VERSION "2021.24.4"

NS_ :

BS_:

BU_: VEH CH Receiver X

BO_ 861 IBST_alertMatrix: 8 CH
 SG_ IBST_matrixIndex M: 0|4@1+ (1,0) [0|0] "" X
 SG_ IBST_a001_microSupplyError m0: 4|1@1+ (1,0) [0|0] "" X
 SG_ IBST_a002_HWBISTError m0: 5|1@1+ (1,0) [0|0] "" X
 SG_ IBST_a003_RAMFault m0: 6|1@1+ (1,0) [0|0] "" X
 SG_ IBST_a004_flashFault m0: 7|1@1+ (1,0) [0|0] "" X
 SG_ IBST_a005_microSafetyFault m0: 8|1@1+ (1,0) [0|0] "" X
 SG_ IBST_a006_microSafetyLogicFault m0: 9|1@1+ (1,0) [0|0] "" X
 SG_ IBST_a007_RBCPUException m0: 10|1@1+ (1,0) [0|0] "" X
 SG_ IBST_a008_stackOverUnderFlow m0: 11|1@1+ (1,0) [0|0] "" X
 SG_ IBST_a009_systemErrorHook m0: 12|1@1+ (1,0) [0|0] "" X
 SG_ IBST_a010_OSErrorHook m0: 13|1@1+ (1,0) [0|0] "" X
 SG_ IBST_a011_systemTaskOverRun m0: 14|1@1+ (1,0) [0|0] "" X
 SG_ IBST_a012_OSTaskSchemeError m0: 15|1@1+ (1,0) [0|0] "" X
 SG_ IBST_a013_systemTaskJitter m0: 16|1@1+ (1,0) [0|0] "" X
 SG_ IBST_a014_DMATransferError m0: 17|1@1+ (1,0) [0|0] "" X
 SG_ IBST_a015_asicOscillatorError m0: 18|1@1+ (1,0) [0|0] "" X
 SG_ IBST_a016_RBBLMShaftShiftError m0: 19|1@1+ (1,0) [0|0] "" X
 SG_ IBST_a017_assertionFault m0: 20|1@1+ (1,0) [0|0] "" X
 SG_ IBST_a018_unsupportedHW m0: 21|1@1+ (1,0) [0|0] "" X
 SG_ IBST_a019_supplyASICInitFault m0: 22|1@1+ (1,0) [0|0] "" X
 SG_ IBST_a020_VPREU5VOutOfRange m0: 23|1@1+ (1,0) [0|0] "" X
 SG_ IBST_a021_IREFOutOfRange m0: 24|1@1+ (1,0) [0|0] "" X
 SG_ IBST_a022_U5VTestFault m0: 25|1@1+ (1,0) [0|0] "" X
 SG_ IBST_a023_U5VOutOfRange m0: 26|1@1+ (1,0) [0|0] "" X
 SG_ IBST_a024_chargePumpFault m0: 27|1@1+ (1,0) [0|0] "" X
 SG_ IBST_a025_ecuClockTestFault m0: 28|1@1+ (1,0) [0|0] "" X
 SG_ IBST_a026_ecuBistCmdTestFault m0: 29|1@1+ (1,0) [0|0] "" X
 SG_ IBST_a027_ecuFastWdTestFault m0: 30|1@1+ (1,0) [0|0] "" X
 SG_ IBST_a028_ecuBistFaultCtrFault m0: 31|1@1+ (1,0) [0|0] "" X
 SG_ IBST_a029_ecuErrpinCounterFault m0: 32|1@1+ (1,0) [0|0] "" X
 SG_ IBST_a030_ecuEnableElLowFault m0: 33|1@1+ (1,0) [0|0] "" X
 SG_ IBST_a031_decoupleBitTestFault m0: 34|1@1+ (1,0) [0|0] "" X
 SG_ IBST_a032_ecuEnableElHighFault m0: 35|1@1+ (1,0) [0|0] "" X
 SG_ IBST_a033_ecuWdStartuptestFault m0: 36|1@1+ (1,0) [0|0] "" X
 SG_ IBST_a034_ecuEnableHyHighFault m0: 37|1@1+ (1,0) [0|0] "" X
 SG_ IBST_a035_ecuEnableHyLowFault m0: 38|1@1+ (1,0) [0|0] "" X
 SG_ IBST_a036_MRGPathTestFault m0: 39|1@1+ (1,0) [0|0] "" X
 SG_ IBST_a037_ecuWdSContinuousError m0: 40|1@1+ (1,0) [0|0] "" X
 SG_ IBST_a038_ecuEnContinuousError m0: 41|1@1+ (1,0) [0|0] "" X
 SG_ IBST_a039_GTMRefFrequencyError m0: 42|1@1+ (1,0) [0|0] "" X
 SG_ IBST_a040_GTMTbuMonError m0: 43|1@1+ (1,0) [0|0] "" X
 SG_ IBST_a041_micAsicClkInError m0: 44|1@1+ (1,0) [0|0] "" X
 SG_ IBST_a042_micAsicInitTestError m0: 45|1@1+ (1,0) [0|0] "" X
 SG_ IBST_a043_micSpiTransferError m0: 46|1@1+ (1,0) [0|0] "" X
 SG_ IBST_a044_NvMEepromWIP m0: 47|1@1+ (1,0) [0|0] "" X
 SG_ IBST_a045_WdhAsicWdErrorCntStuck m0: 48|1@1+ (1,0) [0|0] "" X
 SG_ IBST_a046_WdhAsicWdErrorCntLimit m0: 49|1@1+ (1,0) [0|0] "" X
 SG_ IBST_a047_WdhAsicWdCmdMissing m0: 50|1@1+ (1,0) [0|0] "" X
 SG_ IBST_a048_WdhSwBistConCnt m0: 51|1@1+ (1,0) [0|0] "" X
 SG_ IBST_a049_WdhTaskMonConCnt m0: 52|1@1+ (1,0) [0|0] "" X
 SG_ IBST_a050_VPreExternalFeeding m0: 53|1@1+ (1,0) [0|0] "" X
 SG_ IBST_a051_ecuBandgap m0: 54|1@1+ (1,0) [0|0] "" X
 SG_ IBST_a052_AdcPinTest m0: 55|1@1+ (1,0) [0|0] "" X
 SG_ IBST_a053_AdcSelftestC5P m0: 56|1@1+ (1,0) [0|0] "" X
 SG_ IBST_a054_AdcPeripheralFault m0: 57|1@1+ (1,0) [0|0] "" X
 SG_ IBST_a055_UB6SupplyPathFault m0: 58|1@1+ (1,0) [0|0] "" X
 SG_ IBST_a056_UB6PlausiMonFault m0: 59|1@1+ (1,0) [0|0] "" X
 SG_ IBST_a057_microRegisterFault m0: 60|1@1+ (1,0) [0|0] "" X
 SG_ IBST_a058_NvMWriteCycleExceed m0: 61|1@1+ (1,0) [0|0] "" X
 SG_ IBST_a059_NvMEepromSize m0: 62|1@1+ (1,0) [0|0] "" X
 SG_ IBST_a060_NvMMigrationFault m0: 63|1@1+ (1,0) [0|0] "" X
 SG_ IBST_a061_AswSystemTimeOut m1: 4|1@1+ (1,0) [0|0] "" X
 SG_ IBST_a062_MICB6TransferError m1: 5|1@1+ (1,0) [0|0] "" X
 SG_ IBST_a063_tempSens2ShortToSupply m1: 6|1@1+ (1,0) [0|0] "" X
 SG_ IBST_a064_tempSens1ShortToGround m1: 7|1@1+ (1,0) [0|0] "" X
 SG_ IBST_a065_tempSens2ShortToGround m1: 8|1@1+ (1,0) [0|0] "" X
 SG_ IBST_a066_tempSens1ShortToSupply m1: 9|1@1+ (1,0) [0|0] "" X
 SG_ IBST_a067_tempSensImplausVoltage m1: 10|1@1+ (1,0) [0|0] "" X
 SG_ IBST_a068_chargePumpUndervoltage m1: 11|1@1+ (1,0) [0|0] "" X
 SG_ IBST_a069_greasingRoutineFault m1: 12|1@1+ (1,0) [0|0] "" X
 SG_ IBST_a070_notShutDownNvMWrite m1: 13|1@1+ (1,0) [0|0] "" X
 SG_ IBST_a071_notShutDownNvMRead m1: 14|1@1+ (1,0) [0|0] "" X
 SG_ IBST_a072_notShutDownRight m1: 15|1@1+ (1,0) [0|0] "" X
 SG_ IBST_a073_jumpInAdjustNvMRead m1: 16|1@1+ (1,0) [0|0] "" X
 SG_ IBST_a074_FindIdleDataNvMWrite m1: 17|1@1+ (1,0) [0|0] "" X
 SG_ IBST_a075_FindIdleRoutineFault m1: 18|1@1+ (1,0) [0|0] "" X
 SG_ IBST_a076_masterCylLengthRead m1: 19|1@1+ (1,0) [0|0] "" X
 SG_ IBST_a077_runOutMotorSaturated m1: 20|1@1+ (1,0) [0|0] "" X
 SG_ IBST_a078_wearOffsetCompNVMRead m1: 21|1@1+ (1,0) [0|0] "" X
 SG_ IBST_a079_motorTempHighLevel1 m1: 22|1@1+ (1,0) [0|0] "" X
 SG_ IBST_a080_motorTempHighLevel2 m1: 23|1@1+ (1,0) [0|0] "" X
 SG_ IBST_a081_travelDeviation m1: 24|1@1+ (1,0) [0|0] "" X
 SG_ IBST_a082_motorSpeedDeviation m1: 25|1@1+ (1,0) [0|0] "" X
 SG_ IBST_a083_spindlePositionTooHigh m1: 26|1@1+ (1,0) [0|0] "" X
 SG_ IBST_a084_CANTransceiverHWFault m1: 27|1@1+ (1,0) [0|0] "" X
 SG_ IBST_a085_supplyUndervoltageLvl3 m1: 28|1@1+ (1,0) [0|0] "" X
 SG_ IBST_a086_supplyOvervoltageLvl3 m1: 29|1@1+ (1,0) [0|0] "" X
 SG_ IBST_a087_rotorSinOutOfRangeLow m1: 30|1@1+ (1,0) [0|0] "" X
 SG_ IBST_a088_rotorCosOutOfRangeLow m1: 31|1@1+ (1,0) [0|0] "" X
 SG_ IBST_a089_rotorSinOutOfRangeHigh m1: 32|1@1+ (1,0) [0|0] "" X
 SG_ IBST_a090_rotorCosOutOfRangeHigh m1: 33|1@1+ (1,0) [0|0] "" X
 SG_ IBST_a091_SMMOneRequestsInit m1: 34|1@1+ (1,0) [0|0] "" X
 SG_ IBST_a092_systemStartTimeOut m1: 35|1@1+ (1,0) [0|0] "" X
 SG_ IBST_a093_UEXSOvertemperature m1: 36|1@1+ (1,0) [0|0] "" X
 SG_ IBST_a094_XPASSEchoTimeDeviation m1: 37|1@1+ (1,0) [0|0] "" X
 SG_ IBST_a095_XPASSTimeOut m1: 38|1@1+ (1,0) [0|0] "" X
 SG_ IBST_a096_bridgeDriverMonError m1: 39|1@1+ (1,0) [0|0] "" X
 SG_ IBST_a097_bridgeDriverError m1: 40|1@1+ (1,0) [0|0] "" X
 SG_ IBST_a098_bridgeShortedPhase m1: 41|1@1+ (1,0) [0|0] "" X
 SG_ IBST_a099_bridgeSwitchInitError m1: 42|1@1+ (1,0) [0|0] "" X
 SG_ IBST_a100_current2OffsVEHigh m1: 43|1@1+ (1,0) [0|0] "" X
 SG_ IBST_a101_current2OffsetLow m1: 44|1@1+ (1,0) [0|0] "" X
 SG_ IBST_a102_current1OffsVEHigh m1: 45|1@1+ (1,0) [0|0] "" X
 SG_ IBST_a103_current1OffsetLow m1: 46|1@1+ (1,0) [0|0] "" X
 SG_ IBST_a104_bridgeDriverShort m1: 47|1@1+ (1,0) [0|0] "" X
 SG_ IBST_a105_LiPSUndervoltage m1: 48|1@1+ (1,0) [0|0] "" X
 SG_ IBST_a106_LiPS5VSupply m1: 49|1@1+ (1,0) [0|0] "" X
 SG_ IBST_a107_LiPS2PwmLineHigh m1: 50|1@1+ (1,0) [0|0] "" X
 SG_ IBST_a108_LiPS2PwmLineLow m1: 51|1@1+ (1,0) [0|0] "" X
 SG_ IBST_a109_LiPS2PwmTransmission m1: 52|1@1+ (1,0) [0|0] "" X
 SG_ IBST_a110_LiPS1SentLineHigh m1: 53|1@1+ (1,0) [0|0] "" X
 SG_ IBST_a111_LiPS1SentLineLow m1: 54|1@1+ (1,0) [0|0] "" X
 SG_ IBST_a112_LiPS1SentTransmission m1: 55|1@1+ (1,0) [0|0] "" X
 SG_ IBST_a113_LiPS1SentSensor m1: 56|1@1+ (1,0) [0|0] "" X
 SG_ IBST_a114_partyBusOff m1: 57|1@1+ (1,0) [0|0] "" X
 SG_ IBST_a115_CHOff m1: 58|1@1+ (1,0) [0|0] "" X
 SG_ IBST_a116_supplyUndervoltageLvl2 m1: 59|1@1+ (1,0) [0|0] "" X
 SG_ IBST_a117_supplyOvervoltageLvl2 m1: 60|1@1+ (1,0) [0|0] "" X
 SG_ IBST_a118_RPSNvMReadFault m1: 61|1@1+ (1,0) [0|0] "" X
 SG_ IBST_a119_RPSWrongCalibData m1: 62|1@1+ (1,0) [0|0] "" X
 SG_ IBST_a120_RPSVectorRangeHigh m1: 63|1@1+ (1,0) [0|0] "" X
 SG_ IBST_a121_RPSVectorRangeLow m2: 4|1@1+ (1,0) [0|0] "" X
 SG_ IBST_a122_RPSVectorOscillating m2: 5|1@1+ (1,0) [0|0] "" X
 SG_ IBST_a123_bridgeDriverUnavail m2: 6|1@1+ (1,0) [0|0] "" X
 SG_ IBST_a124_OBDCurrent1OORHigh m2: 7|1@1+ (1,0) [0|0] "" X
 SG_ IBST_a125_OBDCurrent2OORHigh m2: 8|1@1+ (1,0) [0|0] "" X
 SG_ IBST_a126_OBDCurrent1OORLow m2: 9|1@1+ (1,0) [0|0] "" X
 SG_ IBST_a127_OBDCurrent2OORLow m2: 10|1@1+ (1,0) [0|0] "" X
 SG_ IBST_a128_BLMMuxerTimeoutError m2: 11|1@1+ (1,0) [0|0] "" X
 SG_ IBST_a129_loadDumpOnFSLTest m2: 12|1@1+ (1,0) [0|0] "" X
 SG_ IBST_a130_DTSFunctionalRangeLow m2: 13|1@1+ (1,0) [0|0] "" X
 SG_ IBST_a131_DTSFunctionalRangeHigh m2: 14|1@1+ (1,0) [0|0] "" X
 SG_ IBST_a132_DTSPlausiCheck1vs2 m2: 15|1@1+ (1,0) [0|0] "" X
 SG_ IBST_a133_DTSOffsetTooLow m2: 16|1@1+ (1,0) [0|0] "" X
 SG_ IBST_a134_DTSOffsetTooHigh m2: 17|1@1+ (1,0) [0|0] "" X
 SG_ IBST_a135_ESPparty1DLC m2: 18|1@1+ (1,0) [0|0] "" X
 SG_ IBST_a136_ESPparty1Timeout m2: 19|1@1+ (1,0) [0|0] "" X
 SG_ IBST_a137_ESPparty1Checksum m2: 20|1@1+ (1,0) [0|0] "" X
 SG_ IBST_a138_ESPparty1Counter m2: 21|1@1+ (1,0) [0|0] "" X
 SG_ IBST_a139_ESPparty2DLC m2: 22|1@1+ (1,0) [0|0] "" X
 SG_ IBST_a140_ESPparty2Timeout m2: 23|1@1+ (1,0) [0|0] "" X
 SG_ IBST_a141_ESPparty2Checksum m2: 24|1@1+ (1,0) [0|0] "" X
 SG_ IBST_a142_ESPparty2Counter m2: 25|1@1+ (1,0) [0|0] "" X
 SG_ IBST_a143_ESPparty3DLC m2: 26|1@1+ (1,0) [0|0] "" X
 SG_ IBST_a144_ESPparty3Timeout m2: 27|1@1+ (1,0) [0|0] "" X
 SG_ IBST_a145_ESPparty3Checksum m2: 28|1@1+ (1,0) [0|0] "" X
 SG_ IBST_a146_ESPparty3Counter m2: 29|1@1+ (1,0) [0|0] "" X
 SG_ IBST_a147_PSCMotorSizeReadFault m2: 30|1@1+ (1,0) [0|0] "" X
 SG_ IBST_a148_MLIGainMechReadFault m2: 31|1@1+ (1,0) [0|0] "" X
 SG_ IBST_a149_MLITMCAreaReadFault m2: 32|1@1+ (1,0) [0|0] "" X
 SG_ IBST_a150_motorTestFault m2: 33|1@1+ (1,0) [0|0] "" X
 SG_ IBST_a151_PSCGearRatioReadFault m2: 34|1@1+ (1,0) [0|0] "" X
 SG_ IBST_a152_PSCVoltageImplausible m2: 35|1@1+ (1,0) [0|0] "" X
 SG_ IBST_a153_PSCImpedanceTooHigh m2: 36|1@1+ (1,0) [0|0] "" X
 SG_ IBST_a154_PSCImpedanceTooLow m2: 37|1@1+ (1,0) [0|0] "" X
 SG_ IBST_a155_supplyUndervoltageLvl1 m2: 38|1@1+ (1,0) [0|0] "" X
 SG_ IBST_a156_supplyOvervoltageLvl1 m2: 39|1@1+ (1,0) [0|0] "" X
 SG_ IBST_a157_masterCylPressInvalid m2: 40|1@1+ (1,0) [0|0] "" X
 SG_ IBST_a158_DTSOffsHighSuspicious m2: 41|1@1+ (1,0) [0|0] "" X
 SG_ IBST_a159_FindIdleNvMReadError m2: 42|1@1+ (1,0) [0|0] "" X
 SG_ IBST_a160_DTSIDTimeOut m2: 43|1@1+ (1,0) [0|0] "" X
 SG_ IBST_a161_powerPackMismatch m2: 44|1@1+ (1,0) [0|0] "" X
 SG_ IBST_a162_idlePosNotDetected m2: 45|1@1+ (1,0) [0|0] "" X
 SG_ IBST_a163_ESPpEstMaxInvalid m2: 46|1@1+ (1,0) [0|0] "" X
 SG_ IBST_a164_ESPVehicleSpeedInvalid m2: 47|1@1+ (1,0) [0|0] "" X
 SG_ IBST_a165_ESPpForceBlendInvalid m2: 48|1@1+ (1,0) [0|0] "" X
 SG_ IBST_a166_ESPpMcVirtualInvalid m2: 49|1@1+ (1,0) [0|0] "" X
 SG_ IBST_a167_ESPqTargetExterInvalid m2: 50|1@1+ (1,0) [0|0] "" X
 SG_ IBST_a168_CANOvervoltage m2: 51|1@1+ (1,0) [0|0] "" X
 SG_ IBST_a169_CANUndervoltage m2: 52|1@1+ (1,0) [0|0] "" X
 SG_ IBST_a170_LVPowerStateTimeout m2: 53|1@1+ (1,0) [0|0] "" X
 SG_ IBST_a171_LVPowerStateChecksum m2: 54|1@1+ (1,0) [0|0] "" X
 SG_ IBST_a172_LVPowerStateDLC m2: 55|1@1+ (1,0) [0|0] "" X
 SG_ IBST_a173_LVPowerStateCounter m2: 56|1@1+ (1,0) [0|0] "" X
 SG_ IBST_a174_LVOffStateInvalid m2: 57|1@1+ (1,0) [0|0] "" X
 SG_ IBST_a175_LVGoingDownInvalid m2: 58|1@1+ (1,0) [0|0] "" X

BO_ 813 IBST_info: 8 CH
 SG_ IBST_infoIndex M: 0|8@1+ (1,0) [0|0] "" X
 SG_ IBST_infoBuildType m10: 8|8@1+ (1,0) [0|0] "" X
 SG_ IBST_infoComponentID m10: 48|16@1+ (1,0) [0|0] "" X
 SG_ IBST_infoPcbaID m11: 16|8@1+ (1,0) [0|0] "" X
 SG_ IBST_infoAssemblyID m11: 24|8@1+ (1,0) [0|0] "" X
 SG_ IBST_infoUsageID m11: 32|16@1+ (1,0) [0|0] "" X
 SG_ IBST_infoBootUdsProtoVersion m20: 8|8@1+ (1,0) [0|0] "" X
 SG_ IBST_infoBootloaderCRC m20: 32|32@1+ (1,0) [0|0] "" X
 SG_ IBST_infoApplicationCRC m13: 32|32@1+ (1,0) [0|0] "" X
 SG_ IBST_infoVariantCRC m22: 32|32@1+ (1,0) [0|0] "" X

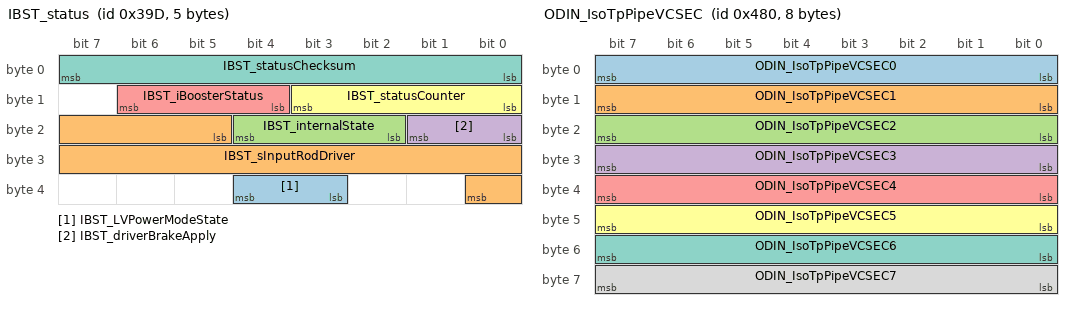
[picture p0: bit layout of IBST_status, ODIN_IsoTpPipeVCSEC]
BO_ 925 IBST_status: 5 Vector__XXX
 SG_ IBST_LVPowerModeState : 35|2@1+ (1,0) [0|0] "" Vector__XXX
 SG_ IBST_sInputRodDriver : 21|12@1+ (0.015625,-5) [0|0] "" Vector__XXX
 SG_ IBST_internalState : 18|3@1+ (1,0) [0|0] "" Vector__XXX
 SG_ IBST_driverBrakeApply : 16|2@1+ (1,0) [0|0] "" Vector__XXX
 SG_ IBST_iBoosterStatus : 12|3@1+ (1,0) [0|0] "" Vector__XXX
 SG_ IBST_statusCounter : 8|4@1+ (1,0) [0|0] "" Vector__XXX
 SG_ IBST_statusChecksum : 0|8@1+ (1,0) [0|0] "" Vector__XXX

BO_ 771 VCRIGHT_info: 8 Vector__XXX
 SG_ VCRIGHT_infoComponentId m10 : 48|16@1+ (1,0) [0|0] "" Vector__XXX
 SG_ VCRIGHT_infoSubUsageId m11 : 40|16@1+ (1,0) [0|0] "" Vector__XXX
 SG_ VCRIGHT_infoHardwareId m10 : 32|16@1+ (1,0) [0|0] "" Vector__XXX
 SG_ VCRIGHT_infoLUMBARRAppCRC m16 : 32|32@1+ (1,0) [0|0] "" Vector__XXX
 SG_ VCRIGHT_infoSubcomponent3 m24 : 32|32@1+ (1,0) [0|0] "" Vector__XXX
 SG_ VCRIGHT_infoSubcomponent4 m31 : 32|32@1+ (1,0) [0|0] "" Vector__XXX
 SG_ VCRIGHT_infoSubcomponent5 m32 : 32|32@1+ (1,0) [0|0] "" Vector__XXX
 SG_ VCRIGHT_infoSubcomponent6 m33 : 32|32@1+ (1,0) [0|0] "" Vector__XXX
 SG_ VCRIGHT_thsAppCRC m23 : 32|32@1+ (1,0) [0|0] "" Vector__XXX
 SG_ VCRIGHT_infoBootCrc m20 : 24|32@1+ (1,0) [0|0] "" Vector__XXX
 SG_ VCRIGHT_infoUsageId m11 : 24|16@1+ (1,0) [0|0] "" Vector__XXX
 SG_ VCRIGHT_infoAssemblyId m11 : 16|8@1+ (1,0) [0|0] "" Vector__XXX
 SG_ VCRIGHT_infoBuildConfigId m10 : 16|16@1+ (1,0) [0|0] "" Vector__XXX
 SG_ VCRIGHT_infoAppCrc m13 : 8|32@1+ (1,0) [0|0] "" Vector__XXX
 SG_ VCRIGHT_infoAppGitHash m17 : 8|56@1+ (1,0) [0|0] "" Vector__XXX
 SG_ VCRIGHT_infoBootGitHash m18 : 8|56@1+ (1,0) [0|0] "" Vector__XXX
 SG_ VCRIGHT_infoBootUdsProtoVersion m20 : 8|16@1+ (1,0) [0|0] "" Vector__XXX
 SG_ VCRIGHT_infoBuildType m10 : 8|3@1+ (1,0) [0|0] "" Vector__XXX
 SG_ VCRIGHT_infoPcbaId m11 : 8|8@1+ (1,0) [0|0] "" Vector__XXX
 SG_ VCRIGHT_infoPlatformType m19 : 8|8@1+ (1,0) [0|0] "" Vector__XXX
 SG_ VCRIGHT_infoIndex M : 0|8@1+ (1,0) [0|0] "" Vector__XXX

BO_ 1152 ODIN_IsoTpPipeVCSEC: 8 VEH
 SG_ ODIN_IsoTpPipeVCSEC0: 0|8@1+ (1,0) [0|0] "" X
 SG_ ODIN_IsoTpPipeVCSEC1: 8|8@1+ (1,0) [0|0] "" X
 SG_ ODIN_IsoTpPipeVCSEC2: 16|8@1+ (1,0) [0|0] "" X
 SG_ ODIN_IsoTpPipeVCSEC3: 24|8@1+ (1,0) [0|0] "" X
 SG_ ODIN_IsoTpPipeVCSEC4: 32|8@1+ (1,0) [0|0] "" X
 SG_ ODIN_IsoTpPipeVCSEC5: 40|8@1+ (1,0) [0|0] "" X
 SG_ ODIN_IsoTpPipeVCSEC6: 48|8@1+ (1,0) [0|0] "" X
 SG_ ODIN_IsoTpPipeVCSEC7: 56|8@1+ (1,0) [0|0] "" X

BO_ 806 PARK_info: 8 CH
 SG_ PARK_infoIndex M: 0|8@1+ (1,0) [0|0] "" X
 SG_ PARK_infoBuildType m10: 8|8@1+ (1,0) [0|0] "" X
 SG_ PARK_infoComponentID m10: 48|16@1+ (1,0) [0|0] "" X
 SG_ PARK_infoPcbaID m11: 16|8@1+ (1,0) [0|0] "" X
 SG_ PARK_infoAssemblyID m11: 24|8@1+ (1,0) [0|0] "" X
 SG_ PARK_infoUsageID m11: 32|16@1+ (1,0) [0|0] "" X
 SG_ PARK_infoBootUdsProtoVersion m20: 8|8@1+ (1,0) [0|0] "" X
 SG_ PARK_infoBootloaderCRC m20: 32|32@1+ (1,0) [0|0] "" X
 SG_ PARK_infoApplicationCRC m13: 32|32@1+ (1,0) [0|0] "" X

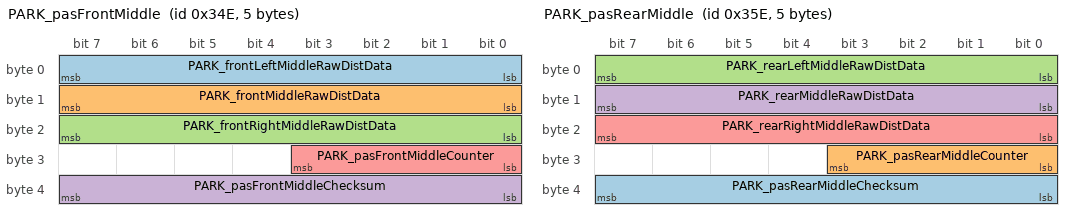
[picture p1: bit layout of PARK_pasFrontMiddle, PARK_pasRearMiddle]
BO_ 846 PARK_pasFrontMiddle: 5 CH
 SG_ PARK_frontLeftMiddleRawDistData: 0|8@1+ (1,0) [0|0] "cm" X
 SG_ PARK_frontMiddleRawDistData: 8|8@1+ (1,0) [0|0] "cm" X
 SG_ PARK_frontRightMiddleRawDistData: 16|8@1+ (1,0) [0|0] "cm" X
 SG_ PARK_pasFrontMiddleChecksum: 32|8@1+ (1,0) [0|0] "" X
 SG_ PARK_pasFrontMiddleCounter: 24|4@1+ (1,0) [0|0] "" X

BO_ 862 PARK_pasRearMiddle: 5 CH
 SG_ PARK_pasRearMiddleChecksum: 32|8@1+ (1,0) [0|0] "" X
 SG_ PARK_pasRearMiddleCounter: 24|4@1+ (1,0) [0|0] "" X
 SG_ PARK_rearLeftMiddleRawDistData: 0|8@1+ (1,0) [0|0] "cm" X
 SG_ PARK_rearMiddleRawDistData: 8|8@1+ (1,0) [0|0] "cm" X
 SG_ PARK_rearRightMiddleRawDistData: 16|8@1+ (1,0) [0|0] "cm" X

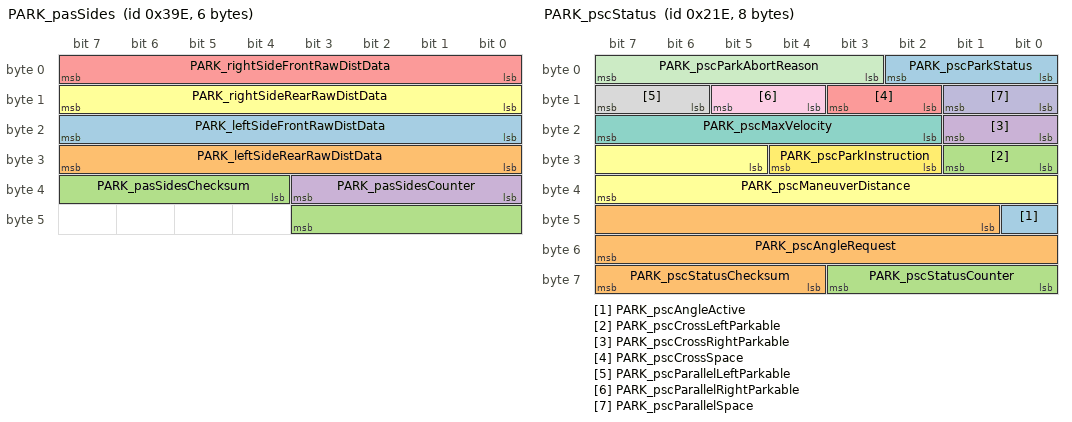
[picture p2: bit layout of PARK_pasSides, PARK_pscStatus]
BO_ 926 PARK_pasSides: 6 CH
 SG_ PARK_leftSideFrontRawDistData: 16|8@1+ (1,0) [0|0] "cm" X
 SG_ PARK_leftSideRearRawDistData: 24|8@1+ (1,0) [0|0] "cm" X
 SG_ PARK_pasSidesChecksum: 36|8@1+ (1,0) [0|0] "" X
 SG_ PARK_pasSidesCounter: 32|4@1+ (1,0) [0|0] "" X
 SG_ PARK_rightSideFrontRawDistData: 0|8@1+ (1,0) [0|0] "cm" X
 SG_ PARK_rightSideRearRawDistData: 8|8@1+ (1,0) [0|0] "cm" X

BO_ 606 PARK_pscEnvSlot: 8 CH
 SG_ PARK_pscEnvSlotType M: 0|2@1+ (1,0) [0|0] "" X
 SG_ PARK_pscLeftParallelObj1X m0: 3|11@1+ (2,-2048) [0|0] "cm" X
 SG_ PARK_pscLeftParallelObj1Y m0: 14|11@1+ (2,-2048) [0|0] "cm" X
 SG_ PARK_pscLeftParallelObj1Alpha m0: 25|7@1+ (2,-128) [0|0] "deg" X
 SG_ PARK_pscLeftParallelObj2Y m0: 35|11@1+ (2,-2048) [0|0] "cm" X
 SG_ PARK_pscLeftParallelObj2X m0: 46|11@1+ (2,-2048) [0|0] "cm" X
 SG_ PARK_pscLeftParallelObj2Alpha m0: 57|7@1+ (2,-128) [0|0] "deg" X
 SG_ PARK_pscLeftCrossObj1X m1: 3|11@1+ (2,-2048) [0|0] "cm" X
 SG_ PARK_pscLeftCrossObj1Y m1: 14|11@1+ (2,-2048) [0|0] "cm" X
 SG_ PARK_pscLeftCrossObj1Alpha m1: 25|7@1+ (2,-128) [0|0] "deg" X
 SG_ PARK_pscLeftCrossObj2Y m1: 35|11@1+ (2,-2048) [0|0] "cm" X
 SG_ PARK_pscLeftCrossObj2X m1: 46|11@1+ (2,-2048) [0|0] "cm" X
 SG_ PARK_pscLeftCrossObj2Alpha m1: 57|7@1+ (2,-128) [0|0] "deg" X
 SG_ PARK_pscRightParallelObj1X m2: 3|11@1+ (2,-2048) [0|0] "cm" X
 SG_ PARK_pscRightParallelObj1Y m2: 14|11@1+ (2,-2048) [0|0] "cm" X
 SG_ PARK_pscRightParallelObj1Alpha m2: 25|7@1+ (2,-128) [0|0] "deg" X
 SG_ PARK_pscRightParallelObj2Y m2: 35|11@1+ (2,-2048) [0|0] "cm" X
 SG_ PARK_pscRightParallelObj2X m2: 46|11@1+ (2,-2048) [0|0] "cm" X
 SG_ PARK_pscRightParallelObj2Alpha m2: 57|7@1+ (2,-128) [0|0] "deg" X
 SG_ PARK_pscRightCrossObj1X m3: 3|11@1+ (2,-2048) [0|0] "cm" X
 SG_ PARK_pscRightCrossObj1Y m3: 14|11@1+ (2,-2048) [0|0] "cm" X
 SG_ PARK_pscRightCrossObj1Alpha m3: 25|7@1+ (2,-128) [0|0] "deg" X
 SG_ PARK_pscRightCrossObj2Y m3: 35|11@1+ (2,-2048) [0|0] "cm" X
 SG_ PARK_pscRightCrossObj2X m3: 46|11@1+ (2,-2048) [0|0] "cm" X
 SG_ PARK_pscRightCrossObj2Alpha m3: 57|7@1+ (2,-128) [0|0] "deg" X

BO_ 542 PARK_pscStatus: 8 VEH
 SG_ PARK_pscAngleActive: 40|1@1+ (1,0) [0|0] "" X
 SG_ PARK_pscAngleRequest: 41|15@1+ (0.1,-1638.4) [0|0] "deg" X
 SG_ PARK_pscCrossLeftParkable: 24|2@1+ (1,0) [0|0] "" X
 SG_ PARK_pscCrossRightParkable: 16|2@1+ (1,0) [0|0] "" X
 SG_ PARK_pscCrossSpace: 10|2@1+ (1,0) [0|0] "" X
 SG_ PARK_pscManeuverDistance: 29|11@1+ (1,0) [0|0] "cm" X
 SG_ PARK_pscMaxVelocity: 18|6@1+ (0.1,0) [0|0] "kph" X
 SG_ PARK_pscParallelLeftParkable: 14|2@1+ (1,0) [0|0] "" X
 SG_ PARK_pscParallelRightParkable: 12|2@1+ (1,0) [0|0] "" X
 SG_ PARK_pscParallelSpace: 8|2@1+ (1,0) [0|0] "" X
 SG_ PARK_pscParkAbortReason: 3|5@1+ (1,0) [0|0] "" X
 SG_ PARK_pscParkInstruction: 26|3@1+ (1,0) [0|0] "" X
 SG_ PARK_pscParkStatus: 0|3@1+ (1,0) [0|0] "" X
 SG_ PARK_pscStatusChecksum: 60|4@1+ (1,0) [0|0] "" X
 SG_ PARK_pscStatusCounter: 56|4@1+ (1,0) [0|0] "" X

BO_ 590 PARK_pscVehSlot: 8 CH
 SG_ PARK_pscVehSlotType M: 0|2@1+ (1,0) [0|0] "" X
 SG_ PARK_pscLeftParallelVehX m0: 5|11@1+ (2,-2048) [0|0] "cm" X
 SG_ PARK_pscLeftParallelVehY m0: 16|11@1+ (2,-2048) [0|0] "cm" X
 SG_ PARK_pscLeftParallelPsi m0: 32|13@1+ (0.000976563,0) [0|0] "radians" X
 SG_ PARK_pscLeftParallelSizeX m0: 48|8@1+ (4,0) [0|0] "cm" X
 SG_ PARK_pscLeftParallelSizeY m0: 56|8@1+ (4,0) [0|0] "cm" X
 SG_ PARK_pscLeftCrossVehX m1: 5|11@1+ (2,-2048) [0|0] "cm" X
 SG_ PARK_pscLeftCrossVehY m1: 16|11@1+ (2,-2048) [0|0] "cm" X
 SG_ PARK_pscLeftCrossPsi m1: 32|13@1+ (0.000976563,0) [0|0] "radians" X
 SG_ PARK_pscLeftCrossSizeX m1: 48|8@1+ (4,0) [0|0] "cm" X
 SG_ PARK_pscLeftCrossSizeY m1: 56|8@1+ (4,0) [0|0] "cm" X
 SG_ PARK_pscRightParallelVehX m2: 5|11@1+ (2,-2048) [0|0] "cm" X
 SG_ PARK_pscRightParallelVehY m2: 16|11@1+ (2,-2048) [0|0] "cm" X
 SG_ PARK_pscRightParallelPsi m2: 32|13@1+ (0.000976563,0) [0|0] "radians" X
 SG_ PARK_pscRightParallelSizeX m2: 48|8@1+ (4,0) [0|0] "cm" X
 SG_ PARK_pscRightParallelSizeY m2: 56|8@1+ (4,0) [0|0] "cm" X
 SG_ PARK_pscRightCrossVehX m3: 5|11@1+ (2,-2048) [0|0] "cm" X
 SG_ PARK_pscRightCrossVehY m3: 16|11@1+ (2,-2048) [0|0] "cm" X
 SG_ PARK_pscRightCrossPsi m3: 32|13@1+ (0.000976563,0) [0|0] "radians" X
 SG_ PARK_pscRightCrossSizeX m3: 48|8@1+ (4,0) [0|0] "cm" X
 SG_ PARK_pscRightCrossSizeY m3: 56|8@1+ (4,0) [0|0] "cm" X

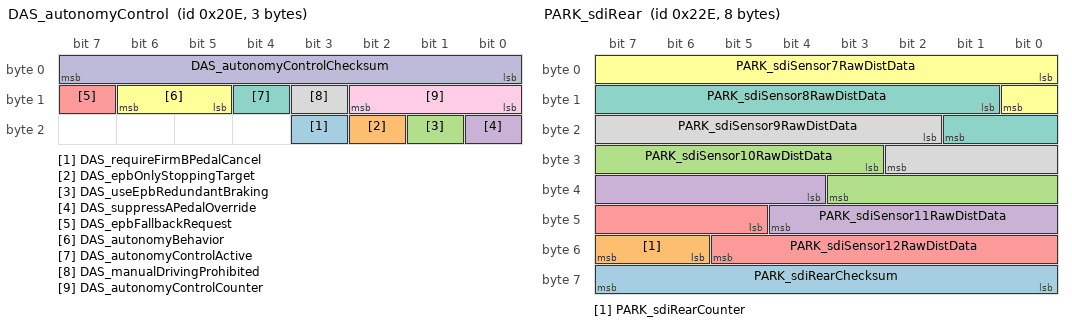
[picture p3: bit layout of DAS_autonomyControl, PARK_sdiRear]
BO_ 526 DAS_autonomyControl: 3 Vector__XXX
 SG_ DAS_requireFirmBPedalCancel : 19|1@1+ (1,0) [0|0] "" Vector__XXX
 SG_ DAS_epbOnlyStoppingTarget : 18|1@1+ (1,0) [0|0] "" Vector__XXX
 SG_ DAS_useEpbRedundantBraking : 17|1@1+ (1,0) [0|0] "" Vector__XXX
 SG_ DAS_suppressAPedalOverride : 16|1@1+ (1,0) [0|0] "" Vector__XXX
 SG_ DAS_epbFallbackRequest : 15|1@1+ (1,0) [0|0] "" Vector__XXX
 SG_ DAS_autonomyBehavior : 13|2@1+ (1,0) [0|0] "" Vector__XXX
 SG_ DAS_autonomyControlActive : 12|1@1+ (1,0) [0|0] "" Vector__XXX
 SG_ DAS_manualDrivingProhibited : 11|1@1+ (1,0) [0|0] "" Vector__XXX
 SG_ DAS_autonomyControlCounter : 8|3@1+ (1,0) [0|0] "" Vector__XXX
 SG_ DAS_autonomyControlChecksum : 0|8@1+ (1,0) [0|0] "" Vector__XXX

BO_ 558 PARK_sdiRear: 8 CH
 SG_ PARK_sdiRearChecksum: 56|8@1+ (1,0) [0|0] "" X
 SG_ PARK_sdiRearCounter: 54|2@1+ (1,0) [0|0] "" X
 SG_ PARK_sdiSensor10RawDistData: 27|9@1+ (1,0) [0|0] "cm" X
 SG_ PARK_sdiSensor11RawDistData: 36|9@1+ (1,0) [0|0] "cm" X
 SG_ PARK_sdiSensor12RawDistData: 45|9@1+ (1,0) [0|0] "cm" X
 SG_ PARK_sdiSensor7RawDistData: 0|9@1+ (1,0) [0|0] "cm" X
 SG_ PARK_sdiSensor8RawDistData: 9|9@1+ (1,0) [0|0] "cm" X
 SG_ PARK_sdiSensor9RawDistData: 18|9@1+ (1,0) [0|0] "cm" X

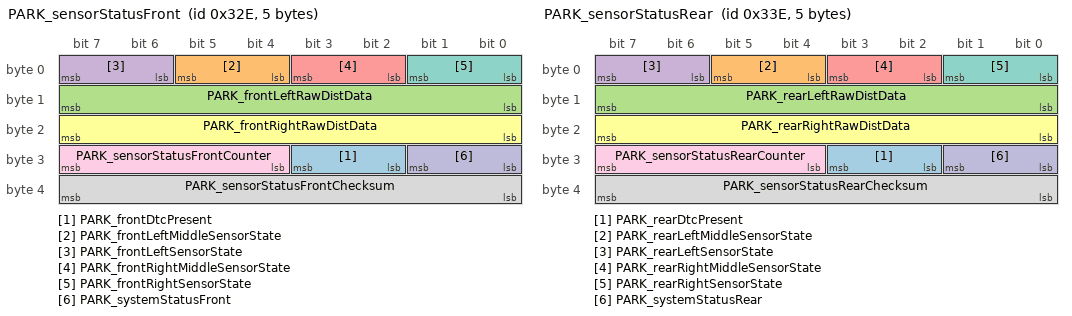
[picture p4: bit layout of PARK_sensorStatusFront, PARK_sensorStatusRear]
BO_ 814 PARK_sensorStatusFront: 5 CH
 SG_ PARK_frontDtcPresent: 26|2@1+ (1,0) [0|0] "" X
 SG_ PARK_frontLeftMiddleSensorState: 4|2@1+ (1,0) [0|0] "" X
 SG_ PARK_frontLeftRawDistData: 8|8@1+ (1,0) [0|0] "cm" X
 SG_ PARK_frontLeftSensorState: 6|2@1+ (1,0) [0|0] "" X
 SG_ PARK_frontRightMiddleSensorState: 2|2@1+ (1,0) [0|0] "" X
 SG_ PARK_frontRightRawDistData: 16|8@1+ (1,0) [0|0] "cm" X
 SG_ PARK_frontRightSensorState: 0|2@1+ (1,0) [0|0] "" X
 SG_ PARK_sensorStatusFrontChecksum: 32|8@1+ (1,0) [0|0] "" X
 SG_ PARK_sensorStatusFrontCounter: 28|4@1+ (1,0) [0|0] "" X
 SG_ PARK_systemStatusFront: 24|2@1+ (1,0) [0|0] "" X

BO_ 830 PARK_sensorStatusRear: 5 CH
 SG_ PARK_rearDtcPresent: 26|2@1+ (1,0) [0|0] "" X
 SG_ PARK_rearLeftMiddleSensorState: 4|2@1+ (1,0) [0|0] "" X
 SG_ PARK_rearLeftRawDistData: 8|8@1+ (1,0) [0|0] "cm" X
 SG_ PARK_rearLeftSensorState: 6|2@1+ (1,0) [0|0] "" X
 SG_ PARK_rearRightMiddleSensorState: 2|2@1+ (1,0) [0|0] "cm" X
 SG_ PARK_rearRightRawDistData: 16|8@1+ (1,0) [0|0] "cm" X
 SG_ PARK_rearRightSensorState: 0|2@1+ (1,0) [0|0] "" X
 SG_ PARK_sensorStatusRearChecksum: 32|8@1+ (1,0) [0|0] "" X
 SG_ PARK_sensorStatusRearCounter: 28|4@1+ (1,0) [0|0] "" X
 SG_ PARK_systemStatusRear: 24|2@1+ (1,0) [0|0] "" X

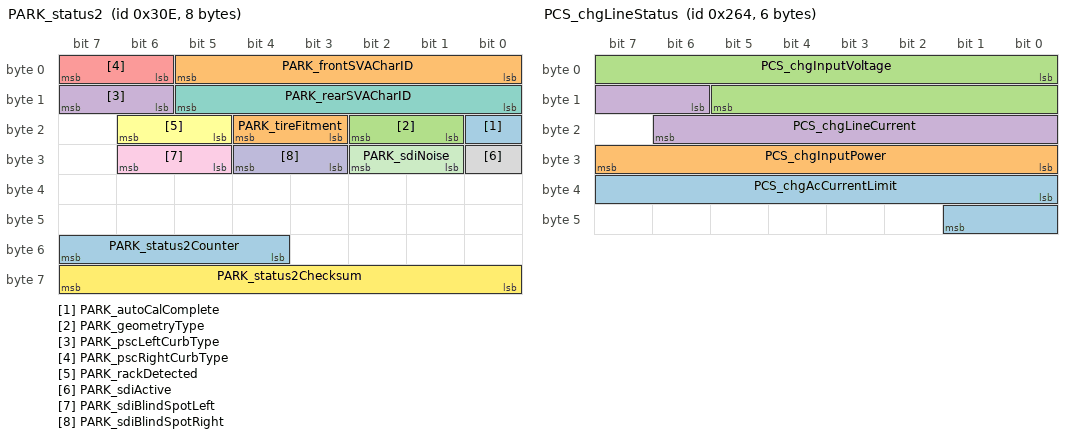
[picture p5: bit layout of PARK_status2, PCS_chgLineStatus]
BO_ 782 PARK_status2: 8 CH
 SG_ PARK_autoCalComplete: 16|1@1+ (1,0) [0|0] "" X
 SG_ PARK_frontSVACharID: 0|6@1+ (1,0) [0|0] "" X
 SG_ PARK_geometryType: 17|2@1+ (1,0) [0|0] "" X
 SG_ PARK_pscLeftCurbType: 14|2@1+ (1,0) [0|0] "" X
 SG_ PARK_pscRightCurbType: 6|2@1+ (1,0) [0|0] "" X
 SG_ PARK_rackDetected: 21|2@1+ (1,0) [0|0] "" X
 SG_ PARK_rearSVACharID: 8|6@1+ (1,0) [0|0] "" X
 SG_ PARK_sdiActive: 24|1@1+ (1,0) [0|0] "" X
 SG_ PARK_sdiBlindSpotLeft: 29|2@1+ (1,0) [0|0] "" X
 SG_ PARK_sdiBlindSpotRight: 27|2@1+ (1,0) [0|0] "" X
 SG_ PARK_sdiNoise: 25|2@1+ (1,0) [0|0] "" X
 SG_ PARK_status2Checksum: 56|8@1+ (1,0) [0|0] "" X
 SG_ PARK_status2Counter: 52|4@1+ (1,0) [0|0] "" X
 SG_ PARK_tireFitment: 19|2@1+ (1,0) [0|0] "" X

BO_ 894 PARK_warningMatrix: 8 CH
 SG_ PARK_matrixIndex M: 0|4@1+ (1,0) [0|0] "" X
 SG_ PARK_a001_s1_overTemp m0: 4|1@1+ (1,0) [0|0] "" X
 SG_ PARK_a002_s1_internalFail m0: 5|1@1+ (1,0) [0|0] "" X
 SG_ PARK_a003_s1_linCommError m0: 6|1@1+ (1,0) [0|0] "" X
 SG_ PARK_a004_s1_blocked m0: 7|1@1+ (1,0) [0|0] "" X
 SG_ PARK_a005_s1_crossTalk m0: 8|1@1+ (1,0) [0|0] "" X
 SG_ PARK_a006_s2_overTemp m0: 9|1@1+ (1,0) [0|0] "" X
 SG_ PARK_a007_s2_internalFail m0: 10|1@1+ (1,0) [0|0] "" X
 SG_ PARK_a008_s2_linCommError m0: 11|1@1+ (1,0) [0|0] "" X
 SG_ PARK_a009_s2_blocked m0: 12|1@1+ (1,0) [0|0] "" X
 SG_ PARK_a010_s2_crossTalk m0: 13|1@1+ (1,0) [0|0] "" X
 SG_ PARK_a011_s3_overTemp m0: 14|1@1+ (1,0) [0|0] "" X
 SG_ PARK_a012_s3_internalFail m0: 15|1@1+ (1,0) [0|0] "" X
 SG_ PARK_a013_s3_linCommError m0: 16|1@1+ (1,0) [0|0] "" X
 SG_ PARK_a014_s3_blocked m0: 17|1@1+ (1,0) [0|0] "" X
 SG_ PARK_a015_s3_crossTalk m0: 18|1@1+ (1,0) [0|0] "" X
 SG_ PARK_a016_s4_overTemp m0: 19|1@1+ (1,0) [0|0] "" X
 SG_ PARK_a017_s4_internalFail m0: 20|1@1+ (1,0) [0|0] "" X
 SG_ PARK_a018_s4_linCommError m0: 21|1@1+ (1,0) [0|0] "" X
 SG_ PARK_a019_s4_blocked m0: 22|1@1+ (1,0) [0|0] "" X
 SG_ PARK_a020_s4_crossTalk m0: 23|1@1+ (1,0) [0|0] "" X
 SG_ PARK_a021_s5_overTemp m0: 24|1@1+ (1,0) [0|0] "" X
 SG_ PARK_a022_s5_internalFail m0: 25|1@1+ (1,0) [0|0] "" X
 SG_ PARK_a023_s5_linCommError m0: 26|1@1+ (1,0) [0|0] "" X
 SG_ PARK_a024_s5_blocked m0: 27|1@1+ (1,0) [0|0] "" X
 SG_ PARK_a025_s5_crossTalk m0: 28|1@1+ (1,0) [0|0] "" X
 SG_ PARK_a026_s6_overTemp m0: 29|1@1+ (1,0) [0|0] "" X
 SG_ PARK_a027_s6_internalFail m0: 30|1@1+ (1,0) [0|0] "" X
 SG_ PARK_a028_s6_linCommError m0: 31|1@1+ (1,0) [0|0] "" X
 SG_ PARK_a029_s6_blocked m0: 32|1@1+ (1,0) [0|0] "" X
 SG_ PARK_a030_s6_crossTalk m0: 33|1@1+ (1,0) [0|0] "" X
 SG_ PARK_a031_s7_overTemp m0: 34|1@1+ (1,0) [0|0] "" X
 SG_ PARK_a032_s7_internalFail m0: 35|1@1+ (1,0) [0|0] "" X
 SG_ PARK_a033_s7_linCommError m0: 36|1@1+ (1,0) [0|0] "" X
 SG_ PARK_a034_s7_blocked m0: 37|1@1+ (1,0) [0|0] "" X
 SG_ PARK_a035_s7_crossTalk m0: 38|1@1+ (1,0) [0|0] "" X
 SG_ PARK_a036_s8_overTemp m0: 39|1@1+ (1,0) [0|0] "" X
 SG_ PARK_a037_s8_internalFail m0: 40|1@1+ (1,0) [0|0] "" X
 SG_ PARK_a038_s8_linCommError m0: 41|1@1+ (1,0) [0|0] "" X
 SG_ PARK_a039_s8_blocked m0: 42|1@1+ (1,0) [0|0] "" X
 SG_ PARK_a040_s8_crossTalk m0: 43|1@1+ (1,0) [0|0] "" X
 SG_ PARK_a041_s9_overTemp m0: 44|1@1+ (1,0) [0|0] "" X
 SG_ PARK_a042_s9_internalFail m0: 45|1@1+ (1,0) [0|0] "" X
 SG_ PARK_a043_s9_linCommError m0: 46|1@1+ (1,0) [0|0] "" X
 SG_ PARK_a044_s9_blocked m0: 47|1@1+ (1,0) [0|0] "" X
 SG_ PARK_a045_s9_crossTalk m0: 48|1@1+ (1,0) [0|0] "" X
 SG_ PARK_a046_s10_overTemp m0: 49|1@1+ (1,0) [0|0] "" X
 SG_ PARK_a047_s10_internalFail m0: 50|1@1+ (1,0) [0|0] "" X
 SG_ PARK_a048_s10_linCommError m0: 51|1@1+ (1,0) [0|0] "" X
 SG_ PARK_a049_s10_blocked m0: 52|1@1+ (1,0) [0|0] "" X
 SG_ PARK_a050_s10_crossTalk m0: 53|1@1+ (1,0) [0|0] "" X
 SG_ PARK_a051_s11_overTemp m0: 54|1@1+ (1,0) [0|0] "" X
 SG_ PARK_a052_s11_internalFail m0: 55|1@1+ (1,0) [0|0] "" X
 SG_ PARK_a053_s11_linCommError m0: 56|1@1+ (1,0) [0|0] "" X
 SG_ PARK_a054_s11_blocked m0: 57|1@1+ (1,0) [0|0] "" X
 SG_ PARK_a055_s11_crossTalk m0: 58|1@1+ (1,0) [0|0] "" X
 SG_ PARK_a056_s12_overTemp m0: 59|1@1+ (1,0) [0|0] "" X
 SG_ PARK_a057_s12_internalFail m0: 60|1@1+ (1,0) [0|0] "" X
 SG_ PARK_a058_s12_linCommError m0: 61|1@1+ (1,0) [0|0] "" X
 SG_ PARK_a059_s12_blocked m0: 62|1@1+ (1,0) [0|0] "" X
 SG_ PARK_a060_s12_crossTalk m0: 63|1@1+ (1,0) [0|0] "" X
 SG_ PARK_a061_ecuUnderVoltage m1: 4|1@1+ (1,0) [0|0] "" X
 SG_ PARK_a062_ecuOverVoltage m1: 5|1@1+ (1,0) [0|0] "" X
 SG_ PARK_a063_sensorVoltage m1: 6|1@1+ (1,0) [0|0] "" X
 SG_ PARK_a064_ecuFault m1: 7|1@1+ (1,0) [0|0] "" X
 SG_ PARK_a065_crcFault m1: 8|1@1+ (1,0) [0|0] "" X
 SG_ PARK_a066_calibrationMissing m1: 9|1@1+ (1,0) [0|0] "" X
 SG_ PARK_a067_privateCANBusOff m1: 10|1@1+ (1,0) [0|0] "" X
 SG_ PARK_a068_hardwareWatchDog m1: 11|1@1+ (1,0) [0|0] "" X
 SG_ PARK_a069_dasMia m1: 12|1@1+ (1,0) [0|0] "" X
 SG_ PARK_a070_sccmMia m1: 13|1@1+ (1,0) [0|0] "" X
 SG_ PARK_a071_diMia m1: 14|1@1+ (1,0) [0|0] "" X
 SG_ PARK_a072_epasMia m1: 15|1@1+ (1,0) [0|0] "" X
 SG_ PARK_a073_epbMia m1: 16|1@1+ (1,0) [0|0] "" X
 SG_ PARK_a074_espMia m1: 17|1@1+ (1,0) [0|0] "" X
 SG_ PARK_a075_rcmMia m1: 18|1@1+ (1,0) [0|0] "" X
 SG_ PARK_a076_vcFrontMia m1: 19|1@1+ (1,0) [0|0] "" X
 SG_ PARK_a077_dasError m1: 20|1@1+ (1,0) [0|0] "" X
 SG_ PARK_a078_diError m1: 21|1@1+ (1,0) [0|0] "" X
 SG_ PARK_a079_epasError m1: 22|1@1+ (1,0) [0|0] "" X
 SG_ PARK_a080_epbError m1: 23|1@1+ (1,0) [0|0] "" X
 SG_ PARK_a081_espError m1: 24|1@1+ (1,0) [0|0] "" X
 SG_ PARK_a082_rcmError m1: 25|1@1+ (1,0) [0|0] "" X
 SG_ PARK_a083_vcFrontError m1: 26|1@1+ (1,0) [0|0] "" X
 SG_ PARK_a084_sccmError m1: 27|1@1+ (1,0) [0|0] "" X
 SG_ PARK_a085_watchdogReset m1: 28|1@1+ (1,0) [0|0] "" X
 SG_ PARK_a086_nvmFault m1: 29|1@1+ (1,0) [0|0] "" X

BO_ 932 PCS_alertMatrix: 8 VEH
 SG_ PCS_matrixIndex M: 0|4@1+ (1,0) [0|0] "" X
 SG_ PCS_a001_chgHwInputOc m0: 4|1@1+ (1,0) [0|0] "" X
 SG_ PCS_a002_chgHwOutputOc m0: 5|1@1+ (1,0) [0|0] "" X
 SG_ PCS_a003_chgHwInputOv m0: 6|1@1+ (1,0) [0|0] "" X
 SG_ PCS_a004_chgHwIntBusOv m0: 7|1@1+ (1,0) [0|0] "" X
 SG_ PCS_a005_chgOutputOv m0: 8|1@1+ (1,0) [0|0] "" X
 SG_ PCS_a006_chgPrechargeFailedScr m0: 9|1@1+ (1,0) [0|0] "" X
 SG_ PCS_a007_chgPhaseTempHot m0: 10|1@1+ (1,0) [0|0] "" X
 SG_ PCS_a008_chgPhaseOverTemp m0: 11|1@1+ (1,0) [0|0] "" X
 SG_ PCS_a009_chgPfcCurrentRegulation m0: 12|1@1+ (1,0) [0|0] "" X
 SG_ PCS_a010_chgIntBusVRegulation m0: 13|1@1+ (1,0) [0|0] "" X
 SG_ PCS_a011_chgLlcCurrentRegulation m0: 14|1@1+ (1,0) [0|0] "" X
 SG_ PCS_a012_chgPfcIBandTracerFault m0: 15|1@1+ (1,0) [0|0] "" X
 SG_ PCS_a013_chgPrechargeFailedBoost m0: 16|1@1+ (1,0) [0|0] "" X
 SG_ PCS_a014_chgTempRationality m0: 17|1@1+ (1,0) [0|0] "" X
 SG_ PCS_a015_chg12vUv m0: 18|1@1+ (1,0) [0|0] "" X
 SG_ PCS_a016_chgAllPhasesFaulted m0: 19|1@1+ (1,0) [0|0] "" X
 SG_ PCS_a017_chgWallPowerRemoval m0: 20|1@1+ (1,0) [0|0] "" X
 SG_ PCS_a018_chgUnknownGridConfig m0: 21|1@1+ (1,0) [0|0] "" X
 SG_ PCS_a019_acChargePowerLimited m0: 22|1@1+ (1,0) [0|0] "" X
 SG_ PCS_a020_chgEnableLineMismatch m0: 23|1@1+ (1,0) [0|0] "" X
 SG_ PCS_a021_hvpMia m0: 24|1@1+ (1,0) [0|0] "" X
 SG_ PCS_a022_bmsMia m0: 25|1@1+ (1,0) [0|0] "" X
 SG_ PCS_a023_cpMia m0: 26|1@1+ (1,0) [0|0] "" X
 SG_ PCS_a024_vcfrontMia m0: 27|1@1+ (1,0) [0|0] "" X
 SG_ PCS_a025_cpu2Malfunction m0: 28|1@1+ (1,0) [0|0] "" X
 SG_ PCS_a026_watchdogAlarmed m0: 29|1@1+ (1,0) [0|0] "" X
 SG_ PCS_a027_chgInsufficientCooling m0: 30|1@1+ (1,0) [0|0] "" X
 SG_ PCS_a028_chgOutputUv m0: 31|1@1+ (1,0) [0|0] "" X
 SG_ PCS_a029_chgPowerRationality m0: 32|1@1+ (1,0) [0|0] "" X
 SG_ PCS_a030_canRationality m0: 33|1@1+ (1,0) [0|0] "" X
 SG_ PCS_a031_uiMia m0: 34|1@1+ (1,0) [0|0] "" X
 SG_ PCS_a032_gtwMia m0: 35|1@1+ (1,0) [0|0] "" X
 SG_ PCS_a033_hvBusUv m0: 36|1@1+ (1,0) [0|0] "" X
 SG_ PCS_a034_hvBusOv m0: 37|1@1+ (1,0) [0|0] "" X
 SG_ PCS_a035_lvBusUv m0: 38|1@1+ (1,0) [0|0] "" X
 SG_ PCS_a036_lvBusOv m0: 39|1@1+ (1,0) [0|0] "" X
 SG_ PCS_a037_resonantTankOc m0: 40|1@1+ (1,0) [0|0] "" X
 SG_ PCS_a038_claFaulted m0: 41|1@1+ (1,0) [0|0] "" X
 SG_ PCS_a039_sdModuleClkFault m0: 42|1@1+ (1,0) [0|0] "" X
 SG_ PCS_a040_dcdcMaxPowerReached m0: 43|1@1+ (1,0) [0|0] "" X
 SG_ PCS_a041_dcdcOverTemp m0: 44|1@1+ (1,0) [0|0] "" X
 SG_ PCS_a042_dcdcEnableLineMismatch m0: 45|1@1+ (1,0) [0|0] "" X
 SG_ PCS_a043_hvBusPrechargeFailure m0: 46|1@1+ (1,0) [0|0] "" X
 SG_ PCS_a044_12vSupportRegulation m0: 47|1@1+ (1,0) [0|0] "" X
 SG_ PCS_a045_hvBusLowImpedance m0: 48|1@1+ (1,0) [0|0] "" X
 SG_ PCS_a046_hvBusHighImpedence m0: 49|1@1+ (1,0) [0|0] "" X
 SG_ PCS_a047_lvBusLowImpedance m0: 50|1@1+ (1,0) [0|0] "" X
 SG_ PCS_a048_lvBusHighImpedance m0: 51|1@1+ (1,0) [0|0] "" X
 SG_ PCS_a049_dcdcTempRationality m0: 52|1@1+ (1,0) [0|0] "" X
 SG_ PCS_a050_dcdc12VsupportFaulted m0: 53|1@1+ (1,0) [0|0] "" X
 SG_ PCS_a051_chgIntBusUv m0: 54|1@1+ (1,0) [0|0] "" X
 SG_ PCS_a052_acVoltageNotPresent m0: 55|1@1+ (1,0) [0|0] "" X
 SG_ PCS_a053_chgInputVDropHigh m0: 56|1@1+ (1,0) [0|0] "" X
 SG_ PCS_a054_chgInputVDropTooHigh m0: 57|1@1+ (1,0) [0|0] "" X
 SG_ PCS_a055_chgLineImedanceHigh m0: 58|1@1+ (1,0) [0|0] "" X
 SG_ PCS_a056_chgLineImedanceTooHigh m0: 59|1@1+ (1,0) [0|0] "" X
 SG_ PCS_a057_chgInputOverFreq m0: 60|1@1+ (1,0) [0|0] "" X
 SG_ PCS_a058_chgInputUnderFreq m0: 61|1@1+ (1,0) [0|0] "" X
 SG_ PCS_a059_chgInputOvRms m0: 62|1@1+ (1,0) [0|0] "" X
 SG_ PCS_a060_chgInputOvPeak m0: 63|1@1+ (1,0) [0|0] "" X
 SG_ PCS_a061_chgVLineRationality m1: 4|1@1+ (1,0) [0|0] "" X
 SG_ PCS_a062_chgILineRationality m1: 5|1@1+ (1,0) [0|0] "" X
 SG_ PCS_a063_chgVOutRationality m1: 6|1@1+ (1,0) [0|0] "" X
 SG_ PCS_a064_chgIOutRationality m1: 7|1@1+ (1,0) [0|0] "" X
 SG_ PCS_a065_chgPllNotLocked m1: 8|1@1+ (1,0) [0|0] "" X
 SG_ PCS_a066_dcdcHvRationality m1: 9|1@1+ (1,0) [0|0] "" X
 SG_ PCS_a067_dcdcLvRationality m1: 10|1@1+ (1,0) [0|0] "" X
 SG_ PCS_a068_dcdcTankvRationality m1: 11|1@1+ (1,0) [0|0] "" X
 SG_ PCS_a069_chgPfcLineDidt m1: 12|1@1+ (1,0) [0|0] "" X
 SG_ PCS_a070_chgPfcLineDvdt m1: 13|1@1+ (1,0) [0|0] "" X
 SG_ PCS_a071_chgPfcILoopRationality m1: 14|1@1+ (1,0) [0|0] "" X
 SG_ PCS_a072_cpu2ClaStopped m1: 15|1@1+ (1,0) [0|0] "" X
 SG_ PCS_a073_unexpectedAcInputVoltage m1: 16|1@1+ (1,0) [0|0] "" X
 SG_ PCS_a074_hvBusDischargeFailure m1: 17|1@1+ (1,0) [0|0] "" X
 SG_ PCS_a075_hvBusDischargeTimeout m1: 18|1@1+ (1,0) [0|0] "" X
 SG_ PCS_a076_dcdcEnDeassertedErr m1: 19|1@1+ (1,0) [0|0] "" X
 SG_ PCS_a077_microGridEnergyLow m1: 20|1@1+ (1,0) [0|0] "" X
 SG_ PCS_a078_chgStopDcdcTooHot m1: 21|1@1+ (1,0) [0|0] "" X
 SG_ PCS_a079_eepromOperationError m1: 22|1@1+ (1,0) [0|0] "" X
 SG_ PCS_a080_damagedPhaseDetected m1: 23|1@1+ (1,0) [0|0] "" X
 SG_ PCS_a081_dcdcPchgTimeout m1: 24|1@1+ (1,0) [0|0] "" X
 SG_ PCS_a082_dcdcPchgUnsafeDiVoltage m1: 25|1@1+ (1,0) [0|0] "" X
 SG_ PCS_a083_triggerOdin m1: 26|1@1+ (1,0) [0|0] "" X
 SG_ PCS_a084_dcdcPchgStartVoltages m1: 27|1@1+ (1,0) [0|0] "" X
 SG_ PCS_a085_dcdcFetsNotSwitching m1: 28|1@1+ (1,0) [0|0] "" X
 SG_ PCS_a086_dcdcInsufficientCooling m1: 29|1@1+ (1,0) [0|0] "" X
 SG_ PCS_a087_nvramRecordStatusError m1: 30|1@1+ (1,0) [0|0] "" X
 SG_ PCS_a088_pchgParameters m1: 31|1@1+ (1,0) [0|0] "" X
 SG_ PCS_a089_hvBusDischargeIrrational m1: 32|1@1+ (1,0) [0|0] "" X

BO_ 612 PCS_chgLineStatus: 6 VEH
 SG_ PCS_chgAcCurrentLimit: 32|10@1+ (0.1,0) [0|0] "A" X
 SG_ PCS_chgInputPower: 24|8@1+ (0.1,0) [0|0] "kW" X
 SG_ PCS_chgInputVoltage: 0|14@1+ (0.033,0) [0|0] "V" X
 SG_ PCS_chgLineCurrent: 14|9@1+ (0.1,0) [0|0] "A" X

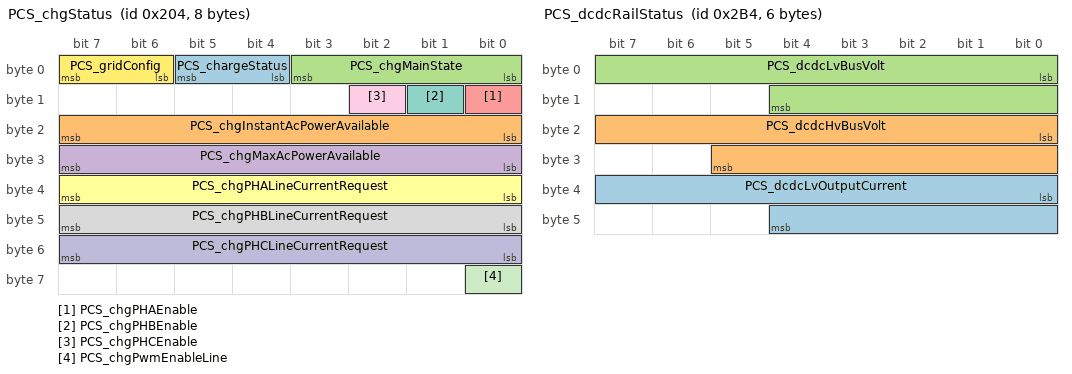
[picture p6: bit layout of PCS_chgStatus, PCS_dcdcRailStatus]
BO_ 516 PCS_chgStatus: 8 VEH
 SG_ PCS_chargeStatus: 4|2@1+ (1,0) [0|0] "" X
 SG_ PCS_chgInstantAcPowerAvailable: 16|8@1+ (0.1,0) [0|0] "kW" X
 SG_ PCS_chgMainState: 0|4@1+ (1,0) [0|0] "" X
 SG_ PCS_chgMaxAcPowerAvailable: 24|8@1+ (0.1,0) [0|0] "kW" X
 SG_ PCS_chgPHAEnable: 8|1@1+ (1,0) [0|0] "" X
 SG_ PCS_chgPHALineCurrentRequest: 32|8@1+ (0.1,0) [0|0] "A" X
 SG_ PCS_chgPHBEnable: 9|1@1+ (1,0) [0|0] "" X
 SG_ PCS_chgPHBLineCurrentRequest: 40|8@1+ (0.1,0) [0|0] "A" X
 SG_ PCS_chgPHCEnable: 10|1@1+ (1,0) [0|0] "" X
 SG_ PCS_chgPHCLineCurrentRequest: 48|8@1+ (0.1,0) [0|0] "A" X
 SG_ PCS_chgPwmEnableLine: 56|1@1+ (1,0) [0|0] "" X
 SG_ PCS_gridConfig: 6|2@1+ (1,0) [0|0] "" X

BO_ 692 PCS_dcdcRailStatus: 6 Vector__XXX
 SG_ PCS_dcdcLvOutputCurrent : 32|13@1- (0.1,0) [0|0] "" Vector__XXX
 SG_ PCS_dcdcHvBusVolt : 16|14@1+ (0.1,0) [0|0] "" Vector__XXX
 SG_ PCS_dcdcLvBusVolt : 0|13@1+ (0.01,0) [0|0] "" Vector__XXX

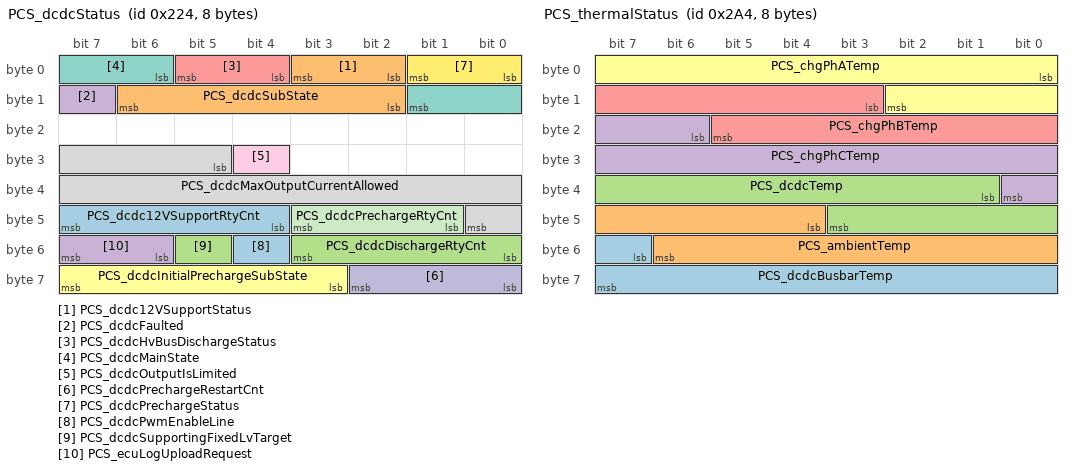
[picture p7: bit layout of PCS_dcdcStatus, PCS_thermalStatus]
BO_ 548 PCS_dcdcStatus: 8 VEH
 SG_ PCS_dcdc12VSupportRtyCnt: 44|4@1+ (1,0) [0|0] "" X
 SG_ PCS_dcdc12VSupportStatus: 2|2@1+ (1,0) [0|0] "" X
 SG_ PCS_dcdcDischargeRtyCnt: 48|4@1+ (1,0) [0|0] "" X
 SG_ PCS_dcdcFaulted: 15|1@1+ (1,0) [0|0] "" X
 SG_ PCS_dcdcHvBusDischargeStatus: 4|2@1+ (1,0) [0|0] "" X
 SG_ PCS_dcdcInitialPrechargeSubState: 59|5@1+ (1,0) [0|0] "" X
 SG_ PCS_dcdcMainState: 6|4@1+ (1,0) [0|0] "" X
 SG_ PCS_dcdcMaxOutputCurrentAllowed: 29|12@1+ (0.1,0) [0|0] "A" X
 SG_ PCS_dcdcOutputIsLimited: 28|1@1+ (1,0) [0|0] "" X
 SG_ PCS_dcdcPrechargeRestartCnt: 56|3@1+ (1,0) [0|0] "" X
 SG_ PCS_dcdcPrechargeRtyCnt: 41|3@1+ (1,0) [0|0] "" X
 SG_ PCS_dcdcPrechargeStatus: 0|2@1+ (1,0) [0|0] "" X
 SG_ PCS_dcdcPwmEnableLine: 52|1@1+ (1,0) [0|0] "" X
 SG_ PCS_dcdcSubState: 10|5@1+ (1,0) [0|0] "" X
 SG_ PCS_dcdcSupportingFixedLvTarget: 53|1@1+ (1,0) [0|0] "" X
 SG_ PCS_ecuLogUploadRequest: 54|2@1+ (1,0) [0|0] "" X

BO_ 964 PCS_info: 8 VEH
 SG_ PCS_infoIndex M: 0|8@1+ (1,0) [0|0] "" X
 SG_ PCS_buildType m10: 8|8@1+ (1,0) [0|0] "" X
 SG_ PCS_buildConfigId m10: 16|16@1+ (1,0) [0|0] "" X
 SG_ PCS_hardwareId m10: 32|16@1+ (1,0) [0|0] "" X
 SG_ PCS_componentId m10: 48|16@1+ (1,0) [0|0] "" X
 SG_ PCS_pcbaId m11: 16|8@1+ (1,0) [0|0] "" X
 SG_ PCS_assemblyId m11: 24|8@1+ (1,0) [0|0] "" X
 SG_ PCS_usageId m11: 32|16@1+ (1,0) [0|0] "" X
 SG_ PCS_subUsageId m11: 48|16@1+ (1,0) [0|0] "" X
 SG_ PCS_platformType m13: 8|8@1+ (1,0) [0|0] "" X
 SG_ PCS_appCrc m13: 32|32@1+ (1,0) [0|0] "" X
 SG_ PCS_cpu2AppCrc m16: 32|32@1+ (1,0) [0|0] "" X
 SG_ PCS_appGitHash m17: 10|54@1+ (4,0) [0|0] "" X
 SG_ PCS_bootGitHash m18: 10|54@1+ (4,0) [0|0] "" X
 SG_ PCS_bootUdsProtoVersion m20: 8|8@1+ (1,0) [0|0] "" X
 SG_ PCS_bootCrc m20: 32|32@1+ (1,0) [0|0] "" X
 SG_ PCS_partNumChar01 m25: 8|8@1+ (1,0) [0|0] "" X
 SG_ PCS_partNumChar02 m25: 16|8@1+ (1,0) [0|0] "" X
 SG_ PCS_partNumChar03 m25: 24|8@1+ (1,0) [0|0] "" X
 SG_ PCS_partNumChar04 m25: 32|8@1+ (1,0) [0|0] "" X
 SG_ PCS_partNumChar05 m25: 40|8@1+ (1,0) [0|0] "" X
 SG_ PCS_partNumChar06 m25: 48|8@1+ (1,0) [0|0] "" X
 SG_ PCS_partNumChar07 m25: 56|8@1+ (1,0) [0|0] "" X
 SG_ PCS_partNumChar08 m26: 8|8@1+ (1,0) [0|0] "" X
 SG_ PCS_partNumChar09 m26: 16|8@1+ (1,0) [0|0] "" X
 SG_ PCS_partNumChar10 m26: 24|8@1+ (1,0) [0|0] "" X
 SG_ PCS_partNumChar11 m26: 32|8@1+ (1,0) [0|0] "" X
 SG_ PCS_partNumChar12 m26: 40|8@1+ (1,0) [0|0] "" X
 SG_ PCS_partNumChar13 m26: 48|8@1+ (1,0) [0|0] "" X
 SG_ PCS_partNumChar14 m26: 56|8@1+ (1,0) [0|0] "" X
 SG_ PCS_partNumChar15 m27: 8|8@1+ (1,0) [0|0] "" X
 SG_ PCS_partNumChar16 m27: 16|8@1+ (1,0) [0|0] "" X
 SG_ PCS_partNumChar17 m27: 24|8@1+ (1,0) [0|0] "" X
 SG_ PCS_partNumChar18 m27: 32|8@1+ (1,0) [0|0] "" X
 SG_ PCS_partNumChar19 m27: 40|8@1+ (1,0) [0|0] "" X
 SG_ PCS_partNumChar20 m27: 48|8@1+ (1,0) [0|0] "" X
 SG_ PCS_serialNumChar01 m29: 8|8@1+ (1,0) [0|0] "" X
 SG_ PCS_serialNumChar02 m29: 16|8@1+ (1,0) [0|0] "" X
 SG_ PCS_serialNumChar03 m29: 24|8@1+ (1,0) [0|0] "" X
 SG_ PCS_serialNumChar04 m29: 32|8@1+ (1,0) [0|0] "" X
 SG_ PCS_serialNumChar05 m29: 40|8@1+ (1,0) [0|0] "" X
 SG_ PCS_serialNumChar06 m29: 48|8@1+ (1,0) [0|0] "" X
 SG_ PCS_serialNumChar07 m29: 56|8@1+ (1,0) [0|0] "" X
 SG_ PCS_serialNumChar08 m30: 8|8@1+ (1,0) [0|0] "" X
 SG_ PCS_serialNumChar09 m30: 16|8@1+ (1,0) [0|0] "" X
 SG_ PCS_serialNumChar10 m30: 24|8@1+ (1,0) [0|0] "" X
 SG_ PCS_serialNumChar11 m30: 32|8@1+ (1,0) [0|0] "" X
 SG_ PCS_serialNumChar12 m30: 40|8@1+ (1,0) [0|0] "" X
 SG_ PCS_serialNumChar13 m30: 48|8@1+ (1,0) [0|0] "" X
 SG_ PCS_serialNumChar14 m30: 56|8@1+ (1,0) [0|0] "" X

BO_ 708 PCS_logging: 8 VEH
 SG_ PCS_logMessageSelect M: 0|5@1+ (1,0) [0|0] "" X
 SG_ PCS_chgPhAInputIrms m0: 5|9@1+ (0.1,0) [0|0] "A" X
 SG_ PCS_chgPhAIntBusV m0: 14|9@1+ (1,0) [0|0] "V" X
 SG_ PCS_chgPhAIntBusVTarget m0: 23|9@1+ (1,0) [0|0] "V" X
 SG_ PCS_chgPhAOutputI m0: 32|8@1+ (0.1,0) [0|0] "A" X
 SG_ PCS_chgPhBInputIrms m1: 5|9@1+ (0.1,0) [0|0] "A" X
 SG_ PCS_chgPhBIntBusV m1: 14|9@1+ (1,0) [0|0] "V" X
 SG_ PCS_chgPhBIntBusVTarget m1: 23|9@1+ (1,0) [0|0] "V" X
 SG_ PCS_chgPhBOutputI m1: 32|8@1+ (0.1,0) [0|0] "A" X
 SG_ PCS_chgPhCInputIrms m2: 5|9@1+ (0.1,0) [0|0] "A" X
 SG_ PCS_chgPhCIntBusV m2: 14|9@1+ (1,0) [0|0] "V" X
 SG_ PCS_chgPhCIntBusVTarget m2: 23|9@1+ (1,0) [0|0] "V" X
 SG_ PCS_chgPhCOutputI m2: 32|8@1+ (0.1,0) [0|0] "A" X
 SG_ PCS_chgInputL1NVrms m3: 5|12@1+ (0.2,0) [0|0] "V" X
 SG_ PCS_chgInputL2NVrms m3: 17|12@1+ (0.2,0) [0|0] "V" X
 SG_ PCS_chgInputL3NVrms m3: 29|12@1+ (0.2,0) [0|0] "V" X
 SG_ PCS_chgInputL1L2Vrms m3: 41|12@1+ (0.2,0) [0|0] "V" X
 SG_ PCS_chgInputNGVrms m3: 53|9@1+ (1,0) [0|0] "V" X
 SG_ PCS_chgInputFrequencyL1N m4: 8|12@1+ (0.01,40) [0|0] "Hz" X
 SG_ PCS_chgInputFrequencyL2N m4: 20|12@1+ (0.01,40) [0|0] "Hz" X
 SG_ PCS_chgInputFrequencyL3N m4: 32|12@1+ (0.01,40) [0|0] "Hz" X
 SG_ PCS_chgInternalPhaseConfig m4: 44|3@1+ (1,0) [0|0] "" X
 SG_ PCS_chgOutputV m4: 48|12@1+ (0.146484,0) [0|0] "V" X
 SG_ PCS_chgPhAState m5: 5|4@1+ (1,0) [0|0] "" X
 SG_ PCS_chgPhBState m5: 9|4@1+ (1,0) [0|0] "" X
 SG_ PCS_chgPhCState m5: 13|4@1+ (1,0) [0|0] "" X
 SG_ PCS_chgPhALastShutdownReason m5: 17|5@1+ (1,0) [0|0] "" X
 SG_ PCS_chgPhBLastShutdownReason m5: 22|5@1+ (1,0) [0|0] "" X
 SG_ PCS_chgPhCLastShutdownReason m5: 27|5@1+ (1,0) [0|0] "" X
 SG_ PCS_chgPhARetryCount m5: 32|3@1+ (1,0) [0|0] "" X
 SG_ PCS_chgPhBRetryCount m5: 35|3@1+ (1,0) [0|0] "" X
 SG_ PCS_chgPhCRetryCount m5: 38|3@1+ (1,0) [0|0] "" X
 SG_ PCS_chgRetryCount m5: 41|3@1+ (1,0) [0|0] "" X
 SG_ PCS_chgPhManCurrentToDist m5: 44|10@1+ (0.1,0) [0|0] "A" X
 SG_ PCS_chgL1NPllLocked m5: 54|1@1+ (1,0) [0|0] "" X
 SG_ PCS_chgL2NPllLocked m5: 55|1@1+ (1,0) [0|0] "" X
 SG_ PCS_chgL3NPllLocked m5: 56|1@1+ (1,0) [0|0] "" X
 SG_ PCS_chgL1L2PllLocked m5: 57|1@1+ (1,0) [0|0] "" X
 SG_ PCS_chgNgPllLocked m5: 58|1@1+ (1,0) [0|0] "" X
 SG_ PCS_chgPhManOptimalPhsToUse m5: 59|2@1+ (1,0) [0|0] "" X
 SG_ PCS_chg5VL1Enable m5: 61|1@1+ (1,0) [0|0] "" X
 SG_ PCS_dcdcMaxLvOutputCurrent m6: 28|12@1+ (0.1,0) [0|0] "A" X
 SG_ PCS_dcdcCurrentLimit m6: 40|12@1+ (0.1,0) [0|0] "A" X
 SG_ PCS_dcdcLvOutputCurrentTempLimit m6: 52|12@1+ (0.1,0) [0|0] "A" X
 SG_ PCS_dcdcUnifiedCommand m7: 5|10@1+ (0.001,0) [0|0] "1" X
 SG_ PCS_dcdcCLAControllerOutput m7: 16|10@1+ (0.001,0) [0|0] "1" X
 SG_ PCS_dcdcTankVoltage m7: 26|11@1- (1,0) [0|0] "V" X
 SG_ PCS_dcdcTankVoltageTarget m7: 37|10@1+ (1,0) [0|0] "V" X
 SG_ PCS_dcdcClaCurrentFreq m7: 48|12@1+ (0.0976563,0) [0|0] "kHz" X
 SG_ PCS_dcdcTCommMeasured m8: 8|16@1- (0.00195313,0) [0|0] "us" X
 SG_ PCS_dcdcShortTimeUs m8: 24|16@1+ (0.000488281,0) [0|0] "us" X
 SG_ PCS_dcdcHalfPeriodUs m8: 40|16@1+ (0.000488281,0) [0|0] "us" X
 SG_ PCS_cpu2BootState m9: 5|2@1+ (1,0) [0|0] "" X
 SG_ PCS_acChargeSelfTestState m9: 7|1@1+ (1,0) [0|0] "" X
 SG_ PCS_1V5Min10s m9: 8|11@1+ (0.001,0) [0|0] "V" X
 SG_ PCS_1V5Max10s m9: 19|11@1+ (0.001,0) [0|0] "V" X
 SG_ PCS_1V2Min10s m9: 32|11@1+ (0.001,0) [0|0] "V" X
 SG_ PCS_1V2Max10s m9: 43|11@1+ (0.001,0) [0|0] "V" X
 SG_ PCS_numAlertsSet m9: 56|7@1+ (1,0) [0|0] "" X
 SG_ PCS_chgPhAIntBusVMin10s m10: 5|9@1+ (1,0) [0|0] "V" X
 SG_ PCS_chgPhAIntBusVMax10s m10: 14|9@1+ (1,0) [0|0] "V" X
 SG_ PCS_chgPhAPchgVoltDeltaMax10s m10: 23|8@1+ (0.5,0) [0|0] "V" X
 SG_ PCS_chgPhALifetimekWh m10: 31|24@1+ (0.01,0) [0|0] "kWh" X
 SG_ PCS_chgPhATransientRetryCount m10: 55|9@1+ (0.1,0) [0|0] "-" X
 SG_ PCS_chgPhBIntBusVMin10s m11: 5|9@1+ (1,0) [0|0] "V" X
 SG_ PCS_chgPhBIntBusVMax10s m11: 14|9@1+ (1,0) [0|0] "V" X
 SG_ PCS_chgPhBPchgVoltDeltaMax10s m11: 23|8@1+ (0.5,0) [0|0] "V" X
 SG_ PCS_chgPhBLifetimekWh m11: 31|24@1+ (0.01,0) [0|0] "kWh" X
 SG_ PCS_chgPhBTransientRetryCount m11: 55|9@1+ (0.1,0) [0|0] "-" X
 SG_ PCS_chgPhCIntBusVMin10s m12: 5|9@1+ (1,0) [0|0] "V" X
 SG_ PCS_chgPhCIntBusVMax10s m12: 14|9@1+ (1,0) [0|0] "V" X
 SG_ PCS_chgPhCPchgVoltDeltaMax10s m12: 23|8@1+ (0.5,0) [0|0] "V" X
 SG_ PCS_chgPhCLifetimekWh m12: 31|24@1+ (0.01,0) [0|0] "kWh" X
 SG_ PCS_chgPhCTransientRetryCount m12: 55|9@1+ (0.1,0) [0|0] "-" X
 SG_ PCS_chgInputL1NVPeak10s m13: 5|9@1+ (1,0) [0|0] "V" X
 SG_ PCS_chgInputL2NVPeak10s m13: 14|9@1+ (1,0) [0|0] "V" X
 SG_ PCS_chgInputL3NVPeak10s m13: 23|9@1+ (1,0) [0|0] "V" X
 SG_ PCS_chgInputFreqWobblePHAPeak m13: 32|8@1+ (0.01,0) [0|0] "Hz" X
 SG_ PCS_chgInputFreqWobblePHBPeak m13: 40|8@1+ (0.01,0) [0|0] "Hz" X
 SG_ PCS_chgInputFreqWobblePHCPeak m13: 48|8@1+ (0.01,0) [0|0] "Hz" X
 SG_ PCS_dLogPhAChannel1Content m14: 5|2@1+ (1,0) [0|0] "" X
 SG_ PCS_dLogPhBChannel1Content m14: 8|2@1+ (1,0) [0|0] "" X
 SG_ PCS_dLogPhCChannel1Content m14: 10|2@1+ (1,0) [0|0] "" X
 SG_ PCS_dLogPhAChannel1Data m14: 16|16@1- (0.02,0) [0|0] "-" X
 SG_ PCS_dLogPhBChannel1Data m14: 32|16@1- (0.02,0) [0|0] "-" X
 SG_ PCS_dLogPhCChannel1Data m14: 48|16@1- (0.02,0) [0|0] "-" X
 SG_ PCS_dLogPhAChannel2Content m15: 5|2@1+ (1,0) [0|0] "" X
 SG_ PCS_dLogPhBChannel2Content m15: 8|2@1+ (1,0) [0|0] "" X
 SG_ PCS_dLogPhCChannel2Content m15: 10|2@1+ (1,0) [0|0] "" X
 SG_ PCS_dLogPhAChannel2Data m15: 16|16@1- (0.02,0) [0|0] "-" X
 SG_ PCS_dLogPhBChannel2Data m15: 32|16@1- (0.02,0) [0|0] "-" X
 SG_ PCS_dLogPhCChannel2Data m15: 48|16@1- (0.02,0) [0|0] "-" X
 SG_ PCS_dLogPhAChannel3Content m16: 5|2@1+ (1,0) [0|0] "" X
 SG_ PCS_dLogPhBChannel3Content m16: 8|2@1+ (1,0) [0|0] "" X
 SG_ PCS_dLogPhCChannel3Content m16: 10|2@1+ (1,0) [0|0] "" X
 SG_ PCS_dLogPhAChannel3Data m16: 16|16@1- (0.02,0) [0|0] "-" X
 SG_ PCS_dLogPhBChannel3Data m16: 32|16@1- (0.02,0) [0|0] "-" X
 SG_ PCS_dLogPhCChannel3Data m16: 48|16@1- (0.02,0) [0|0] "-" X
 SG_ PCS_dLogPhAChannel4Content m17: 5|2@1+ (1,0) [0|0] "" X
 SG_ PCS_dLogPhBChannel4Content m17: 8|2@1+ (1,0) [0|0] "" X
 SG_ PCS_dLogPhCChannel4Content m17: 10|2@1+ (1,0) [0|0] "" X
 SG_ PCS_dLogPhAChannel4Data m17: 16|16@1- (0.02,0) [0|0] "-" X
 SG_ PCS_dLogPhBChannel4Data m17: 32|16@1- (0.02,0) [0|0] "-" X
 SG_ PCS_dLogPhCChannel4Data m17: 48|16@1- (0.02,0) [0|0] "-" X
 SG_ PCS_dcdcIntervalMaxFrequency m18: 8|12@1+ (1,0) [0|0] "kHz" X
 SG_ PCS_dcdcIntervalMaxHvBusVolt m18: 24|13@1+ (0.1,0) [0|0] "V" X
 SG_ PCS_dcdcIntervalMaxLvBusVolt m18: 37|9@1+ (0.1,0) [0|0] "V" X
 SG_ PCS_dcdcIntervalMaxLvOutputCurr m18: 48|12@1+ (1,0) [0|0] "A" X
 SG_ PCS_dcdcIntervalMinFrequency m19: 8|12@1+ (1,0) [0|0] "kHz" X
 SG_ PCS_dcdcIntervalMinHvBusVolt m19: 24|13@1+ (0.1,0) [0|0] "V" X
 SG_ PCS_dcdcIntervalMinLvBusVolt m19: 37|9@1+ (0.1,0) [0|0] "V" X
 SG_ PCS_dcdcIntervalMinLvOutputCurr m19: 48|12@1+ (1,0) [0|0] "A" X
 SG_ PCS_chgPhANoFlowBucket m20: 5|9@1+ (0.01,0) [0|0] "-" X
 SG_ PCS_chgPhBNoFlowBucket m20: 14|9@1+ (0.01,0) [0|0] "-" X
 SG_ PCS_chgPhCNoFlowBucket m20: 23|9@1+ (0.01,0) [0|0] "-" X
 SG_ PCS_chgInputL1NVdc m21: 5|10@1- (1,0) [0|0] "V" X
 SG_ PCS_chgInputL2NVdc m21: 16|10@1- (1,0) [0|0] "V" X
 SG_ PCS_chgInputL3NVdc m21: 26|10@1- (1,0) [0|0] "V" X
 SG_ PCS_chgInputL1L2Vdc m21: 36|10@1- (1,0) [0|0] "V" X
 SG_ PCS_chgInputNGVdc m21: 46|10@1- (1,0) [0|0] "V" X
 SG_ PCS_dcdc12vSupportLifetimekWh m22: 8|24@1+ (0.01,0) [0|0] "kWh" X

BO_ 676 PCS_thermalStatus: 8 Vector__XXX
 SG_ PCS_dcdcBusbarTemp : 55|9@1+ (0.29354207436399216,0) [0|0] "" Vector__XXX
 SG_ PCS_ambientTemp : 44|11@1- (0.1,40) [0|0] "" Vector__XXX
 SG_ PCS_dcdcTemp : 33|11@1- (0.1,40) [0|0] "" Vector__XXX
 SG_ PCS_chgPhCTemp : 22|11@1- (0.1,40) [0|0] "" Vector__XXX
 SG_ PCS_chgPhBTemp : 11|11@1- (0.1,40) [0|0] "" Vector__XXX
 SG_ PCS_chgPhATemp : 0|11@1- (0.1,40) [0|0] "" Vector__XXX

BO_ 900 PMS_alertMatrix1: 8 VEH
 SG_ PMS_w001_absoluteTorque: 0|1@1+ (1,0) [0|0] "" X
 SG_ PMS_w002_accumulatedTorque: 1|1@1+ (1,0) [0|0] "" X
 SG_ PMS_w003_torqueReversal: 2|1@1+ (1,0) [0|0] "" X
 SG_ PMS_w004_regenTorque: 3|1@1+ (1,0) [0|0] "" X
 SG_ PMS_w005_torqueInNeutral: 4|1@1+ (1,0) [0|0] "" X
 SG_ PMS_w006_inconsistentDIGear: 5|1@1+ (1,0) [0|0] "" X
 SG_ PMS_w007_watchdogReset: 6|1@1+ (1,0) [0|0] "" X
 SG_ PMS_w008_memoryError: 7|1@1+ (1,0) [0|0] "" X
 SG_ PMS_w009_espMIA: 8|1@1+ (1,0) [0|0] "" X
 SG_ PMS_w010_diMIA: 9|1@1+ (1,0) [0|0] "" X
 SG_ PMS_w011_phaseCurrentIrrational: 10|1@1+ (1,0) [0|0] "" X
 SG_ PMS_w012_canDataBusA: 11|1@1+ (1,0) [0|0] "" X
 SG_ PMS_w013_canHardwareBusA: 12|1@1+ (1,0) [0|0] "" X
 SG_ PMS_w018_encoderIrrational: 17|1@1+ (1,0) [0|0] "" X
 SG_ PMS_w019_statorTempIrrational: 18|1@1+ (1,0) [0|0] "" X
 SG_ PMS_w026_diHeartBeatMIA: 25|1@1+ (1,0) [0|0] "" X
 SG_ PMS_w027_torqueOutOfMap: 26|1@1+ (1,0) [0|0] "" X
 SG_ PMS_w028_torqueCmdError: 27|1@1+ (1,0) [0|0] "" X
 SG_ PMS_w031_highStackUsage: 30|1@1+ (1,0) [0|0] "" X
 SG_ PMS_w032_registerConfigError: 31|1@1+ (1,0) [0|0] "" X
 SG_ PMS_w033_selfTest: 32|1@1+ (1,0) [0|0] "" X
 SG_ PMS_w034_trqCrossCheck: 33|1@1+ (1,0) [0|0] "" X
 SG_ PMS_w038_inconsistentTorqueSign: 37|1@1+ (1,0) [0|0] "" X
 SG_ PMS_w039_disMIA: 38|1@1+ (1,0) [0|0] "" X
 SG_ PMS_w040_pmMIA: 39|1@1+ (1,0) [0|0] "" X
 SG_ PMS_w042_gtwMIA: 41|1@1+ (1,0) [0|0] "" X
 SG_ PMS_w043_inconsistentConfig: 42|1@1+ (1,0) [0|0] "" X
 SG_ PMS_w045_motorMovementDetected: 44|1@1+ (1,0) [0|0] "" X
 SG_ PMS_w053_vcfrontMIA: 52|1@1+ (1,0) [0|0] "" X
 SG_ PMS_w054_uiMIA: 53|1@1+ (1,0) [0|0] "" X
 SG_ PMS_w055_resolver: 54|1@1+ (1,0) [0|0] "" X
 SG_ PMS_w056_canHardwareBusB: 55|1@1+ (1,0) [0|0] "" X
 SG_ PMS_w057_canDataBusB: 56|1@1+ (1,0) [0|0] "" X
 SG_ PMS_w061_DIPMVersionMismatch: 60|1@1+ (1,0) [0|0] "" X
 SG_ PMS_w063_debugAlert: 62|1@1+ (1,0) [0|0] "" X
 SG_ PMS_w064_torqueIntervention: 63|1@1+ (1,0) [0|0] "" X

BO_ 1748 PMR_info: 8 Vector__XXX
 SG_ PMR_componentId m10 : 48|16@1+ (1,0) [0|0] "" Vector__XXX
 SG_ PMR_subUsageId m11 : 48|16@1+ (1,0) [0|0] "" Vector__XXX
 SG_ PMR_applicationCrc m13 : 32|32@1+ (1,0) [0|0] "" Vector__XXX
 SG_ PMR_bootloaderCrc m20 : 32|32@1+ (1,0) [0|0] "" Vector__XXX
 SG_ PMR_diNodeApplicationCrc m21 : 32|32@1+ (1,0) [0|0] "" Vector__XXX
 SG_ PMR_hardwareId m10 : 32|8@1+ (1,0) [0|0] "" Vector__XXX
 SG_ PMR_usageId m11 : 32|16@1+ (1,0) [0|0] "" Vector__XXX
 SG_ PMR_assemblyId m11 : 24|8@1+ (1,0) [0|0] "" Vector__XXX
 SG_ PMR_buildConfigurationId m10 : 16|16@1+ (1,0) [0|0] "" Vector__XXX
 SG_ PMR_diNodeBuildConfigurationId m21 : 16|16@1+ (1,0) [0|0] "" Vector__XXX
 SG_ PMR_pcbaId m11 : 16|8@1+ (1,0) [0|0] "" Vector__XXX
 SG_ PMR_appGitHash m17 : 8|56@1+ (1,0) [0|0] "" Vector__XXX
 SG_ PMR_bootGitHash m18 : 8|56@1+ (1,0) [0|0] "" Vector__XXX
 SG_ PMR_buildType m10 : 8|8@1+ (1,0) [0|0] "" Vector__XXX
 SG_ PMR_diNodeBuildType m21 : 8|8@1+ (1,0) [0|0] "" Vector__XXX
 SG_ PMR_platformTyp m19 : 8|8@1+ (1,0) [0|0] "" Vector__XXX
 SG_ PMR_udsProtocolVersion m20 : 8|8@1+ (1,0) [0|0] "" Vector__XXX
 SG_ PMR_infoIndex M : 0|8@1+ (1,0) [0|0] "" Vector__XXX

BO_ 772 PM_alertMatrix1: 8 VEH
 SG_ PM_a001_absoluteTorque: 0|1@1+ (1,0) [0|0] "" X
 SG_ PM_a002_accumulatedTorque: 1|1@1+ (1,0) [0|0] "" X
 SG_ PM_a003_torqueReversal: 2|1@1+ (1,0) [0|0] "" X
 SG_ PM_a004_regenTorque: 3|1@1+ (1,0) [0|0] "" X
 SG_ PM_a005_torqueInNeutral: 4|1@1+ (1,0) [0|0] "" X
 SG_ PM_a006_inconsistentDIGear: 5|1@1+ (1,0) [0|0] "" X
 SG_ PM_a007_watchdogReset: 6|1@1+ (1,0) [0|0] "" X
 SG_ PM_a008_memoryError: 7|1@1+ (1,0) [0|0] "" X
 SG_ PM_a009_espMIA: 8|1@1+ (1,0) [0|0] "" X
 SG_ PM_a010_diMIA: 9|1@1+ (1,0) [0|0] "" X
 SG_ PM_a011_phaseCurrentIrrational: 10|1@1+ (1,0) [0|0] "" X
 SG_ PM_a012_canDataBusA: 11|1@1+ (1,0) [0|0] "" X
 SG_ PM_a013_canHardwareBusA: 12|1@1+ (1,0) [0|0] "" X
 SG_ PM_a014_accelPedalError: 13|1@1+ (1,0) [0|0] "" X
 SG_ PM_a015_shifterMIA: 14|1@1+ (1,0) [0|0] "" X
 SG_ PM_a016_cruiseMIA: 15|1@1+ (1,0) [0|0] "" X
 SG_ PM_a017_brakeMIA: 16|1@1+ (1,0) [0|0] "" X
 SG_ PM_a018_encoderIrrational: 17|1@1+ (1,0) [0|0] "" X
 SG_ PM_a019_statorTempIrrational: 18|1@1+ (1,0) [0|0] "" X
 SG_ PM_a023_crsCmdOffStateOn: 22|1@1+ (1,0) [0|0] "" X
 SG_ PM_a024_brakeIrrational: 23|1@1+ (1,0) [0|0] "" X
 SG_ PM_a026_diHeartBeatMIA: 25|1@1+ (1,0) [0|0] "" X
 SG_ PM_a027_torqueOutOfMap: 26|1@1+ (1,0) [0|0] "" X
 SG_ PM_a028_torqueCmdError: 27|1@1+ (1,0) [0|0] "" X
 SG_ PM_a030_inconsistentAebState: 29|1@1+ (1,0) [0|0] "" X
 SG_ PM_a031_highStackUsage: 30|1@1+ (1,0) [0|0] "" X
 SG_ PM_a032_registerConfigError: 31|1@1+ (1,0) [0|0] "" X
 SG_ PM_a033_selfTest: 32|1@1+ (1,0) [0|0] "" X
 SG_ PM_a034_trqCrossCheck: 33|1@1+ (1,0) [0|0] "" X
 SG_ PM_a038_inconsistentTorqueSign: 37|1@1+ (1,0) [0|0] "" X
 SG_ PM_a039_disMIA: 38|1@1+ (1,0) [0|0] "" X
 SG_ PM_a040_pmMIA: 39|1@1+ (1,0) [0|0] "" X
 SG_ PM_a041_dasMIA: 40|1@1+ (1,0) [0|0] "" X
 SG_ PM_a042_gtwMIA: 41|1@1+ (1,0) [0|0] "" X
 SG_ PM_a043_inconsistentConfig: 42|1@1+ (1,0) [0|0] "" X
 SG_ PM_a044_ebrIntervention: 43|1@1+ (1,0) [0|0] "" X
 SG_ PM_a045_motorMovementDetected: 44|1@1+ (1,0) [0|0] "" X
 SG_ PM_a046_inconsVehicleHoldState: 45|1@1+ (1,0) [0|0] "" X
 SG_ PM_a047_inconsAutoparkState: 46|1@1+ (1,0) [0|0] "" X
 SG_ PM_a048_stabilityControlInhibit: 47|1@1+ (1,0) [0|0] "" X
 SG_ PM_a049_stbCtrlInWrongDir: 48|1@1+ (1,0) [0|0] "" X
 SG_ PM_a050_excessiveStbCtrlTrq: 49|1@1+ (1,0) [0|0] "" X
 SG_ PM_a051_unintDecelStbCtrl: 50|1@1+ (1,0) [0|0] "" X
 SG_ PM_a052_stbCtrlDrvrDecelCflct: 51|1@1+ (1,0) [0|0] "" X
 SG_ PM_a053_vcfrontMIA: 52|1@1+ (1,0) [0|0] "" X
 SG_ PM_a054_uiMIA: 53|1@1+ (1,0) [0|0] "" X
 SG_ PM_a055_resolver: 54|1@1+ (1,0) [0|0] "" X
 SG_ PM_a056_canHardwareBusB: 55|1@1+ (1,0) [0|0] "" X
 SG_ PM_a057_canDataBusB: 56|1@1+ (1,0) [0|0] "" X
 SG_ PM_a058_cmpMIA: 57|1@1+ (1,0) [0|0] "" X
 SG_ PM_a059_ptcMIA: 58|1@1+ (1,0) [0|0] "" X
 SG_ PM_a061_DIPMVersionMismatch: 60|1@1+ (1,0) [0|0] "" X
 SG_ PM_a063_debugAlert: 62|1@1+ (1,0) [0|0] "" X
 SG_ PM_a064_torqueIntervention: 63|1@1+ (1,0) [0|0] "" X

BO_ 790 PM_info: 8 VEH
 SG_ PM_infoIndex M: 0|8@1+ (1,0) [0|0] "" X
 SG_ PM_buildType m10: 8|8@1+ (1,0) [0|0] "" X
 SG_ PM_buildConfigurationId m10: 16|16@1+ (1,0) [0|0] "" X
 SG_ PM_hardwareId m10: 32|8@1+ (1,0) [0|0] "" X
 SG_ PM_componentId m10: 48|16@1+ (1,0) [0|0] "" X
 SG_ PM_pcbaId m11: 16|8@1+ (1,0) [0|0] "" X
 SG_ PM_assemblyId m11: 24|8@1+ (1,0) [0|0] "" X
 SG_ PM_usageId m11: 32|16@1+ (1,0) [0|0] "" X
 SG_ PM_subUsageId m11: 48|16@1+ (1,0) [0|0] "" X
 SG_ PM_applicationCrc m13: 32|32@1+ (1,0) [0|0] "" X
 SG_ PM_bootloaderSvnRevision m14: 8|24@1+ (1,0) [0|0] "" X
 SG_ PM_bootloaderSvnUrlHash m14: 32|32@1+ (1,0) [0|0] "" X
 SG_ PM_appGitHash m17: 10|54@1+ (4,0) [0|0] "" X
 SG_ PM_bootGitHash m18: 10|54@1+ (4,0) [0|0] "" X
 SG_ PM_platformTyp m19: 8|8@1+ (1,0) [0|0] "" X
 SG_ PM_udsProtocolVersion m20: 8|8@1+ (1,0) [0|0] "" X
 SG_ PM_bootloaderCrc m20: 32|32@1+ (1,0) [0|0] "" X

BO_ 837 PTC_info: 8 VEH
 SG_ PTC_infoIndex M: 0|8@1+ (1,0) [0|0] "" X
 SG_ PTC_infoBuildType m10: 8|3@1+ (1,0) [0|0] "" X
 SG_ PTC_infoBuildConfigId m10: 16|16@1+ (1,0) [0|0] "" X
 SG_ PTC_infoHardwareId m10: 32|16@1+ (1,0) [0|0] "" X
 SG_ PTC_infoComponentId m10: 48|16@1+ (1,0) [0|0] "" X
 SG_ PTC_infoPcbaId m11: 16|8@1+ (1,0) [0|0] "" X
 SG_ PTC_infoAssemblyId m11: 24|8@1+ (1,0) [0|0] "" X
 SG_ PTC_infoUsageId m11: 32|16@1+ (1,0) [0|0] "" X
 SG_ PTC_infoSubUsageId m11: 48|16@1+ (1,0) [0|0] "" X
 SG_ PTC_infoBootUdsProtoVersion m20: 8|8@1+ (1,0) [0|0] "" X
 SG_ PTC_infoBootCrc m20: 32|32@1+ (1,0) [0|0] "" X
 SG_ PTC_infoPlatformType m13: 8|8@1+ (1,0) [0|0] "" X
 SG_ PTC_infoAppCrc m13: 32|32@1+ (1,0) [0|0] "" X

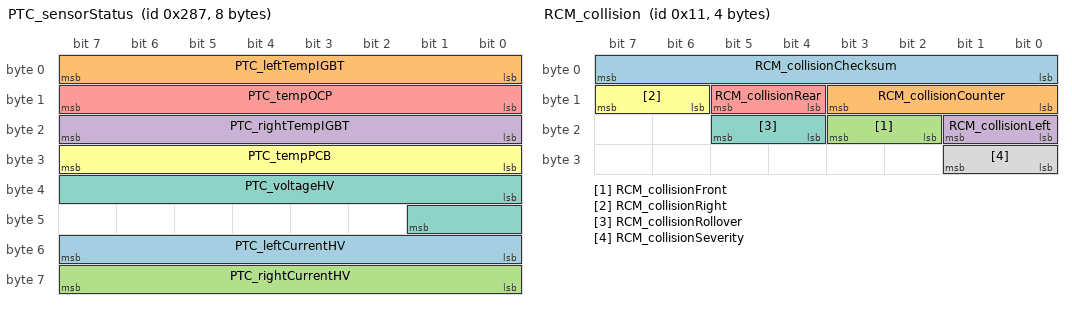
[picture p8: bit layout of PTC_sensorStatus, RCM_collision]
BO_ 647 PTC_sensorStatus: 8 VEH
 SG_ PTC_leftCurrentHV: 48|8@1+ (0.2,0) [0|0] "A" X
 SG_ PTC_leftTempIGBT: 0|8@1+ (1,-40) [0|0] "degC" X
 SG_ PTC_rightCurrentHV: 56|8@1+ (0.2,0) [0|0] "A" X
 SG_ PTC_rightTempIGBT: 16|8@1+ (1,-40) [0|0] "degC" X
 SG_ PTC_tempOCP: 8|8@1+ (1,-40) [0|0] "degC" X
 SG_ PTC_tempPCB: 24|8@1+ (1,-40) [0|0] "degC" X
 SG_ PTC_voltageHV: 32|10@1+ (0.5,0) [0|0] "V" X

BO_ 1282 RADC_alertMatrix0: 8 CH
 SG_ RADC_a001_can1BusOff: 1|1@1+ (1,0) [0|0] "" X
 SG_ RADC_a002_ecuAdcError: 2|1@1+ (1,0) [0|0] "" X
 SG_ RADC_a003_ecuBistDisabled: 3|1@1+ (1,0) [0|0] "" X
 SG_ RADC_a004_ecuCrcHwError: 4|1@1+ (1,0) [0|0] "" X
 SG_ RADC_a005_ecuEcuMError: 5|1@1+ (1,0) [0|0] "" X
 SG_ RADC_a006_ecuFimError: 6|1@1+ (1,0) [0|0] "" X
 SG_ RADC_a007_ecuGptCheckError: 7|1@1+ (1,0) [0|0] "" X
 SG_ RADC_a008_ecuHwSwInterlock: 8|1@1+ (1,0) [0|0] "" X
 SG_ RADC_a009_plantModeActive: 9|1@1+ (1,0) [0|0] "" X
 SG_ RADC_a010_ecuIoHwAbError: 10|1@1+ (1,0) [0|0] "" X
 SG_ RADC_a011_ecuMcemError: 11|1@1+ (1,0) [0|0] "" X
 SG_ RADC_a012_ecuSpiError: 12|1@1+ (1,0) [0|0] "" X
 SG_ RADC_a013_ecuWdgError: 13|1@1+ (1,0) [0|0] "" X
 SG_ RADC_a014_fctSelfTestNotDone: 14|1@1+ (1,0) [0|0] "" X
 SG_ RADC_a015_fctSenInterference: 15|1@1+ (1,0) [0|0] "" X
 SG_ RADC_a016_adcOverVolt: 16|1@1+ (1,0) [0|0] "" X
 SG_ RADC_a017_adcUnderVolt: 17|1@1+ (1,0) [0|0] "" X
 SG_ RADC_a018_internalHardwareFault: 18|1@1+ (1,0) [0|0] "" X
 SG_ RADC_a019_internalSoftwareFault: 19|1@1+ (1,0) [0|0] "" X
 SG_ RADC_a020_overTemp: 20|1@1+ (1,0) [0|0] "" X
 SG_ RADC_a021_overTempCrit: 21|1@1+ (1,0) [0|0] "" X
 SG_ RADC_a022_tempImplausible: 22|1@1+ (1,0) [0|0] "" X
 SG_ RADC_a023_underTemp: 23|1@1+ (1,0) [0|0] "" X
 SG_ RADC_a024_underTempCrit: 24|1@1+ (1,0) [0|0] "" X
 SG_ RADC_a025_overVoltage: 25|1@1+ (1,0) [0|0] "" X
 SG_ RADC_a026_underVoltage: 26|1@1+ (1,0) [0|0] "" X
 SG_ RADC_a027_nvmFailure: 27|1@1+ (1,0) [0|0] "" X
 SG_ RADC_a028_rfChipError: 28|1@1+ (1,0) [0|0] "" X
 SG_ RADC_a029_rhcError: 29|1@1+ (1,0) [0|0] "" X
 SG_ RADC_a030_rspError: 30|1@1+ (1,0) [0|0] "" X
 SG_ RADC_a031_sensorMisaligned: 31|1@1+ (1,0) [0|0] "" X
 SG_ RADC_a032_sensorBlocked: 32|1@1+ (1,0) [0|0] "" X
 SG_ RADC_a033_sensorNeverAligned: 33|1@1+ (1,0) [0|0] "" X
 SG_ RADC_a034_vehDynamicsError: 34|1@1+ (1,0) [0|0] "" X
 SG_ RADC_a035_vinMIA: 35|1@1+ (1,0) [0|0] "" X
 SG_ RADC_a036_carConfigMIA: 36|1@1+ (1,0) [0|0] "" X
 SG_ RADC_a037_inertialSignalsMIA: 37|1@1+ (1,0) [0|0] "" X
 SG_ RADC_a038_steeringWheelAngleMIA: 38|1@1+ (1,0) [0|0] "" X
 SG_ RADC_a039_vehicleStateMIA: 39|1@1+ (1,0) [0|0] "" X
 SG_ RADC_a040_wheelSpeedsMIA: 40|1@1+ (1,0) [0|0] "" X
 SG_ RADC_a041_vinErr: 41|1@1+ (1,0) [0|0] "" X
 SG_ RADC_a042_carConfigErr: 42|1@1+ (1,0) [0|0] "" X
 SG_ RADC_a043_inertialSignalsErr: 43|1@1+ (1,0) [0|0] "" X
 SG_ RADC_a044_steeringWheelAngleErr: 44|1@1+ (1,0) [0|0] "" X
 SG_ RADC_a045_vehicleStateErr: 45|1@1+ (1,0) [0|0] "" X
 SG_ RADC_a046_wheelSpeedsErr: 46|1@1+ (1,0) [0|0] "" X
 SG_ RADC_a047_mismatchChassisType: 47|1@1+ (1,0) [0|0] "" X
 SG_ RADC_a048_mismatchAirSuspension: 48|1@1+ (1,0) [0|0] "" X
 SG_ RADC_a049_mismatchFourWheelDrive: 49|1@1+ (1,0) [0|0] "" X
 SG_ RADC_a050_mismatchCountry: 50|1@1+ (1,0) [0|0] "" X
 SG_ RADC_a051_mismatchEPASType: 51|1@1+ (1,0) [0|0] "" X
 SG_ RADC_a052_mismatcRadPos: 52|1@1+ (1,0) [0|0] "" X
 SG_ RADC_a053_emError: 53|1@1+ (1,0) [0|0] "" X
 SG_ RADC_a054_blockageInfo_Frame_1: 54|1@1+ (1,0) [0|0] "" X
 SG_ RADC_a055_blockageInfo_Frame_2: 55|1@1+ (1,0) [0|0] "" X

BO_ 1329 RADC_info: 8 CH
 SG_ RADC_infoIndex M: 0|8@1+ (1,0) [0|0] "" X
 SG_ RADC_infoPlatformType m19: 8|8@1+ (1,0) [0|0] "" X
 SG_ RADC_infoMajorVersion m19: 16|8@1+ (1,0) [0|0] "" X
 SG_ RADC_infoBranchOrigin m19: 24|8@1+ (1,0) [0|0] "" X
 SG_ RADC_infoMaturity m19: 32|8@1+ (1,0) [0|0] "" X
 SG_ RADC_infoHardwareRevision m19: 40|8@1+ (1,0) [0|0] "" X
 SG_ RADC_infoBuildType m10: 8|8@1+ (1,0) [0|0] "" X
 SG_ RADC_infoBuildConfigID m10: 16|16@1+ (1,0) [0|0] "" X
 SG_ RADC_infoHardwareID m10: 32|16@1+ (1,0) [0|0] "" X
 SG_ RADC_infoComponentID m10: 48|16@1+ (1,0) [0|0] "" X
 SG_ RADC_infoPcbaID m11: 16|8@1+ (1,0) [0|0] "" X
 SG_ RADC_infoAssemblyID m11: 24|8@1+ (1,0) [0|0] "" X
 SG_ RADC_infoUsageID m11: 32|16@1+ (1,0) [0|0] "" X
 SG_ RADC_infoSubUsageID m11: 48|16@1+ (1,0) [0|0] "" X
 SG_ RADC_infoBootUdsProtoVersion m20: 8|8@1+ (1,0) [0|0] "" X
 SG_ RADC_infoBootloaderCRC m20: 32|32@1+ (1,0) [0|0] "" X
 SG_ RADC_infoApplicationCRC m13: 32|32@1+ (1,0) [0|0] "" X

BO_ 881 RCM_alertMatrix: 8 VEH
 SG_ RCM_matrixIndex M: 0|4@1+ (1,0) [0|0] "" X
 SG_ RCM_a000_crashDetected m0: 4|1@1+ (1,0) [0|0] "" X
 SG_ RCM_a001_nearDeploy m0: 5|1@1+ (1,0) [0|0] "" X
 SG_ RCM_a002_airbagsNotArmed m0: 6|1@1+ (1,0) [0|0] "" X
 SG_ RCM_a003_warningIndicator m0: 7|1@1+ (1,0) [0|0] "" X
 SG_ RCM_a004_internalFault m0: 8|1@1+ (1,0) [0|0] "" X
 SG_ RCM_a005_crcError m0: 9|1@1+ (1,0) [0|0] "" X
 SG_ RCM_a006_batteryVoltageRange m0: 10|1@1+ (1,0) [0|0] "" X
 SG_ RCM_a007_powerSupplyExternal m0: 11|1@1+ (1,0) [0|0] "" X
 SG_ RCM_a008_powerSupplyInternal m0: 12|1@1+ (1,0) [0|0] "" X
 SG_ RCM_a009_reprogramLimit m0: 13|1@1+ (1,0) [0|0] "" X
 SG_ RCM_a010_scmDisabled m0: 14|1@1+ (1,0) [0|0] "" X
 SG_ RCM_a011_eepromDataLocked m0: 15|1@1+ (1,0) [0|0] "" X
 SG_ RCM_a012_vinStorage m0: 16|1@1+ (1,0) [0|0] "" X
 SG_ RCM_a013_driverOrientation m0: 17|1@1+ (1,0) [0|0] "" X
 SG_ RCM_a014_driverABStage1 m0: 18|1@1+ (1,0) [0|0] "" X
 SG_ RCM_a015_driverABStage2 m0: 19|1@1+ (1,0) [0|0] "" X
 SG_ RCM_a016_passABStage1 m0: 20|1@1+ (1,0) [0|0] "" X
 SG_ RCM_a017_passABStage2 m0: 21|1@1+ (1,0) [0|0] "" X
 SG_ RCM_a018_passengerActiveVent m0: 22|1@1+ (1,0) [0|0] "" X
 SG_ RCM_a019_pretenShldrFrontLeft m0: 23|1@1+ (1,0) [0|0] "" X
 SG_ RCM_a020_pretenShldFrontRight m0: 24|1@1+ (1,0) [0|0] "" X
 SG_ RCM_a021_pretenLapFrontLeft m0: 25|1@1+ (1,0) [0|0] "" X
 SG_ RCM_a022_pretenLapFrontRight m0: 26|1@1+ (1,0) [0|0] "" X
 SG_ RCM_a023_loadLimiterLeftSide m0: 27|1@1+ (1,0) [0|0] "" X
 SG_ RCM_a024_loadLimiterRightSide m0: 28|1@1+ (1,0) [0|0] "" X
 SG_ RCM_a025_kneeABDriver m0: 29|1@1+ (1,0) [0|0] "" X
 SG_ RCM_a026_kneeABFrontPassenger m0: 30|1@1+ (1,0) [0|0] "" X
 SG_ RCM_a027_sideAB1stRowLeft m0: 31|1@1+ (1,0) [0|0] "" X
 SG_ RCM_a028_sideAB1stRowRight m0: 32|1@1+ (1,0) [0|0] "" X
 SG_ RCM_a029_driverABActiveVent m0: 33|1@1+ (1,0) [0|0] "" X
 SG_ RCM_a030_farSideInboardAirbag m0: 34|1@1+ (1,0) [0|0] "" X
 SG_ RCM_a031_frontCenterAirbag m0: 35|1@1+ (1,0) [0|0] "" X
 SG_ RCM_a032_curtainABLeft m0: 36|1@1+ (1,0) [0|0] "" X
 SG_ RCM_a033_curtainABRight m0: 37|1@1+ (1,0) [0|0] "" X
 SG_ RCM_a034_preten2ndRowLeft m0: 38|1@1+ (1,0) [0|0] "" X
 SG_ RCM_a035_preten2ndRowRight m0: 39|1@1+ (1,0) [0|0] "" X
 SG_ RCM_a036_curAB2ndRowLeft m0: 40|1@1+ (1,0) [0|0] "" X
 SG_ RCM_a037_curAB2ndRowRight m0: 41|1@1+ (1,0) [0|0] "" X
 SG_ RCM_a038_unusedA m0: 42|1@1+ (1,0) [0|0] "" X
 SG_ RCM_a039_unusedB m0: 43|1@1+ (1,0) [0|0] "" X
 SG_ RCM_a040_hoodActuatorRight m0: 44|1@1+ (1,0) [0|0] "" X
 SG_ RCM_a041_hoodActuatorLeft m0: 45|1@1+ (1,0) [0|0] "" X
 SG_ RCM_a042_ens1Line m0: 46|1@1+ (1,0) [0|0] "" X
 SG_ RCM_a043_ens2Line m0: 47|1@1+ (1,0) [0|0] "" X
 SG_ RCM_a044_upFrontSensorLeft m0: 48|1@1+ (1,0) [0|0] "" X
 SG_ RCM_a045_upFrontSensorRight m0: 49|1@1+ (1,0) [0|0] "" X
 SG_ RCM_a046_sideAccelBPillarLeft m0: 50|1@1+ (1,0) [0|0] "" X
 SG_ RCM_a047_sideAccelBPillarRight m0: 51|1@1+ (1,0) [0|0] "" X
 SG_ RCM_a048_sideAccelCPillarLeft m0: 52|1@1+ (1,0) [0|0] "" X
 SG_ RCM_a049_sideAccelCPillarRight m0: 53|1@1+ (1,0) [0|0] "" X
 SG_ RCM_a050_upFrontSensorCenter m0: 54|1@1+ (1,0) [0|0] "" X
 SG_ RCM_a051_pressureFrontLftDoor m0: 55|1@1+ (1,0) [0|0] "" X
 SG_ RCM_a052_pressureFrontRtDoor m0: 56|1@1+ (1,0) [0|0] "" X
 SG_ RCM_a053_pressurePedProLeft m0: 57|1@1+ (1,0) [0|0] "" X
 SG_ RCM_a054_pressurePedProRight m0: 58|1@1+ (1,0) [0|0] "" X
 SG_ RCM_a055_inertialMeasurement m0: 59|1@1+ (1,0) [0|0] "" X
 SG_ RCM_a056_passengerFrontOCS m0: 60|1@1+ (1,0) [0|0] "" X
 SG_ RCM_a057_driverOCS m0: 61|1@1+ (1,0) [0|0] "" X
 SG_ RCM_a058_buckle1stRowLeft m0: 62|1@1+ (1,0) [0|0] "" X
 SG_ RCM_a059_buckle1stRowRight m0: 63|1@1+ (1,0) [0|0] "" X
 SG_ RCM_a060_stpsLeft m1: 4|1@1+ (1,0) [0|0] "" X
 SG_ RCM_a061_stpsRight m1: 5|1@1+ (1,0) [0|0] "" X
 SG_ RCM_a062_alrSwitch m1: 6|1@1+ (1,0) [0|0] "" X
 SG_ RCM_a063_sbsw2ndRowRight m1: 7|1@1+ (1,0) [0|0] "" X
 SG_ RCM_a064_hardwareCodingPin1 m1: 8|1@1+ (1,0) [0|0] "" X
 SG_ RCM_a065_driverOrientConfigPin m1: 9|1@1+ (1,0) [0|0] "" X
 SG_ RCM_a066_seatBackSw2ndRowLeft m1: 10|1@1+ (1,0) [0|0] "" X
 SG_ RCM_a067_comCANInitFailure m1: 11|1@1+ (1,0) [0|0] "" X
 SG_ RCM_a068_comCHOff m1: 12|1@1+ (1,0) [0|0] "" X
 SG_ RCM_a069_comCHCANPH7 m1: 13|1@1+ (1,0) [0|0] "" X
 SG_ RCM_a070_comCHCANPH8 m1: 14|1@1+ (1,0) [0|0] "" X
 SG_ RCM_a071_comCHCANPH9 m1: 15|1@1+ (1,0) [0|0] "" X
 SG_ RCM_a072_comUnused m1: 16|1@1+ (1,0) [0|0] "" X
 SG_ RCM_a073_comCHCANPH4 m1: 17|1@1+ (1,0) [0|0] "" X
 SG_ RCM_a074_comCHCANPH5 m1: 18|1@1+ (1,0) [0|0] "" X
 SG_ RCM_a075_comCHCANPH6 m1: 19|1@1+ (1,0) [0|0] "" X
 SG_ RCM_a076_comEPBLStatus m1: 20|1@1+ (1,0) [0|0] "" X
 SG_ RCM_a077_comEPBRStatus m1: 21|1@1+ (1,0) [0|0] "" X
 SG_ RCM_a078_comOCS1PStatus m1: 22|1@1+ (1,0) [0|0] "" X
 SG_ RCM_a079_comOCS1DStatus m1: 23|1@1+ (1,0) [0|0] "" X
 SG_ RCM_a080_comGTWACS m1: 24|1@1+ (1,0) [0|0] "" X
 SG_ RCM_a081_comVCFRONTLVPwr m1: 25|1@1+ (1,0) [0|0] "" X
 SG_ RCM_a082_comUIodo m1: 26|1@1+ (1,0) [0|0] "" X
 SG_ RCM_a083_comGTWCarState m1: 27|1@1+ (1,0) [0|0] "" X
 SG_ RCM_a084_comTPMSStatus m1: 28|1@1+ (1,0) [0|0] "" X
 SG_ RCM_a085_comGTWCarConfig m1: 29|1@1+ (1,0) [0|0] "" X
 SG_ RCM_a086_comVINMIA m1: 30|1@1+ (1,0) [0|0] "" X
 SG_ RCM_a087_comCANSilent m1: 31|1@1+ (1,0) [0|0] "" X
 SG_ RCM_a088_comCHCANPH2 m1: 32|1@1+ (1,0) [0|0] "" X
 SG_ RCM_a089_comCHCANPH3 m1: 33|1@1+ (1,0) [0|0] "" X
 SG_ RCM_a090_comPartyBusOff m1: 34|1@1+ (1,0) [0|0] "" X
 SG_ RCM_a091_comEPAS3PsysStatus m1: 35|1@1+ (1,0) [0|0] "" X
 SG_ RCM_a092_comDASISF m1: 36|1@1+ (1,0) [0|0] "" X
 SG_ RCM_a093_comVCLEFTStatus m1: 37|1@1+ (1,0) [0|0] "" X
 SG_ RCM_a094_comVCRIGHTStatus m1: 38|1@1+ (1,0) [0|0] "" X
 SG_ RCM_a095_comESPstatus m1: 39|1@1+ (1,0) [0|0] "" X
 SG_ RCM_a096_comESPwheelSpeeds m1: 40|1@1+ (1,0) [0|0] "" X
 SG_ RCM_a097_comDIspeed m1: 41|1@1+ (1,0) [0|0] "" X
 SG_ RCM_a098_comDIchassisControl m1: 42|1@1+ (1,0) [0|0] "" X
 SG_ RCM_a099_comDItorque m1: 43|1@1+ (1,0) [0|0] "" X
 SG_ RCM_a100_comDIsystemStatus m1: 44|1@1+ (1,0) [0|0] "" X
 SG_ RCM_a101_idfSystem m1: 45|1@1+ (1,0) [0|0] "" X
 SG_ RCM_a102_imuYawR8OffstCompLim m1: 46|1@1+ (1,0) [0|0] "" X
 SG_ RCM_a103_imuPtchR8OffstCompLim m1: 47|1@1+ (1,0) [0|0] "" X
 SG_ RCM_a104_imuRollR8OffstCompLim m1: 48|1@1+ (1,0) [0|0] "" X
 SG_ RCM_a105_imuLongAccOffstCompLim m1: 49|1@1+ (1,0) [0|0] "" X
 SG_ RCM_a106_imuLatAccOffstCompLim m1: 50|1@1+ (1,0) [0|0] "" X
 SG_ RCM_a107_imuVertAccOffstCompLim m1: 51|1@1+ (1,0) [0|0] "" X
 SG_ RCM_a108_crashAlgoWakeup m1: 52|1@1+ (1,0) [0|0] "" X
 SG_ RCM_a109_abuseImmunity m1: 53|1@1+ (1,0) [0|0] "" X
 SG_ RCM_a110_factoryMode m1: 54|1@1+ (1,0) [0|0] "" X
 SG_ RCM_a111_diagnosticsEnabled m1: 55|1@1+ (1,0) [0|0] "" X
 SG_ RCM_a112_imuYawRate m1: 56|1@1+ (1,0) [0|0] "" X
 SG_ RCM_a113_imuPitchRate m1: 57|1@1+ (1,0) [0|0] "" X
 SG_ RCM_a114_imuRollRate m1: 58|1@1+ (1,0) [0|0] "" X
 SG_ RCM_a115_imuLinearAcceleration m1: 59|1@1+ (1,0) [0|0] "" X
 SG_ RCM_a116_imuLateralAcceleration m1: 60|1@1+ (1,0) [0|0] "" X
 SG_ RCM_a117_imuVerticalAcceleration m1: 61|1@1+ (1,0) [0|0] "" X
 SG_ RCM_a118_imuInPlaneAcceleration m1: 62|1@1+ (1,0) [0|0] "" X

BO_ 17 RCM_collision: 4 VEH
 SG_ RCM_collisionChecksum: 0|8@1+ (1,0) [0|0] "" X
 SG_ RCM_collisionCounter: 8|4@1+ (1,0) [0|0] "" X
 SG_ RCM_collisionFront: 18|2@1+ (1,0) [0|0] "" X
 SG_ RCM_collisionLeft: 16|2@1+ (1,0) [0|0] "" X
 SG_ RCM_collisionRear: 12|2@1+ (1,0) [0|0] "" X
 SG_ RCM_collisionRight: 14|2@1+ (1,0) [0|0] "" X
 SG_ RCM_collisionRollover: 20|2@1+ (1,0) [0|0] "" X
 SG_ RCM_collisionSeverity: 24|2@1+ (1,0) [0|0] "" X

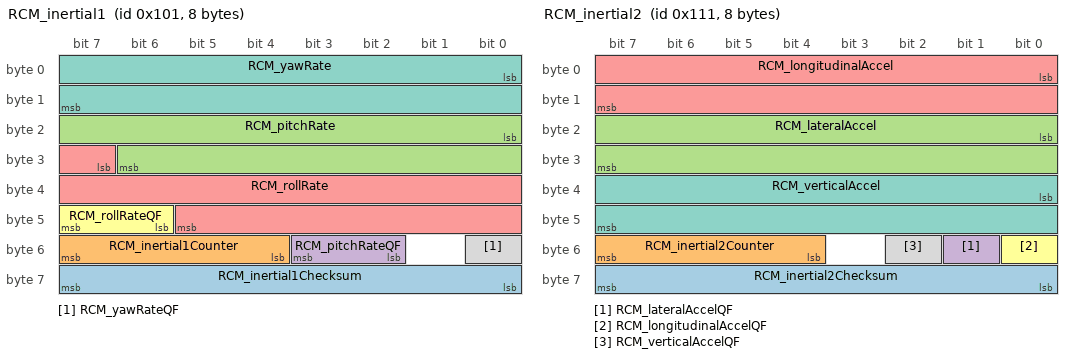
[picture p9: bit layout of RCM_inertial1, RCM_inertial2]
BO_ 257 RCM_inertial1: 8 CH
 SG_ RCM_inertial1Checksum: 56|8@1+ (1,0) [0|0] "" X
 SG_ RCM_inertial1Counter: 52|4@1+ (1,0) [0|0] "" X
 SG_ RCM_pitchRate: 16|15@1- (0.00025,0) [0|0] "rad/s" X
 SG_ RCM_pitchRateQF: 50|2@1+ (1,0) [0|0] "" X
 SG_ RCM_rollRate: 31|15@1- (0.00025,0) [0|0] "rad/s" X
 SG_ RCM_rollRateQF: 46|2@1+ (1,0) [0|0] "" X
 SG_ RCM_yawRate: 0|16@1- (0.0001,0) [0|0] "rad/s" X
 SG_ RCM_yawRateQF: 48|1@1+ (1,0) [0|0] "" X

BO_ 273 RCM_inertial2: 8 CH
 SG_ RCM_inertial2Checksum : 56|8@1+ (1,0) [0|255] "" X
 SG_ RCM_inertial2Counter : 52|4@1+ (1,0) [0|15] "" X
 SG_ RCM_lateralAccel : 16|16@1- (0.00125,0) [-40.9575|40.9575] "m/s^2" X
 SG_ RCM_lateralAccelQF : 49|1@1+ (1,0) [0|1] ""  X
 SG_ RCM_longitudinalAccel : 0|16@1- (0.00125,0) [-40.9575|40.9575] "m/s^2" X
 SG_ RCM_longitudinalAccelQF : 48|1@1+ (1,0) [0|1] "" X
 SG_ RCM_verticalAccel : 32|16@1- (0.00125,0) [-40.9575|40.9575] "m/s^2" X
 SG_ RCM_verticalAccelQF : 50|1@1+ (1,0) [0|1] ""  X

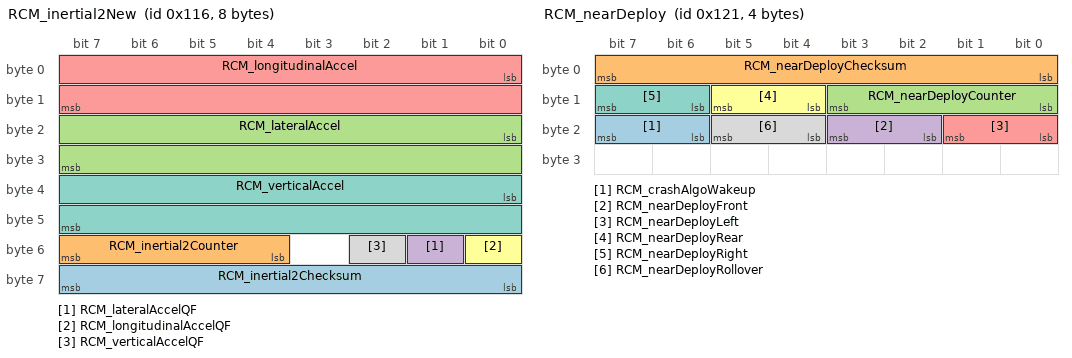
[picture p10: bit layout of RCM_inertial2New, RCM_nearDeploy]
BO_ 278 RCM_inertial2New: 8 CH
 SG_ RCM_inertial2Checksum : 56|8@1+ (1,0) [0|255] ""  Receiver
 SG_ RCM_inertial2Counter : 52|4@1+ (1,0) [0|15] ""  Receiver
 SG_ RCM_lateralAccel : 16|16@1- (0.00125,0) [-40.9575|40.9575] "m/s^2"  Receiver
 SG_ RCM_lateralAccelQF : 49|1@1+ (1,0) [0|1] ""  Receiver
 SG_ RCM_longitudinalAccel : 0|16@1- (0.00125,0) [-40.9575|40.9575] "m/s^2"  Receiver
 SG_ RCM_longitudinalAccelQF : 48|1@1+ (1,0) [0|1] ""  Receiver
 SG_ RCM_verticalAccel : 32|16@1- (0.00125,0) [-40.9575|40.9575] "m/s^2"  Receiver
 SG_ RCM_verticalAccelQF : 50|1@1+ (1,0) [0|1] ""  Receiver

BO_ 849 RCM_info: 8 CH
 SG_ RCM_infoIndex M: 0|8@1+ (1,0) [0|0] "" X
 SG_ RCM_infoBuildType m10: 8|8@1+ (1,0) [0|0] "" X
 SG_ RCM_infoComponentID m10: 48|16@1+ (1,0) [0|0] "" X
 SG_ RCM_infoPcbaID m11: 16|8@1+ (1,0) [0|0] "" X
 SG_ RCM_infoAssemblyID m11: 24|8@1+ (1,0) [0|0] "" X
 SG_ RCM_infoUsageID m11: 32|16@1+ (1,0) [0|0] "" X
 SG_ RCM_infoBootUdsProtoVersion m20: 8|8@1+ (1,0) [0|0] "" X
 SG_ RCM_infoBootloaderCRC m20: 32|32@1+ (1,0) [0|0] "" X
 SG_ RCM_infoApplicationCRC m13: 32|32@1+ (1,0) [0|0] "" X
 SG_ RCM_infoVariantCRC m22: 32|32@1+ (1,0) [0|0] "" X

BO_ 289 RCM_nearDeploy: 4 VEH
 SG_ RCM_crashAlgoWakeup: 22|2@1+ (1,0) [0|0] "" X
 SG_ RCM_nearDeployChecksum: 0|8@1+ (1,0) [0|0] "" X
 SG_ RCM_nearDeployCounter: 8|4@1+ (1,0) [0|0] "" X
 SG_ RCM_nearDeployFront: 18|2@1+ (1,0) [0|0] "" X
 SG_ RCM_nearDeployLeft: 16|2@1+ (1,0) [0|0] "" X
 SG_ RCM_nearDeployRear: 12|2@1+ (1,0) [0|0] "" X
 SG_ RCM_nearDeployRight: 14|2@1+ (1,0) [0|0] "" X
 SG_ RCM_nearDeployRollover: 20|2@1+ (1,0) [0|0] "" X

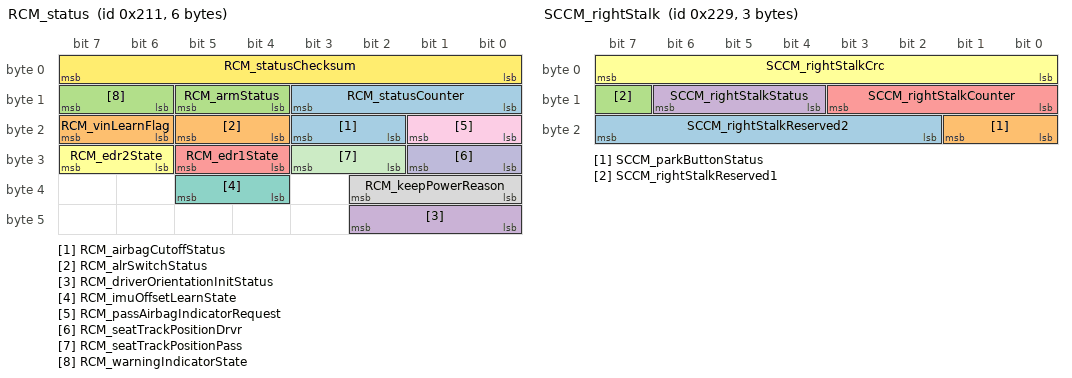
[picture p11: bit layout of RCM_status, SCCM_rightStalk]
BO_ 529 RCM_status: 6 VEH
 SG_ RCM_airbagCutoffStatus: 18|2@1+ (1,0) [0|0] "" X
 SG_ RCM_alrSwitchStatus: 20|2@1+ (1,0) [0|0] "" X
 SG_ RCM_armStatus: 12|2@1+ (1,0) [0|0] "" X
 SG_ RCM_driverOrientationInitStatus: 40|3@1+ (1,0) [0|0] "" X
 SG_ RCM_edr1State: 28|2@1+ (1,0) [0|0] "" X
 SG_ RCM_edr2State: 30|2@1+ (1,0) [0|0] "" X
 SG_ RCM_imuOffsetLearnState: 36|2@1+ (1,0) [0|0] "" X
 SG_ RCM_keepPowerReason: 32|3@1+ (1,0) [0|0] "" X
 SG_ RCM_passAirbagIndicatorRequest: 16|2@1+ (1,0) [0|0] "" X
 SG_ RCM_seatTrackPositionDrvr: 24|2@1+ (1,0) [0|0] "" X
 SG_ RCM_seatTrackPositionPass: 26|2@1+ (1,0) [0|0] "" X
 SG_ RCM_statusChecksum: 0|8@1+ (1,0) [0|0] "" X
 SG_ RCM_statusCounter: 8|4@1+ (1,0) [0|0] "" X
 SG_ RCM_vinLearnFlag: 22|2@1+ (1,0) [0|0] "" X
 SG_ RCM_warningIndicatorState: 14|2@1+ (1,0) [0|0] "" X

BO_ 1359 SCCM_alertMatrix: 8 VEH
 SG_ SCCM_matrixIndex M: 0|4@1+ (1,0) [0|0] "" X
 SG_ SCCM_a001_CANBusOff m0: 4|1@1+ (1,0) [0|0] "" X
 SG_ SCCM_a002_CANTOut m0: 5|1@1+ (1,0) [0|0] "" X
 SG_ SCCM_a003_highBeamOpen m0: 6|1@1+ (1,0) [0|0] "" X
 SG_ SCCM_a004_highBeamShortToGND m0: 7|1@1+ (1,0) [0|0] "" X
 SG_ SCCM_a005_tipWipeOpen m0: 8|1@1+ (1,0) [0|0] "" X
 SG_ SCCM_a006_tipWipeShortToGND m0: 9|1@1+ (1,0) [0|0] "" X
 SG_ SCCM_a007_turnIndComInfo m0: 10|1@1+ (1,0) [0|0] "" X
 SG_ SCCM_a008_turnIndInvalidTrans m0: 11|1@1+ (1,0) [0|0] "" X
 SG_ SCCM_a009_turnIndOpen m0: 12|1@1+ (1,0) [0|0] "" X
 SG_ SCCM_a010_turnIndShortToGnd m0: 13|1@1+ (1,0) [0|0] "" X
 SG_ SCCM_a011_turnIndHWErr m0: 14|1@1+ (1,0) [0|0] "" X
 SG_ SCCM_a012_turnGenErr m0: 15|1@1+ (1,0) [0|0] "" X
 SG_ SCCM_a013_voltageHigh m0: 16|1@1+ (1,0) [0|0] "" X
 SG_ SCCM_a014_voltageLow m0: 17|1@1+ (1,0) [0|0] "" X
 SG_ SCCM_a015_softwareError m0: 18|1@1+ (1,0) [0|0] "" X
 SG_ SCCM_a016_hardwareError m0: 19|1@1+ (1,0) [0|0] "" X
 SG_ SCCM_a017_memoryError m0: 20|1@1+ (1,0) [0|0] "" X
 SG_ SCCM_a018_angleSpeedOutOfRange m0: 21|1@1+ (1,0) [0|0] "" X
 SG_ SCCM_a019_angleSpeedAboveLimit m0: 22|1@1+ (1,0) [0|0] "" X
 SG_ SCCM_a020_angleInternalError m0: 23|1@1+ (1,0) [0|0] "" X
 SG_ SCCM_a021_gearStalkSignalInvalid m0: 24|1@1+ (1,0) [0|0] "" X
 SG_ SCCM_a022_gearStalkOpenCircuit m0: 25|1@1+ (1,0) [0|0] "" X
 SG_ SCCM_a023_gearStalkShortCircuit m0: 26|1@1+ (1,0) [0|0] "" X
 SG_ SCCM_a024_gearStalkGenErr m0: 27|1@1+ (1,0) [0|0] "" X
 SG_ SCCM_a025_runTimeError m0: 28|1@1+ (1,0) [0|0] "" X
 SG_ SCCM_a026_parkButtonInvalidSignal m0: 29|1@1+ (1,0) [0|0] "" X
 SG_ SCCM_a027_parkButtonOpenCircuit m0: 30|1@1+ (1,0) [0|0] "" X
 SG_ SCCM_a028_parkButtonShortToGround m0: 31|1@1+ (1,0) [0|0] "" X
 SG_ SCCM_a029_parkButtonMalfunction m0: 32|1@1+ (1,0) [0|0] "" X

BO_ 816 SCCM_info: 8 Vector__XXX
 SG_ SCCM_infoComponentId m10 : 48|16@1+ (1,0) [0|0] "" Vector__XXX
 SG_ SCCM_infoSubUsageId m11 : 48|16@1+ (1,0) [0|0] "" Vector__XXX
 SG_ SCCM_infoBootCrc m20 : 32|32@1+ (1,0) [0|0] "" Vector__XXX
 SG_ SCCM_infoBootSvnUrlHash m14 : 32|32@1+ (1,0) [0|0] "" Vector__XXX
 SG_ SCCM_infoHardwareId m10 : 32|16@1+ (1,0) [0|0] "" Vector__XXX
 SG_ SCCM_infoUsageId m11 : 32|16@1+ (1,0) [0|0] "" Vector__XXX
 SG_ SCCM_infoAppCrc m13 : 39|32@0+ (1,0) [0|0] "" Vector__XXX
 SG_ SCCM_infoAssemblyId m11 : 24|8@1+ (1,0) [0|0] "" Vector__XXX
 SG_ SCCM_infoBuildConfigId m10 : 16|16@1+ (1,0) [0|0] "" Vector__XXX
 SG_ SCCM_infoPcbaId m11 : 16|8@1+ (1,0) [0|0] "" Vector__XXX
 SG_ SCCM_infoSubcomponent1Version m16 : 16|32@1+ (1,0) [0|0] "" Vector__XXX
 SG_ SCCM_infoAppSvnHash m17 : 8|56@1+ (1,0) [0|0] "" Vector__XXX
 SG_ SCCM_infoBootSvnHash m18 : 8|56@1+ (1,0) [0|0] "" Vector__XXX
 SG_ SCCM_infoBootSvnRev m14 : 8|24@1+ (1,0) [0|0] "" Vector__XXX
 SG_ SCCM_infoBuildType m10 : 8|8@1+ (1,0) [0|0] "" Vector__XXX
 SG_ SCCM_infoPlatformType m13 : 8|8@1+ (1,0) [0|0] "" Vector__XXX
 SG_ SCCM_infoUdsProtoVersion m20 : 8|8@1+ (1,0) [0|0] "" Vector__XXX
 SG_ SCCM_infoIndex M : 0|8@1+ (1,0) [0|0] "" Vector__XXX

BO_ 553 SCCM_rightStalk: 3 Vector__XXX
 SG_ SCCM_rightStalkReserved2 : 18|6@1+ (1,0) [0|0] "" Vector__XXX
 SG_ SCCM_parkButtonStatus : 16|2@1+ (1,0) [0|0] "" Vector__XXX
 SG_ SCCM_rightStalkReserved1 : 15|1@1+ (1,0) [0|0] "" Vector__XXX
 SG_ SCCM_rightStalkStatus : 12|3@1+ (1,0) [0|0] "" Vector__XXX
 SG_ SCCM_rightStalkCounter : 8|4@1+ (1,0) [0|0] "" Vector__XXX
 SG_ SCCM_rightStalkCrc : 0|8@1+ (1,0) [0|0] "" Vector__XXX

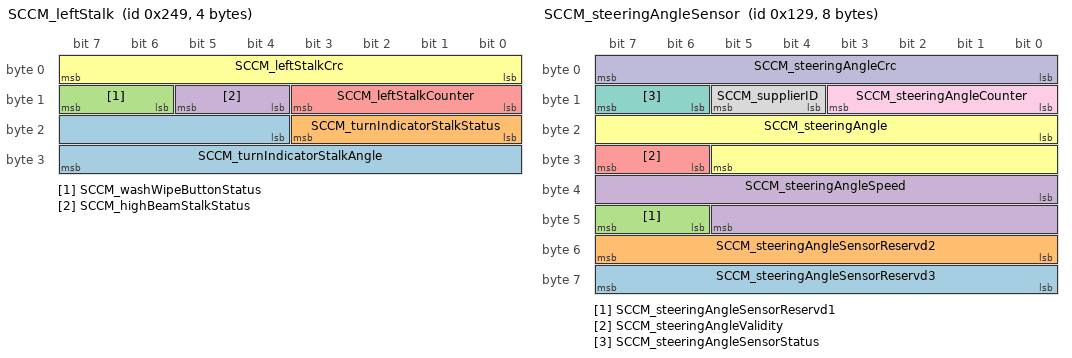
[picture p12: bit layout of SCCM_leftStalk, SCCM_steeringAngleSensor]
BO_ 585 SCCM_leftStalk: 4 Vector__XXX
 SG_ SCCM_turnIndicatorStalkAngle : 20|12@1+ (0.1,-180) [0|0] "" Vector__XXX
 SG_ SCCM_turnIndicatorStalkStatus : 16|4@1+ (1,0) [0|0] "" Vector__XXX
 SG_ SCCM_washWipeButtonStatus : 14|2@1+ (1,0) [0|0] "" Vector__XXX
 SG_ SCCM_highBeamStalkStatus : 12|2@1+ (1,0) [0|0] "" Vector__XXX
 SG_ SCCM_leftStalkCounter : 8|4@1+ (1,0) [0|0] "" Vector__XXX
 SG_ SCCM_leftStalkCrc : 0|8@1+ (1,0) [0|0] "" Vector__XXX

BO_ 297 SCCM_steeringAngleSensor: 8 Vector__XXX
 SG_ SCCM_steeringAngleSensorReservd3 : 56|8@1+ (1,0) [0|0] "" Vector__XXX
 SG_ SCCM_steeringAngleSensorReservd2 : 48|8@1+ (1,0) [0|0] "" Vector__XXX
 SG_ SCCM_steeringAngleSensorReservd1 : 46|2@1+ (1,0) [0|0] "" Vector__XXX
 SG_ SCCM_steeringAngleSpeed : 32|14@1+ (0.5,-4096) [0|0] "" Vector__XXX
 SG_ SCCM_steeringAngleValidity : 30|2@1+ (1,0) [0|0] "" Vector__XXX
 SG_ SCCM_steeringAngle : 16|14@1+ (0.1,-819.2) [0|0] "" Vector__XXX
 SG_ SCCM_steeringAngleSensorStatus : 14|2@1+ (1,0) [0|0] "" Vector__XXX
 SG_ SCCM_supplierID : 12|2@1+ (1,0) [0|0] "" Vector__XXX
 SG_ SCCM_steeringAngleCounter : 8|4@1+ (1,0) [0|0] "" Vector__XXX
 SG_ SCCM_steeringAngleCrc : 0|8@1+ (1,0) [0|0] "" Vector__XXX

BO_ 815 SCM_alertMatrix1: 8 CH
 SG_ SCM_a001_hwDSPfault: 0|1@1+ (1,0) [0|0] "" X
 SG_ SCM_a002_hwIbatOC: 1|1@1+ (1,0) [0|0] "" X
 SG_ SCM_a003_hwCordOT: 2|1@1+ (1,0) [0|0] "" X
 SG_ SCM_a004_hwVbusOV: 3|1@1+ (1,0) [0|0] "" X
 SG_ SCM_a005_hwHVIL: 4|1@1+ (1,0) [0|0] "" X
 SG_ SCM_a006_hwWeld_V1: 5|1@1+ (1,0) [0|0] "" X
 SG_ SCM_a007_hwWeld_V2: 6|1@1+ (1,0) [0|0] "" X
 SG_ SCM_a008_hwOpen_V1: 7|1@1+ (1,0) [0|0] "" X
 SG_ SCM_a009_hwOpen_V2: 8|1@1+ (1,0) [0|0] "" X
 SG_ SCM_a010_hwIllegalCntrCmdV1: 9|1@1+ (1,0) [0|0] "" X
 SG_ SCM_a011_hwIllegalCntrCmdInt: 10|1@1+ (1,0) [0|0] "" X
 SG_ SCM_a012_hwIllegalCntrCmdV2: 11|1@1+ (1,0) [0|0] "" X
 SG_ SCM_a013_cordTempHiFoldBk: 12|1@1+ (1,0) [0|0] "" X
 SG_ SCM_a014_coolantTempHiFoldBk: 13|1@1+ (1,0) [0|0] "" X
 SG_ SCM_a015_unusedHW15: 14|1@1+ (1,0) [0|0] "" X
 SG_ SCM_a016_unusedHW16: 15|1@1+ (1,0) [0|0] "" X
 SG_ SCM_a017_unusedHW17: 16|1@1+ (1,0) [0|0] "" X
 SG_ SCM_a018_unusedHW18: 17|1@1+ (1,0) [0|0] "" X
 SG_ SCM_a019_unusedHW19: 18|1@1+ (1,0) [0|0] "" X
 SG_ SCM_a020_unusedHW20: 19|1@1+ (1,0) [0|0] "" X
 SG_ SCM_a021_unusedHW21: 20|1@1+ (1,0) [0|0] "" X
 SG_ SCM_a022_fastChargeLimitActiveV1: 21|1@1+ (1,0) [0|0] "" X
 SG_ SCM_a023_fastChargeLimitActiveV2: 22|1@1+ (1,0) [0|0] "" X
 SG_ SCM_a024_emergencyShutdown: 23|1@1+ (1,0) [0|0] "" X
 SG_ SCM_a025_internalIsolationFault: 24|1@1+ (1,0) [0|0] "" X
 SG_ SCM_a026_internalIsolationLow: 25|1@1+ (1,0) [0|0] "" X
 SG_ SCM_a027_externalIsolationLow: 26|1@1+ (1,0) [0|0] "" X
 SG_ SCM_a028_isolationRationality: 27|1@1+ (1,0) [0|0] "" X
 SG_ SCM_a029_VbatOV: 28|1@1+ (1,0) [0|0] "" X
 SG_ SCM_a030_VbusOV: 29|1@1+ (1,0) [0|0] "" X
 SG_ SCM_a031_IbatOC: 30|1@1+ (1,0) [0|0] "" X
 SG_ SCM_a032_VBatRationality: 31|1@1+ (1,0) [0|0] "" X
 SG_ SCM_a033_VBusRationality: 32|1@1+ (1,0) [0|0] "" X
 SG_ SCM_a034_IBatRationality: 33|1@1+ (1,0) [0|0] "" X
 SG_ SCM_a035_unexpectedVbusBehavior: 34|1@1+ (1,0) [0|0] "" X
 SG_ SCM_a036_internalContactorWelded: 35|1@1+ (1,0) [0|0] "" X
 SG_ SCM_a037_outputContactorWelded: 36|1@1+ (1,0) [0|0] "" X
 SG_ SCM_a038_contactorFailedOpen: 37|1@1+ (1,0) [0|0] "" X
 SG_ SCM_a039_ibatRegulation: 38|1@1+ (1,0) [0|0] "" X
 SG_ SCM_a040_plus12VOutOfRange: 39|1@1+ (1,0) [0|0] "" X
 SG_ SCM_a041_minus12VOutOfRange: 40|1@1+ (1,0) [0|0] "" X
 SG_ SCM_a042_pilotOutOfRange: 41|1@1+ (1,0) [0|0] "" X
 SG_ SCM_a043_pilotRationality: 42|1@1+ (1,0) [0|0] "" X
 SG_ SCM_a044_proximityRationality: 43|1@1+ (1,0) [0|0] "" X
 SG_ SCM_a045_pcbaOT: 44|1@1+ (1,0) [0|0] "" X
 SG_ SCM_a046_coolantOT: 45|1@1+ (1,0) [0|0] "" X
 SG_ SCM_a047_cordOT: 46|1@1+ (1,0) [0|0] "" X
 SG_ SCM_a048_ambientOT: 47|1@1+ (1,0) [0|0] "" X
 SG_ SCM_a049_pcbaTempRationality: 48|1@1+ (1,0) [0|0] "" X
 SG_ SCM_a050_coolantTempRationality: 49|1@1+ (1,0) [0|0] "" X
 SG_ SCM_a051_cordTempRationality: 50|1@1+ (1,0) [0|0] "" X
 SG_ SCM_a052_ambientTempRationality: 51|1@1+ (1,0) [0|0] "" X
 SG_ SCM_a053_unexpectedThermalBehavi: 52|1@1+ (1,0) [0|0] "" X
 SG_ SCM_a054_pumpRegulation: 53|1@1+ (1,0) [0|0] "" X
 SG_ SCM_a055_coolantLevelLow: 54|1@1+ (1,0) [0|0] "" X
 SG_ SCM_a056_stateTransitionDenied: 55|1@1+ (1,0) [0|0] "" X
 SG_ SCM_a057_watchdogReset: 56|1@1+ (1,0) [0|0] "" X
 SG_ SCM_a058_adcRef: 57|1@1+ (1,0) [0|0] "" X
 SG_ SCM_a059_memoryError: 58|1@1+ (1,0) [0|0] "" X
 SG_ SCM_a060_swHVIL: 59|1@1+ (1,0) [0|0] "" X
 SG_ SCM_a061_postOutOfService: 60|1@1+ (1,0) [0|0] "" X
 SG_ SCM_a062_unused: 61|1@1+ (1,0) [0|0] "" X
 SG_ SCM_a063_canRationality: 62|1@1+ (1,0) [0|0] "" X
 SG_ SCM_a064_vehicleCommandTimeout: 63|1@1+ (1,0) [0|0] "" X

BO_ 1355 SCM_alertMatrix2: 8 VEH
 SG_ SCM_a065_vBatRationalityStage1: 0|1@1+ (1,0) [0|0] "" X
 SG_ SCM_a066_vBatRationalityStage2: 1|1@1+ (1,0) [0|0] "" X
 SG_ SCM_a067_vBatRationalityStage3: 2|1@1+ (1,0) [0|0] "" X
 SG_ SCM_a068_vBatRationalityStage4: 3|1@1+ (1,0) [0|0] "" X
 SG_ SCM_a069_vStageRationalityV1: 4|1@1+ (1,0) [0|0] "" X
 SG_ SCM_a070_vStageRationalityV2: 5|1@1+ (1,0) [0|0] "" X
 SG_ SCM_a071_chargerMIA: 6|1@1+ (1,0) [0|0] "" X
 SG_ SCM_a072_gtwMIA: 7|1@1+ (1,0) [0|0] "" X
 SG_ SCM_a073_lccMIA: 8|1@1+ (1,0) [0|0] "" X
 SG_ SCM_a074_isoVDiffHi: 9|1@1+ (1,0) [0|0] "" X
 SG_ SCM_a075_leakageTestAbsDecayLow: 10|1@1+ (1,0) [0|0] "" X
 SG_ SCM_a076_bmsMIA: 11|1@1+ (1,0) [0|0] "" X
 SG_ SCM_a077_unexpectedVbatBehavior: 12|1@1+ (1,0) [0|0] "" X
 SG_ SCM_a078_voltageMatchTimeout: 13|1@1+ (1,0) [0|0] "" X
 SG_ SCM_a079_unexpectedVbat: 14|1@1+ (1,0) [0|0] "" X
 SG_ SCM_a080_lccFaulted: 15|1@1+ (1,0) [0|0] "" X
 SG_ SCM_a081_rmsInputVoltageHigh: 16|1@1+ (1,0) [0|0] "" X
 SG_ SCM_a082_VbatUV: 17|1@1+ (1,0) [0|0] "" X
 SG_ SCM_a083_chargeCurrentLimited: 18|1@1+ (1,0) [0|0] "" X
 SG_ SCM_a084_unused84: 19|1@1+ (1,0) [0|0] "" X
 SG_ SCM_a085_unused85: 20|1@1+ (1,0) [0|0] "" X
 SG_ SCM_a086_lccResetDetected: 21|1@1+ (1,0) [0|0] "" X
 SG_ SCM_a087_posCordTempRationality: 22|1@1+ (1,0) [0|0] "" X
 SG_ SCM_a088_negCordTempRationality: 23|1@1+ (1,0) [0|0] "" X
 SG_ SCM_a089_posCordOT: 24|1@1+ (1,0) [0|0] "" X
 SG_ SCM_a090_negCordOT: 25|1@1+ (1,0) [0|0] "" X
 SG_ SCM_a091_voltageRiseDetection: 26|1@1+ (1,0) [0|0] "" X
 SG_ SCM_a092_cabEnableDeasserted: 27|1@1+ (1,0) [0|0] "" X
 SG_ SCM_a093_unused93: 28|1@1+ (1,0) [0|0] "" X
 SG_ SCM_a094_unused94: 29|1@1+ (1,0) [0|0] "" X
 SG_ SCM_a095_unused95: 30|1@1+ (1,0) [0|0] "" X
 SG_ SCM_a096_unused96: 31|1@1+ (1,0) [0|0] "" X
 SG_ SCM_a097_unused97: 32|1@1+ (1,0) [0|0] "" X
 SG_ SCM_a098_unused98: 33|1@1+ (1,0) [0|0] "" X
 SG_ SCM_a099_unused99: 34|1@1+ (1,0) [0|0] "" X
 SG_ SCM_a100_unused100: 35|1@1+ (1,0) [0|0] "" X
 SG_ SCM_a101_unused101: 36|1@1+ (1,0) [0|0] "" X
 SG_ SCM_a102_unused102: 37|1@1+ (1,0) [0|0] "" X
 SG_ SCM_a103_unused103: 38|1@1+ (1,0) [0|0] "" X
 SG_ SCM_a104_unused104: 39|1@1+ (1,0) [0|0] "" X
 SG_ SCM_a105_unused105: 40|1@1+ (1,0) [0|0] "" X
 SG_ SCM_a106_unused106: 41|1@1+ (1,0) [0|0] "" X
 SG_ SCM_a107_unused107: 42|1@1+ (1,0) [0|0] "" X
 SG_ SCM_a108_unused108: 43|1@1+ (1,0) [0|0] "" X
 SG_ SCM_a109_unused109: 44|1@1+ (1,0) [0|0] "" X
 SG_ SCM_a110_unused110: 45|1@1+ (1,0) [0|0] "" X
 SG_ SCM_a111_unused111: 46|1@1+ (1,0) [0|0] "" X
 SG_ SCM_a112_unused112: 47|1@1+ (1,0) [0|0] "" X
 SG_ SCM_a113_unused113: 48|1@1+ (1,0) [0|0] "" X
 SG_ SCM_a114_unused114: 49|1@1+ (1,0) [0|0] "" X
 SG_ SCM_a115_unused115: 50|1@1+ (1,0) [0|0] "" X
 SG_ SCM_a116_unused116: 51|1@1+ (1,0) [0|0] "" X
 SG_ SCM_a117_unused117: 52|1@1+ (1,0) [0|0] "" X
 SG_ SCM_a118_unused118: 53|1@1+ (1,0) [0|0] "" X
 SG_ SCM_a119_unused119: 54|1@1+ (1,0) [0|0] "" X
 SG_ SCM_a120_unused120: 55|1@1+ (1,0) [0|0] "" X
 SG_ SCM_a121_unused121: 56|1@1+ (1,0) [0|0] "" X
 SG_ SCM_a122_unused122: 57|1@1+ (1,0) [0|0] "" X
 SG_ SCM_a123_unused123: 58|1@1+ (1,0) [0|0] "" X
 SG_ SCM_a124_unused124: 59|1@1+ (1,0) [0|0] "" X
 SG_ SCM_a125_unused125: 60|1@1+ (1,0) [0|0] "" X
 SG_ SCM_a126_unused126: 61|1@1+ (1,0) [0|0] "" X
 SG_ SCM_a127_unused127: 62|1@1+ (1,0) [0|0] "" X
 SG_ SCM_a128_unused128: 63|1@1+ (1,0) [0|0] "" X

BO_ 869 SCS_alertMatrix1: 8 VEH
 SG_ SCS_a001_hwDSPfault: 0|1@1+ (1,0) [0|0] "" X
 SG_ SCS_a002_hwIbatOC: 1|1@1+ (1,0) [0|0] "" X
 SG_ SCS_a003_hwCordOT: 2|1@1+ (1,0) [0|0] "" X
 SG_ SCS_a004_hwVbusOV: 3|1@1+ (1,0) [0|0] "" X
 SG_ SCS_a005_hwHVIL: 4|1@1+ (1,0) [0|0] "" X
 SG_ SCS_a006_hwWeld_V1: 5|1@1+ (1,0) [0|0] "" X
 SG_ SCS_a007_hwWeld_V2: 6|1@1+ (1,0) [0|0] "" X
 SG_ SCS_a008_hwOpen_V1: 7|1@1+ (1,0) [0|0] "" X
 SG_ SCS_a009_hwOpen_V2: 8|1@1+ (1,0) [0|0] "" X
 SG_ SCS_a010_hwIllegalCntrCmdV1: 9|1@1+ (1,0) [0|0] "" X
 SG_ SCS_a011_hwIllegalCntrCmdInt: 10|1@1+ (1,0) [0|0] "" X
 SG_ SCS_a012_hwIllegalCntrCmdV2: 11|1@1+ (1,0) [0|0] "" X
 SG_ SCS_a013_cordTempHiFoldBk: 12|1@1+ (1,0) [0|0] "" X
 SG_ SCS_a014_coolantTempHiFoldBk: 13|1@1+ (1,0) [0|0] "" X
 SG_ SCS_a015_unusedHW15: 14|1@1+ (1,0) [0|0] "" X
 SG_ SCS_a016_unusedHW16: 15|1@1+ (1,0) [0|0] "" X
 SG_ SCS_a017_unusedHW17: 16|1@1+ (1,0) [0|0] "" X
 SG_ SCS_a018_unusedHW18: 17|1@1+ (1,0) [0|0] "" X
 SG_ SCS_a019_unusedHW19: 18|1@1+ (1,0) [0|0] "" X
 SG_ SCS_a020_unusedHW20: 19|1@1+ (1,0) [0|0] "" X
 SG_ SCS_a021_unusedHW21: 20|1@1+ (1,0) [0|0] "" X
 SG_ SCS_a022_fastChargeLimitActiveV1: 21|1@1+ (1,0) [0|0] "" X
 SG_ SCS_a023_fastChargeLimitActiveV2: 22|1@1+ (1,0) [0|0] "" X
 SG_ SCS_a024_emergencyShutdown: 23|1@1+ (1,0) [0|0] "" X
 SG_ SCS_a025_internalIsolationFault: 24|1@1+ (1,0) [0|0] "" X
 SG_ SCS_a026_internalIsolationLow: 25|1@1+ (1,0) [0|0] "" X
 SG_ SCS_a027_externalIsolationLow: 26|1@1+ (1,0) [0|0] "" X
 SG_ SCS_a028_isolationRationality: 27|1@1+ (1,0) [0|0] "" X
 SG_ SCS_a029_VbatOV: 28|1@1+ (1,0) [0|0] "" X
 SG_ SCS_a030_VbusOV: 29|1@1+ (1,0) [0|0] "" X
 SG_ SCS_a031_IbatOC: 30|1@1+ (1,0) [0|0] "" X
 SG_ SCS_a032_VBatRationality: 31|1@1+ (1,0) [0|0] "" X
 SG_ SCS_a033_VBusRationality: 32|1@1+ (1,0) [0|0] "" X
 SG_ SCS_a034_IBatRationality: 33|1@1+ (1,0) [0|0] "" X
 SG_ SCS_a035_unexpectedVbusBehavior: 34|1@1+ (1,0) [0|0] "" X
 SG_ SCS_a036_internalContactorWelded: 35|1@1+ (1,0) [0|0] "" X
 SG_ SCS_a037_outputContactorWelded: 36|1@1+ (1,0) [0|0] "" X
 SG_ SCS_a038_contactorFailedOpen: 37|1@1+ (1,0) [0|0] "" X
 SG_ SCS_a039_ibatRegulation: 38|1@1+ (1,0) [0|0] "" X
 SG_ SCS_a040_plus12VOutOfRange: 39|1@1+ (1,0) [0|0] "" X
 SG_ SCS_a041_minus12VOutOfRange: 40|1@1+ (1,0) [0|0] "" X
 SG_ SCS_a042_pilotOutOfRange: 41|1@1+ (1,0) [0|0] "" X
 SG_ SCS_a043_pilotRationality: 42|1@1+ (1,0) [0|0] "" X
 SG_ SCS_a044_proximityRationality: 43|1@1+ (1,0) [0|0] "" X
 SG_ SCS_a045_pcbaOT: 44|1@1+ (1,0) [0|0] "" X
 SG_ SCS_a046_coolantOT: 45|1@1+ (1,0) [0|0] "" X
 SG_ SCS_a047_cordOT: 46|1@1+ (1,0) [0|0] "" X
 SG_ SCS_a048_ambientOT: 47|1@1+ (1,0) [0|0] "" X
 SG_ SCS_a049_pcbaTempRationality: 48|1@1+ (1,0) [0|0] "" X
 SG_ SCS_a050_coolantTempRationality: 49|1@1+ (1,0) [0|0] "" X
 SG_ SCS_a051_cordTempRationality: 50|1@1+ (1,0) [0|0] "" X
 SG_ SCS_a052_ambientTempRationality: 51|1@1+ (1,0) [0|0] "" X
 SG_ SCS_a053_unexpectedThermalBehavi: 52|1@1+ (1,0) [0|0] "" X
 SG_ SCS_a054_pumpRegulation: 53|1@1+ (1,0) [0|0] "" X
 SG_ SCS_a055_coolantLevelLow: 54|1@1+ (1,0) [0|0] "" X
 SG_ SCS_a056_stateTransitionDenied: 55|1@1+ (1,0) [0|0] "" X
 SG_ SCS_a057_watchdogReset: 56|1@1+ (1,0) [0|0] "" X
 SG_ SCS_a058_adcRef: 57|1@1+ (1,0) [0|0] "" X
 SG_ SCS_a059_memoryError: 58|1@1+ (1,0) [0|0] "" X
 SG_ SCS_a060_swHVIL: 59|1@1+ (1,0) [0|0] "" X
 SG_ SCS_a061_postOutOfService: 60|1@1+ (1,0) [0|0] "" X
 SG_ SCS_a062_unused: 61|1@1+ (1,0) [0|0] "" X
 SG_ SCS_a063_canRationality: 62|1@1+ (1,0) [0|0] "" X
 SG_ SCS_a064_vehicleCommandTimeout: 63|1@1+ (1,0) [0|0] "" X

BO_ 880 SCS_alertMatrix2: 8 CH
 SG_ SCS_a065_vBatRationalityStage1: 0|1@1+ (1,0) [0|0] "" X
 SG_ SCS_a066_vBatRationalityStage2: 1|1@1+ (1,0) [0|0] "" X
 SG_ SCS_a067_vBatRationalityStage3: 2|1@1+ (1,0) [0|0] "" X
 SG_ SCS_a068_vBatRationalityStage4: 3|1@1+ (1,0) [0|0] "" X
 SG_ SCS_a069_vStageRationalityV1: 4|1@1+ (1,0) [0|0] "" X
 SG_ SCS_a070_vStageRationalityV2: 5|1@1+ (1,0) [0|0] "" X
 SG_ SCS_a071_chargerMIA: 6|1@1+ (1,0) [0|0] "" X
 SG_ SCS_a072_gtwMIA: 7|1@1+ (1,0) [0|0] "" X
 SG_ SCS_a073_lccMIA: 8|1@1+ (1,0) [0|0] "" X
 SG_ SCS_a074_isoVDiffHi: 9|1@1+ (1,0) [0|0] "" X
 SG_ SCS_a075_leakageTestAbsDecayLow: 10|1@1+ (1,0) [0|0] "" X
 SG_ SCS_a076_bmsMIA: 11|1@1+ (1,0) [0|0] "" X
 SG_ SCS_a077_unexpectedVbatBehavior: 12|1@1+ (1,0) [0|0] "" X
 SG_ SCS_a078_voltageMatchTimeout: 13|1@1+ (1,0) [0|0] "" X
 SG_ SCS_a079_unexpectedVbat: 14|1@1+ (1,0) [0|0] "" X
 SG_ SCS_a080_lccFaulted: 15|1@1+ (1,0) [0|0] "" X
 SG_ SCS_a081_rmsInputVoltageHigh: 16|1@1+ (1,0) [0|0] "" X
 SG_ SCS_a082_VbatUV: 17|1@1+ (1,0) [0|0] "" X
 SG_ SCS_a083_chargeCurrentLimited: 18|1@1+ (1,0) [0|0] "" X
 SG_ SCS_a084_unused84: 19|1@1+ (1,0) [0|0] "" X
 SG_ SCS_a085_unused85: 20|1@1+ (1,0) [0|0] "" X
 SG_ SCS_a086_lccResetDetected: 21|1@1+ (1,0) [0|0] "" X
 SG_ SCS_a087_posCordTempRationality: 22|1@1+ (1,0) [0|0] "" X
 SG_ SCS_a088_negCordTempRationality: 23|1@1+ (1,0) [0|0] "" X
 SG_ SCS_a089_posCordOT: 24|1@1+ (1,0) [0|0] "" X
 SG_ SCS_a090_negCordOT: 25|1@1+ (1,0) [0|0] "" X
 SG_ SCS_a091_voltageRiseDetection: 26|1@1+ (1,0) [0|0] "" X
 SG_ SCS_a092_cabEnableDeasserted: 27|1@1+ (1,0) [0|0] "" X
 SG_ SCS_a093_unused93: 28|1@1+ (1,0) [0|0] "" X
 SG_ SCS_a094_unused94: 29|1@1+ (1,0) [0|0] "" X
 SG_ SCS_a095_unused95: 30|1@1+ (1,0) [0|0] "" X
 SG_ SCS_a096_unused96: 31|1@1+ (1,0) [0|0] "" X
 SG_ SCS_a097_unused97: 32|1@1+ (1,0) [0|0] "" X
 SG_ SCS_a098_unused98: 33|1@1+ (1,0) [0|0] "" X
 SG_ SCS_a099_unused99: 34|1@1+ (1,0) [0|0] "" X
 SG_ SCS_a100_unused100: 35|1@1+ (1,0) [0|0] "" X
 SG_ SCS_a101_unused101: 36|1@1+ (1,0) [0|0] "" X
 SG_ SCS_a102_unused102: 37|1@1+ (1,0) [0|0] "" X
 SG_ SCS_a103_unused103: 38|1@1+ (1,0) [0|0] "" X
 SG_ SCS_a104_unused104: 39|1@1+ (1,0) [0|0] "" X
 SG_ SCS_a105_unused105: 40|1@1+ (1,0) [0|0] "" X
 SG_ SCS_a106_unused106: 41|1@1+ (1,0) [0|0] "" X
 SG_ SCS_a107_unused107: 42|1@1+ (1,0) [0|0] "" X
 SG_ SCS_a108_unused108: 43|1@1+ (1,0) [0|0] "" X
 SG_ SCS_a109_unused109: 44|1@1+ (1,0) [0|0] "" X
 SG_ SCS_a110_unused110: 45|1@1+ (1,0) [0|0] "" X
 SG_ SCS_a111_unused111: 46|1@1+ (1,0) [0|0] "" X
 SG_ SCS_a112_unused112: 47|1@1+ (1,0) [0|0] "" X
 SG_ SCS_a113_unused113: 48|1@1+ (1,0) [0|0] "" X
 SG_ SCS_a114_unused114: 49|1@1+ (1,0) [0|0] "" X
 SG_ SCS_a115_unused115: 50|1@1+ (1,0) [0|0] "" X
 SG_ SCS_a116_unused116: 51|1@1+ (1,0) [0|0] "" X
 SG_ SCS_a117_unused117: 52|1@1+ (1,0) [0|0] "" X
 SG_ SCS_a118_unused118: 53|1@1+ (1,0) [0|0] "" X
 SG_ SCS_a119_unused119: 54|1@1+ (1,0) [0|0] "" X
 SG_ SCS_a120_unused120: 55|1@1+ (1,0) [0|0] "" X
 SG_ SCS_a121_unused121: 56|1@1+ (1,0) [0|0] "" X
 SG_ SCS_a122_unused122: 57|1@1+ (1,0) [0|0] "" X
 SG_ SCS_a123_unused123: 58|1@1+ (1,0) [0|0] "" X
 SG_ SCS_a124_unused124: 59|1@1+ (1,0) [0|0] "" X
 SG_ SCS_a125_unused125: 60|1@1+ (1,0) [0|0] "" X
 SG_ SCS_a126_unused126: 61|1@1+ (1,0) [0|0] "" X
 SG_ SCS_a127_unused127: 62|1@1+ (1,0) [0|0] "" X
 SG_ SCS_a128_unused128: 63|1@1+ (1,0) [0|0] "" X

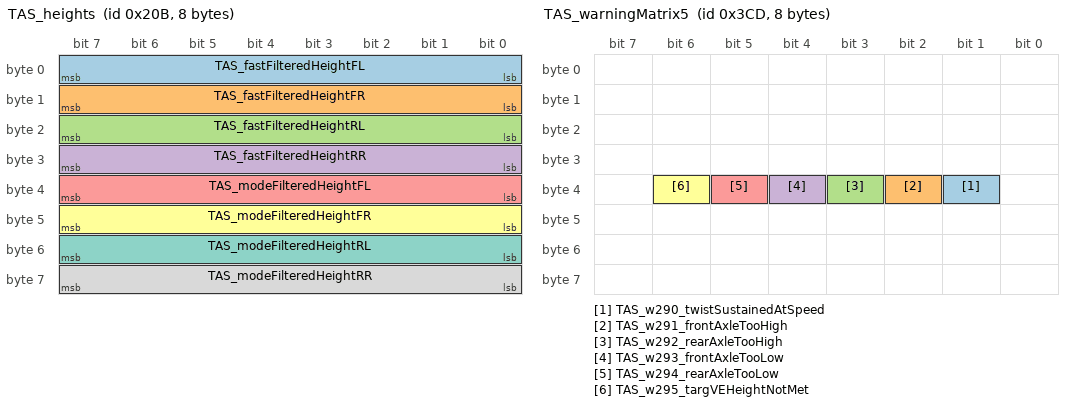
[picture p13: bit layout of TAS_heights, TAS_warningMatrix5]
BO_ 523 TAS_heights: 8 VEH
 SG_ TAS_fastFilteredHeightFL: 0|8@1+ (1,-128) [0|0] "mm" X
 SG_ TAS_fastFilteredHeightFR: 8|8@1+ (1,-128) [0|0] "mm" X
 SG_ TAS_fastFilteredHeightRL: 16|8@1+ (1,-128) [0|0] "mm" X
 SG_ TAS_fastFilteredHeightRR: 24|8@1+ (1,-128) [0|0] "mm" X
 SG_ TAS_modeFilteredHeightFL: 32|8@1+ (1,-128) [0|0] "mm" X
 SG_ TAS_modeFilteredHeightFR: 40|8@1+ (1,-128) [0|0] "mm" X
 SG_ TAS_modeFilteredHeightRL: 48|8@1+ (1,-128) [0|0] "mm" X
 SG_ TAS_modeFilteredHeightRR: 56|8@1+ (1,-128) [0|0] "mm" X

BO_ 1357 TAS_info: 8 VEH
 SG_ TAS_infoIndex M: 0|8@1+ (1,0) [0|0] "" X
 SG_ TAS_infoBuildType m10: 8|3@1+ (1,0) [0|0] "" X
 SG_ TAS_infoBuildConfigId m10: 16|16@1+ (1,0) [0|0] "" X
 SG_ TAS_infoHardwareId m10: 32|1@1+ (1,0) [0|0] "" X
 SG_ TAS_infoComponentId m10: 48|16@1+ (1,0) [0|0] "" X
 SG_ TAS_infoPcbaId m11: 16|8@1+ (1,0) [0|0] "" X
 SG_ TAS_infoAssemblyId m11: 24|8@1+ (1,0) [0|0] "" X
 SG_ TAS_infoUsageId m11: 32|16@1+ (1,0) [0|0] "" X
 SG_ TAS_infoSubUsageId m11: 48|16@1+ (1,0) [0|0] "" X
 SG_ TAS_infoAppCrc m13: 32|32@1+ (1,0) [0|0] "" X
 SG_ TAS_infoBootloaderSvnRevision m14: 8|24@1+ (1,0) [0|0] "" X
 SG_ TAS_infoAppGitHash m17: 10|54@1+ (4,0) [0|0] "" X
 SG_ TAS_infoBootGitHash m18: 10|54@1+ (4,0) [0|0] "" X
 SG_ TAS_infoPlatformType m19: 8|8@1+ (1,0) [0|0] "" X
 SG_ TAS_infoMajorVersion m19: 16|8@1+ (1,0) [0|0] "" X
 SG_ TAS_infoBranchOrigin m19: 24|8@1+ (1,0) [0|0] "" X
 SG_ TAS_infoMaturity m19: 32|8@1+ (1,0) [0|0] "" X
 SG_ TAS_infoHardwareRevision m19: 40|8@1+ (1,0) [0|0] "" X
 SG_ TAS_infoBootUdsProtoVersion m20: 8|8@1+ (1,0) [0|0] "" X
 SG_ TAS_infoBootCrc m20: 32|32@1+ (1,0) [0|0] "" X

BO_ 525 TAS_states: 8 VEH
 SG_ TAS_compressorRun: 30|1@1+ (1,0) [0|0] "" X
 SG_ TAS_currentLevel: 42|3@1+ (1,0) [0|0] "" X
 SG_ TAS_filterMode: 27|3@1+ (1,0) [0|0] "" X
 SG_ TAS_highAllowed: 36|1@1+ (1,0) [0|0] "" X
 SG_ TAS_jackMode: 38|1@1+ (1,0) [0|0] "" X
 SG_ TAS_leanDetected: 32|1@1+ (1,0) [0|0] "" X
 SG_ TAS_levelingState: 0|4@1+ (1,0) [0|0] "" X
 SG_ TAS_levelingType: 4|4@1+ (1,0) [0|0] "" X
 SG_ TAS_limpHomeMode: 48|3@1+ (1,0) [0|0] "" X
 SG_ TAS_lowAllowed: 34|1@1+ (1,0) [0|0] "" X
 SG_ TAS_pressureGallery: 8|8@1+ (0.1,0) [0|0] "bar" X
 SG_ TAS_pressureReservoir: 16|8@1+ (0.1,0) [0|0] "bar" X
 SG_ TAS_redWarningLamp: 40|1@1+ (1,0) [0|0] "" X
 SG_ TAS_runMode: 24|3@1+ (1,0) [0|0] "" X
 SG_ TAS_spinnerUI: 41|1@1+ (1,0) [0|0] "" X
 SG_ TAS_standardAllowed: 35|1@1+ (1,0) [0|0] "" X
 SG_ TAS_statesChecksum: 56|8@1+ (1,0) [0|0] "" X
 SG_ TAS_statesCounter: 52|4@1+ (1,0) [0|0] "" X
 SG_ TAS_targetLevel: 45|3@1+ (1,0) [0|0] "" X
 SG_ TAS_twistDetected: 31|1@1+ (1,0) [0|0] "" X
 SG_ TAS_veryHighAllowed: 37|1@1+ (1,0) [0|0] "" X
 SG_ TAS_veryLowAllowed: 33|1@1+ (1,0) [0|0] "" X
 SG_ TAS_yellowWarningLamp: 39|1@1+ (1,0) [0|0] "" X

BO_ 845 TAS_warningMatrix1: 8 VEH
 SG_ TAS_w001_WatchdogReset: 0|1@1+ (1,0) [0|0] "" X
 SG_ TAS_w002_PowerLossReset: 1|1@1+ (1,0) [0|0] "" X
 SG_ TAS_w003_SWAssertion: 2|1@1+ (1,0) [0|0] "" X
 SG_ TAS_w004_CANMIA: 3|1@1+ (1,0) [0|0] "" X
 SG_ TAS_w005_CANHighError: 4|1@1+ (1,0) [0|0] "" X
 SG_ TAS_w006_CANLowError: 5|1@1+ (1,0) [0|0] "" X
 SG_ TAS_w007_LINTimeout: 6|1@1+ (1,0) [0|0] "" X
 SG_ TAS_w008_LIN2Error: 7|1@1+ (1,0) [0|0] "" X
 SG_ TAS_w009_LIN3Error: 8|1@1+ (1,0) [0|0] "" X
 SG_ TAS_w010_ExtSupplyVoltError: 9|1@1+ (1,0) [0|0] "" X
 SG_ TAS_w011_ECUSupplyVoltError: 10|1@1+ (1,0) [0|0] "" X
 SG_ TAS_w012_CPUReset: 11|1@1+ (1,0) [0|0] "" X
 SG_ TAS_w013_Shared13: 12|1@1+ (1,0) [0|0] "" X
 SG_ TAS_w014_BridgeFault: 13|1@1+ (1,0) [0|0] "" X
 SG_ TAS_w015_NVMMAlert: 14|1@1+ (1,0) [0|0] "" X
 SG_ TAS_w016_MessageTimingError: 15|1@1+ (1,0) [0|0] "" X
 SG_ TAS_w017_AwakeForTooLong: 16|1@1+ (1,0) [0|0] "" X
 SG_ TAS_w018_ADCError: 17|1@1+ (1,0) [0|0] "" X
 SG_ TAS_w019_I2CError: 18|1@1+ (1,0) [0|0] "" X
 SG_ TAS_w020_PWMError: 19|1@1+ (1,0) [0|0] "" X
 SG_ TAS_w021_TaskSchedulerError: 20|1@1+ (1,0) [0|0] "" X
 SG_ TAS_w022_TaskInitError: 21|1@1+ (1,0) [0|0] "" X
 SG_ TAS_w023_SleepError: 22|1@1+ (1,0) [0|0] "" X
 SG_ TAS_w024_WakeError: 23|1@1+ (1,0) [0|0] "" X
 SG_ TAS_w025_CrashEvent: 24|1@1+ (1,0) [0|0] "" X
 SG_ TAS_w026_FlashMemoryError: 25|1@1+ (1,0) [0|0] "" X
 SG_ TAS_w027_NVRAMCorruption: 26|1@1+ (1,0) [0|0] "" X
 SG_ TAS_w028_NVRAMNotResponding: 27|1@1+ (1,0) [0|0] "" X
 SG_ TAS_w029_NVRAMUninitialized: 28|1@1+ (1,0) [0|0] "" X
 SG_ TAS_w030_PWMerrorFL: 29|1@1+ (1,0) [0|0] "" X
 SG_ TAS_w031_PWMerrorFR: 30|1@1+ (1,0) [0|0] "" X
 SG_ TAS_w032_PWMerrorRL: 31|1@1+ (1,0) [0|0] "" X
 SG_ TAS_w033_PWMerrorRR: 32|1@1+ (1,0) [0|0] "" X
 SG_ TAS_w034_PWMshortFL: 33|1@1+ (1,0) [0|0] "" X
 SG_ TAS_w035_PWMshortFR: 34|1@1+ (1,0) [0|0] "" X
 SG_ TAS_w036_PWMshortRL: 35|1@1+ (1,0) [0|0] "" X
 SG_ TAS_w037_PWMshortRR: 36|1@1+ (1,0) [0|0] "" X
 SG_ TAS_w038_PWMopenFL: 37|1@1+ (1,0) [0|0] "" X
 SG_ TAS_w039_PWMopenFR: 38|1@1+ (1,0) [0|0] "" X
 SG_ TAS_w040_PWMopenRL: 39|1@1+ (1,0) [0|0] "" X
 SG_ TAS_w041_PWMopenRR: 40|1@1+ (1,0) [0|0] "" X

BO_ 877 TAS_warningMatrix2: 8 VEH
 SG_ TAS_w070_lowVoltage12V: 5|1@1+ (1,0) [0|0] "" X
 SG_ TAS_w071_highVoltage12V: 6|1@1+ (1,0) [0|0] "" X
 SG_ TAS_w072_shortCircuit5VS0: 7|1@1+ (1,0) [0|0] "" X
 SG_ TAS_w073_lowVoltage5VS0: 8|1@1+ (1,0) [0|0] "" X
 SG_ TAS_w074_shortCircuit5VS1: 9|1@1+ (1,0) [0|0] "" X
 SG_ TAS_w075_lowVoltage5VS1: 10|1@1+ (1,0) [0|0] "" X
 SG_ TAS_w076_highVoltage5VS1: 11|1@1+ (1,0) [0|0] "" X
 SG_ TAS_w077_pressureSigVTooLow: 12|1@1+ (1,0) [0|0] "" X
 SG_ TAS_w078_pressureSigVTooHigh: 13|1@1+ (1,0) [0|0] "" X
 SG_ TAS_w079_DvrSideCfgMismatch: 14|1@1+ (1,0) [0|0] "" X
 SG_ TAS_w080_pressureRefVTooLow: 15|1@1+ (1,0) [0|0] "" X
 SG_ TAS_w093_OTPError: 28|1@1+ (1,0) [0|0] "" X
 SG_ TAS_w098_VCFRONT_MIA: 33|1@1+ (1,0) [0|0] "" X
 SG_ TAS_w099_UI_MIA: 34|1@1+ (1,0) [0|0] "" X
 SG_ TAS_w100_RCM_MIA: 35|1@1+ (1,0) [0|0] "" X
 SG_ TAS_w101_ESP_MIA: 36|1@1+ (1,0) [0|0] "" X
 SG_ TAS_w102_DI_MIA: 37|1@1+ (1,0) [0|0] "" X
 SG_ TAS_w103_GTW_MIA: 38|1@1+ (1,0) [0|0] "" X
 SG_ TAS_w105_ECUDebugMode: 40|1@1+ (1,0) [0|0] "" X
 SG_ TAS_w106_HighCPULoad: 41|1@1+ (1,0) [0|0] "" X
 SG_ TAS_w107_HighStackUsage: 42|1@1+ (1,0) [0|0] "" X
 SG_ TAS_w121_maxDutyFL: 56|1@1+ (1,0) [0|0] "" X
 SG_ TAS_w122_maxDutyFR: 57|1@1+ (1,0) [0|0] "" X
 SG_ TAS_w123_maxDutyRL: 58|1@1+ (1,0) [0|0] "" X
 SG_ TAS_w124_maxDutyRR: 59|1@1+ (1,0) [0|0] "" X
 SG_ TAS_w125_maxDutyReservoir: 60|1@1+ (1,0) [0|0] "" X
 SG_ TAS_w126_maxDutyExhaust: 61|1@1+ (1,0) [0|0] "" X
 SG_ TAS_w127_maxDutyBoost: 62|1@1+ (1,0) [0|0] "" X
 SG_ TAS_w128_maxDutyCompressor: 63|1@1+ (1,0) [0|0] "" X

BO_ 909 APP_VC_infoMessage: 8 Vector__XXX
 SG_ APP_frontCamOcclusionType : 58|3@1+ (1,0) [0|0] "" Vector__XXX
 SG_ APP_narrowOverallVisibility : 55|3@1+ (1,0) [0|0] "" Vector__XXX
 SG_ APP_narrowInPathVisibility : 52|3@1+ (1,0) [0|0] "" Vector__XXX
 SG_ APP_mainOverallVisibility : 49|3@1+ (1,0) [0|0] "" Vector__XXX
 SG_ APP_mainInPathVisibility : 46|3@1+ (1,0) [0|0] "" Vector__XXX
 SG_ APP_fisheyeOverallVisibility : 43|3@1+ (1,0) [0|0] "" Vector__XXX
 SG_ APP_fisheyeInPathVisibility : 40|3@1+ (1,0) [0|0] "" Vector__XXX
 SG_ APP_sceneTagWetRoad : 38|2@1+ (1,0) [0|0] "" Vector__XXX
 SG_ APP_sceneTagTunnel : 36|2@1+ (1,0) [0|0] "" Vector__XXX
 SG_ APP_sceneTagSunGlare : 34|2@1+ (1,0) [0|0] "" Vector__XXX
 SG_ APP_sceneTagSnowyRoad : 32|2@1+ (1,0) [0|0] "" Vector__XXX
 SG_ APP_sceneTagSnowing : 30|2@1+ (1,0) [0|0] "" Vector__XXX
 SG_ APP_sceneTagSevereWeather : 28|2@1+ (1,0) [0|0] "" Vector__XXX
 SG_ APP_sceneTagRaining : 26|2@1+ (1,0) [0|0] "" Vector__XXX
 SG_ APP_sceneTagLensFlare : 24|2@1+ (1,0) [0|0] "" Vector__XXX
 SG_ APP_sceneTagIndoors : 22|2@1+ (1,0) [0|0] "" Vector__XXX
 SG_ APP_sceneTagFullyBlocked : 20|2@1+ (1,0) [0|0] "" Vector__XXX
 SG_ APP_sceneTagFog : 18|2@1+ (1,0) [0|0] "" Vector__XXX
 SG_ APP_sceneTagClearlyRaining : 16|2@1+ (1,0) [0|0] "" Vector__XXX
 SG_ APP_selfieCameraLUX : 8|8@1+ (1,0) [0|0] "" Vector__XXX
 SG_ APP_selfieCameraBlocked : 6|2@1+ (1,0) [0|0] "" Vector__XXX
 SG_ APP_windshieldHeaterOnReason : 2|4@1+ (1,0) [0|0] "" Vector__XXX
 SG_ APP_inTunnel : 0|2@1+ (1,0) [0|0] "" Vector__XXX

BO_ 941 ICR_info: 8 Vector__XXX
 SG_ ICR_infoUsageId m11 : 48|16@1+ (1,0) [0|0] "" Vector__XXX
 SG_ ICR_infoAssemblyId m11 : 40|8@1+ (1,0) [0|0] "" Vector__XXX
 SG_ ICR_infoPcbaId m11 : 32|8@1+ (1,0) [0|0] "" Vector__XXX
 SG_ ICR_infoAppCrc m13 : 8|32@1+ (1,0) [0|0] "" Vector__XXX
 SG_ ICR_infoBoardPartNumber1520 m27 : 8|48@1+ (1,0) [0|0] "" Vector__XXX
 SG_ ICR_infoBoardPartNumber17 m25 : 8|56@1+ (1,0) [0|0] "" Vector__XXX
 SG_ ICR_infoBoardPartNumber814 m26 : 8|56@1+ (1,0) [0|0] "" Vector__XXX
 SG_ ICR_infoBuildType m10 : 8|3@1+ (1,0) [0|0] "" Vector__XXX
 SG_ ICR_infoIndex M : 0|8@1+ (1,0) [0|0] "" Vector__XXX

BO_ 973 TAS_warningMatrix5: 8 VEH
 SG_ TAS_w290_twistSustainedAtSpeed: 33|1@1+ (1,0) [0|0] "" X
 SG_ TAS_w291_frontAxleTooHigh: 34|1@1+ (1,0) [0|0] "" X
 SG_ TAS_w292_rearAxleTooHigh: 35|1@1+ (1,0) [0|0] "" X
 SG_ TAS_w293_frontAxleTooLow: 36|1@1+ (1,0) [0|0] "" X
 SG_ TAS_w294_rearAxleTooLow: 37|1@1+ (1,0) [0|0] "" X
 SG_ TAS_w295_targVEHeightNotMet: 38|1@1+ (1,0) [0|0] "" X

BO_ 879 TPMS_StatusC: 8 CH
 SG_ TPMS_WA_version: 3|1@1+ (1,0) [0|0] "" X
 SG_ TPMS_c_globalHardWarning: 0|1@1+ (1,0) [0|0] "" X
 SG_ TPMS_c_globalSoftWarning: 1|1@1+ (1,0) [0|0] "" X
 SG_ TPMS_deltaPressWarningFL: 20|1@1+ (1,0) [0|0] "" X
 SG_ TPMS_deltaPressWarningFR: 21|1@1+ (1,0) [0|0] "" X
 SG_ TPMS_deltaPressWarningRL: 22|1@1+ (1,0) [0|0] "" X
 SG_ TPMS_deltaPressWarningRR: 23|1@1+ (1,0) [0|0] "" X
 SG_ TPMS_ecuOverVoltage: 41|1@1+ (1,0) [0|0] "" X
 SG_ TPMS_ecuRamRomNvMFail: 42|1@1+ (1,0) [0|0] "" X
 SG_ TPMS_ecuUnderVoltage: 40|1@1+ (1,0) [0|0] "" X
 SG_ TPMS_eolNotCompleted: 47|1@1+ (1,0) [0|0] "" X
 SG_ TPMS_externalTemperatureFail: 46|1@1+ (1,0) [0|0] "" X
 SG_ TPMS_globalDeltaPressure: 4|1@1+ (1,0) [0|0] "" X
 SG_ TPMS_hardWarningFL: 15|1@1+ (1,0) [0|0] "" X
 SG_ TPMS_hardWarningFR: 13|1@1+ (1,0) [0|0] "" X
 SG_ TPMS_hardWarningRL: 11|1@1+ (1,0) [0|0] "" X
 SG_ TPMS_hardWarningRR: 9|1@1+ (1,0) [0|0] "" X
 SG_ TPMS_learningStatus: 16|2@1+ (1,0) [0|0] "" X
 SG_ TPMS_localisationStatus: 18|2@1+ (1,0) [0|0] "" X
 SG_ TPMS_newSensorLearnt: 5|3@1+ (1,0) [0|0] "" X
 SG_ TPMS_rcpFront: 48|8@1+ (0.025,0) [0|0] "bar" X
 SG_ TPMS_rcpRear: 56|8@1+ (0.025,0) [0|0] "bar" X
 SG_ TPMS_rfReceiverFail: 43|1@1+ (1,0) [0|0] "" X
 SG_ TPMS_sensorBatteryLowFL: 32|1@1+ (1,0) [0|0] "" X
 SG_ TPMS_sensorBatteryLowFR: 33|1@1+ (1,0) [0|0] "" X
 SG_ TPMS_sensorBatteryLowRL: 34|1@1+ (1,0) [0|0] "" X
 SG_ TPMS_sensorBatteryLowRR: 35|1@1+ (1,0) [0|0] "" X
 SG_ TPMS_sensorDefectiveFL: 36|1@1+ (1,0) [0|0] "" X
 SG_ TPMS_sensorDefectiveFR: 37|1@1+ (1,0) [0|0] "" X
 SG_ TPMS_sensorDefectiveRL: 38|1@1+ (1,0) [0|0] "" X
 SG_ TPMS_sensorDefectiveRR: 39|1@1+ (1,0) [0|0] "" X
 SG_ TPMS_sensorNoResponseFL: 24|1@1+ (1,0) [0|0] "" X
 SG_ TPMS_sensorNoResponseFR: 25|1@1+ (1,0) [0|0] "" X
 SG_ TPMS_sensorNoResponseRL: 26|1@1+ (1,0) [0|0] "" X
 SG_ TPMS_sensorNoResponseRR: 27|1@1+ (1,0) [0|0] "" X
 SG_ TPMS_sensorThermShutdownFL: 28|1@1+ (1,0) [0|0] "" X
 SG_ TPMS_sensorThermShutdownFR: 29|1@1+ (1,0) [0|0] "" X
 SG_ TPMS_sensorThermShutdownRL: 30|1@1+ (1,0) [0|0] "" X
 SG_ TPMS_sensorThermShutdownRR: 31|1@1+ (1,0) [0|0] "" X
 SG_ TPMS_softWarningFL: 14|1@1+ (1,0) [0|0] "" X
 SG_ TPMS_softWarningFR: 12|1@1+ (1,0) [0|0] "" X
 SG_ TPMS_softWarningRL: 10|1@1+ (1,0) [0|0] "" X
 SG_ TPMS_softWarningRR: 8|1@1+ (1,0) [0|0] "" X
 SG_ TPMS_systemMalfunction: 2|1@1+ (1,0) [0|0] "" X
 SG_ TPMS_vehicleSpeedFail: 45|1@1+ (1,0) [0|0] "" X
 SG_ TPMS_wheelPulseMissing: 44|1@1+ (1,0) [0|0] "" X

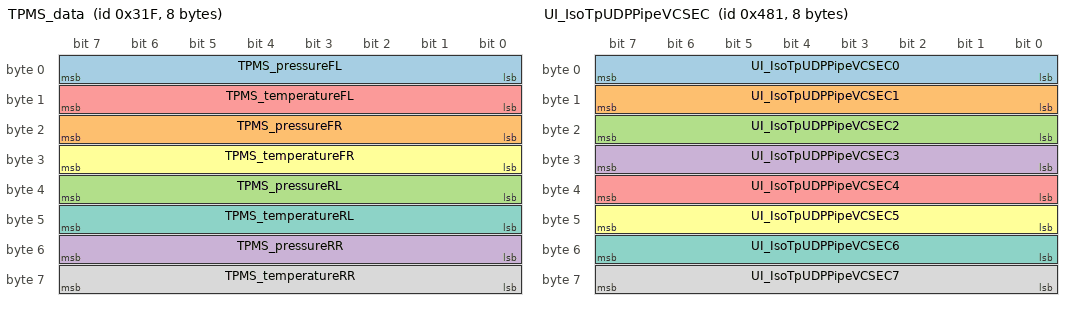
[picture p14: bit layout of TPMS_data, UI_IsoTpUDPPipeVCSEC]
BO_ 799 TPMS_data: 8 CH
 SG_ TPMS_pressureFL: 0|8@1+ (0.025,0) [0|0] "bar" X
 SG_ TPMS_pressureFR: 16|8@1+ (0.025,0) [0|0] "bar" X
 SG_ TPMS_pressureRL: 32|8@1+ (0.025,0) [0|0] "bar" X
 SG_ TPMS_pressureRR: 48|8@1+ (0.025,0) [0|0] "bar" X
 SG_ TPMS_temperatureFL: 8|8@1+ (1,-40) [0|0] "degC" X
 SG_ TPMS_temperatureFR: 24|8@1+ (1,-40) [0|0] "degC" X
 SG_ TPMS_temperatureRL: 40|8@1+ (1,-40) [0|0] "degC" X
 SG_ TPMS_temperatureRR: 56|8@1+ (1,-40) [0|0] "degC" X

BO_ 602 VCSEC_TPMSDisplay: 6 Vector__XXX
 SG_ VCSEC_TPMSDisplayHardWarningIndicationRR : 41|1@1+ (1,0) [0|0] "" Vector__XXX
 SG_ VCSEC_TPMSDisplayHardWarningIndicationRL : 40|1@1+ (1,0) [0|0] "" Vector__XXX
 SG_ VCSEC_TPMSDisplayHardWarningIndicationFR : 39|1@1+ (1,0) [0|0] "" Vector__XXX
 SG_ VCSEC_TPMSDisplayHardWarningIndicationFL : 38|1@1+ (1,0) [0|0] "" Vector__XXX
 SG_ VCSEC_TPMSDisplaySoftWarningIndicationRR : 37|1@1+ (1,0) [0|0] "" Vector__XXX
 SG_ VCSEC_TPMSDisplaySoftWarningIndicationRL : 36|1@1+ (1,0) [0|0] "" Vector__XXX
 SG_ VCSEC_TPMSDisplaySoftWarningIndicationFR : 35|1@1+ (1,0) [0|0] "" Vector__XXX
 SG_ VCSEC_TPMSDisplaySoftWarningIndicationFL : 34|1@1+ (1,0) [0|0] "" Vector__XXX
 SG_ VCSEC_TPMSTellTale : 32|2@1+ (1,0) [0|0] "" Vector__XXX
 SG_ VCSEC_TPMSDisplayPressureRR : 24|8@1+ (0.025,0) [0|0] "" Vector__XXX
 SG_ VCSEC_TPMSDisplayPressureRL : 16|8@1+ (0.025,0) [0|0] "" Vector__XXX
 SG_ VCSEC_TPMSDisplayPressureFR : 8|8@1+ (0.025,0) [0|0] "" Vector__XXX
 SG_ VCSEC_TPMSDisplayPressureFL : 0|8@1+ (0.025,0) [0|0] "" Vector__XXX
SG_ TPMS_btPressureFL : 0|8@1+ (0.025,0) [0|6.375] "bar" X
SG_ TPMS_btPressureFR : 8|8@1+ (0.025,0) [0|6.375] "bar" X
SG_ TPMS_btPressureRL : 16|8@1+ (0.025,0) [0|6.375] "bar" X
SG_ TPMS_btPressureRR : 24|8@1+ (0.025,0) [0|6.375] "bar" X
SG_ TPMSFLunknown : 32|8@1+ (1,0) [0|0] "" X
SG_ TPMSFRunknown : 40|8@1+ (1,0) [0|0] "" X
SG_ TPMSRLunknown : 48|8@1+ (1,0) [0|0] "" X
SG_ TPMSRRunknown : 56|8@1+ (1,0) [0|0] "" X

BO_ 1519 TPMS_info: 8 CH
 SG_ TPMS_infoIndex M: 0|8@1+ (1,0) [0|0] "" X
 SG_ TPMS_infoComponentID m10: 48|16@1+ (1,0) [0|0] "" X
 SG_ TPMS_infoPcbaID m11: 16|8@1+ (1,0) [0|0] "" X
 SG_ TPMS_infoAssemblyID m11: 24|8@1+ (1,0) [0|0] "" X
 SG_ TPMS_infoUsageID m11: 32|16@1+ (1,0) [0|0] "" X
 SG_ TPMS_infoBootUdsProtoVersion m20: 8|8@1+ (1,0) [0|0] "" X
 SG_ TPMS_infoBootloaderCRC m20: 32|32@1+ (1,0) [0|0] "" X
 SG_ TPMS_infoApplicationCRC m13: 32|32@1+ (1,0) [0|0] "" X

BO_ 1153 UI_IsoTpUDPPipeVCSEC: 8 VEH
 SG_ UI_IsoTpUDPPipeVCSEC0: 0|8@1+ (1,0) [0|0] "" X
 SG_ UI_IsoTpUDPPipeVCSEC1: 8|8@1+ (1,0) [0|0] "" X
 SG_ UI_IsoTpUDPPipeVCSEC2: 16|8@1+ (1,0) [0|0] "" X
 SG_ UI_IsoTpUDPPipeVCSEC3: 24|8@1+ (1,0) [0|0] "" X
 SG_ UI_IsoTpUDPPipeVCSEC4: 32|8@1+ (1,0) [0|0] "" X
 SG_ UI_IsoTpUDPPipeVCSEC5: 40|8@1+ (1,0) [0|0] "" X
 SG_ UI_IsoTpUDPPipeVCSEC6: 48|8@1+ (1,0) [0|0] "" X
 SG_ UI_IsoTpUDPPipeVCSEC7: 56|8@1+ (1,0) [0|0] "" X

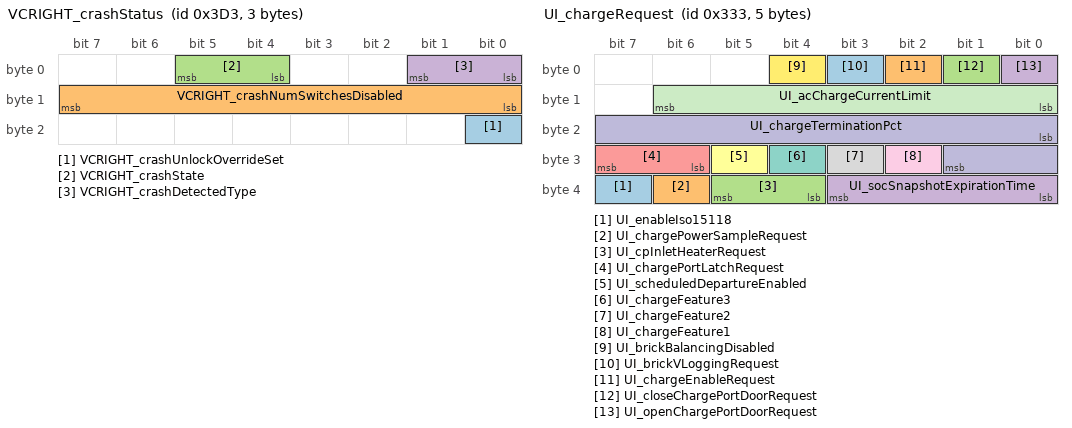
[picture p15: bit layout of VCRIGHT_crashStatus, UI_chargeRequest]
BO_ 979 VCRIGHT_crashStatus: 3 Vector__XXX
 SG_ VCRIGHT_crashUnlockOverrideSet : 16|1@1+ (1,0) [0|0] "" Vector__XXX
 SG_ VCRIGHT_crashNumSwitchesDisabled : 8|8@1+ (1,0) [0|0] "" Vector__XXX
 SG_ VCRIGHT_crashState : 4|2@1+ (1,0) [0|0] "" Vector__XXX
 SG_ VCRIGHT_crashDetectedType : 0|2@1+ (1,0) [0|0] "" Vector__XXX

BO_ 1523 UI_odo: 3 Vector__XXX
 SG_ UI_odometer : 0|24@1+ (0.1,0) [0|0] "" Vector__XXX

BO_ 291 VCRIGHT_doorStatus2: 8 Vector__XXX
 SG_ VCRIGHT_trunkHomeSwitch m0 : 63|1@1+ (1,0) [0|0] "" Vector__XXX
 SG_ VCRIGHT_trunkPawlSwitch m0 : 62|1@1+ (1,0) [0|0] "" Vector__XXX
 SG_ VCRIGHT_trunkRatchetSwitch m0 : 61|1@1+ (1,0) [0|0] "" Vector__XXX
 SG_ VCRIGHT_mirrorTiltYOffset m1 : 56|8@1- (0.02,0) [0|0] "" Vector__XXX
 SG_ VCRIGHT_mirrorTiltXOffset m1 : 48|8@1- (0.02,0) [0|0] "" Vector__XXX
 SG_ VCRIGHT_rearDefrostCurrentFiltered m0 : 48|7@1+ (1,0) [0|0] "" Vector__XXX
 SG_ VCRIGHT_gloveboxOutput m0 : 47|1@1+ (1,0) [0|0] "" Vector__XXX
 SG_ VCRIGHT_BPillarCameraHeaterCurrent m1 : 40|6@1+ (0.02,0) [0|0] "" Vector__XXX
 SG_ VCRIGHT_mirrorFoldCurrent m0 : 40|7@1- (0.05,0) [0|0] "" Vector__XXX
 SG_ VCRIGHT_rearHandle5vEnable m0 : 39|1@1+ (1,0) [0|0] "" Vector__XXX
 SG_ VCRIGHT_frontHandle5vEnable m0 : 38|1@1+ (1,0) [0|0] "" Vector__XXX
 SG_ VCRIGHT_rearHandleDebounceStatus m0 : 35|3@1+ (1,0) [0|0] "" Vector__XXX
 SG_ VCRIGHT_frontHandleDebounceStatus m0 : 32|3@1+ (1,0) [0|0] "" Vector__XXX
 SG_ VCRIGHT_mirrorFoldType m0 : 30|2@1+ (1,0) [0|0] "" Vector__XXX
 SG_ VCRIGHT_rearHandleRawStatus m0 : 27|3@1+ (1,0) [0|0] "" Vector__XXX
 SG_ VCRIGHT_frontHandleRawStatus m0 : 24|3@1+ (1,0) [0|0] "" Vector__XXX
 SG_ VCRIGHT_mirrorDimmed m0 : 23|1@1+ (1,0) [0|0] "" Vector__XXX
 SG_ VCRIGHT_rearDoorState m0 : 20|3@1+ (1,0) [0|0] "" Vector__XXX
 SG_ VCRIGHT_frontDoorState m0 : 17|3@1+ (1,0) [0|0] "" Vector__XXX
 SG_ VCRIGHT_BPillarCameraHeaterState m1 : 16|3@1+ (1,0) [0|0] "" Vector__XXX
 SG_ VCRIGHT_vehicleInMotion m0 : 16|1@1+ (1,0) [0|0] "" Vector__XXX
 SG_ VCRIGHT_frontLatchRelDuty m1 : 8|8@1+ (1,0) [0|0] "" Vector__XXX
 SG_ VCRIGHT_rearLatchRelDuty m0 : 8|8@1+ (1,0) [0|0] "" Vector__XXX
 SG_ VCRIGHT_doorStatus2Index M : 0|1@1+ (1,0) [0|0] "" Vector__XXX

BO_ 1021 UI_autopilotControl: 8 CH
 SG_ UI_autopilotControlIndex M : 0|3@1+ (1,0) [0|7] "" X
 SG_ UI_apmv3Branch m1 : 40|3@1+ (1,0) [0|5] "" X
 SG_ UI_applyEceR79 m1 : 19|1@1+ (1,0) [0|1] "" X
 SG_ UI_blindspotDistance m0 : 15|3@1+ (1,0) [0|5] "" X
 SG_ UI_blindspotMinSpeed m0 : 11|4@1+ (1,0) [0|10] "" X
 SG_ UI_blindspotTTC m0 : 18|3@1+ (1,0) [0|7] "" X
 SG_ UI_disableBackup m1 : 30|1@1+ (1,0) [0|1] "" X
 SG_ UI_disableFisheye m1 : 25|1@1+ (1,0) [0|1] "" X
 SG_ UI_disableLeftPillar m1 : 26|1@1+ (1,0) [0|1] "" X
 SG_ UI_disableLeftRepeater m1 : 28|1@1+ (1,0) [0|1] "" X
 SG_ UI_disableMain m1 : 23|1@1+ (1,0) [0|1] "" X
 SG_ UI_disableNarrow m1 : 24|1@1+ (1,0) [0|1] "" X
 SG_ UI_disableRadar m1 : 31|1@1+ (1,0) [0|1] "" X
 SG_ UI_disableRightPillar m1 : 27|1@1+ (1,0) [0|1] "" X
 SG_ UI_disableRightRepeater m1 : 29|1@1+ (1,0) [0|1] "" X
 SG_ UI_donAlcProgGoreAbortThres m0 : 29|4@1+ (1,0) [0|9] "" X
 SG_ UI_donDisableAutoWiperDuration m0 : 4|3@1+ (1,0) [0|6] "" X
 SG_ UI_donDisableCutin m0 : 24|1@1+ (1,0) [0|1] "" X
 SG_ UI_donDisableOnAutoWiperSpeed m0 : 7|4@1+ (1,0) [0|15] "" X
 SG_ UI_donMinGoreWidthForAbortMap m0 : 25|4@1+ (1,0) [0|11] "" X
 SG_ UI_donMinGoreWidthForAbortNotMap m0 : 33|4@1+ (1,0) [0|11] "" X
 SG_ UI_donStopEndOfRampBuffer m0 : 21|3@1+ (1,0) [0|4] "" X
 SG_ UI_driverMonitorConfirmation m1 : 17|1@1+ (1,0) [0|1] "" X
 SG_ UI_enableAutopilotStopWarning m1 : 44|1@1+ (1,0) [0|1] "" X
 SG_ UI_enableCabinCamera m1 : 43|1@1+ (1,0) [0|1] "" X
 SG_ UI_enableCabinCameraTelemetry m1 : 48|1@1+ (1,0) [0|1] "" X
 SG_ UI_enableMapStops m1 : 20|1@1+ (1,0) [0|1] "" X
 SG_ UI_factorySummonEnable m1 : 39|1@1+ (1,0) [0|1] "" X
 SG_ UI_fsdStopsControlEnabled m0 : 38|1@1+ (1,0) [0|1] "" X
 SG_ UI_fsdVisualizationEnabled m0 : 37|1@1+ (1,0) [0|1] "" X
 SG_ UI_hardCoreSummon m1 : 47|1@1+ (1,0) [0|1] "" X
 SG_ UI_homelinkNearby m0 : 45|1@1+ (1,0) [0|1] "" X
 SG_ UI_hovEnabled m0 : 3|1@1+ (1,0) [0|1] "" X
 SG_ UI_noStalkConfirmAlertChime m1 : 37|1@1+ (1,0) [0|1] "" X
 SG_ UI_noStalkConfirmAlertHaptic m1 : 32|1@1+ (1,0) [0|1] "" X
 SG_ UI_showLaneGraph m1 : 45|1@1+ (1,0) [0|1] "" X
 SG_ UI_showTrackLabels m1 : 46|1@1+ (1,0) [0|1] "" X
 SG_ UI_ulcSnooze m1 : 36|1@1+ (1,0) [0|1] "" X

BO_ 819 UI_chargeRequest: 5 Vector__XXX
 SG_ UI_enableIso15118 : 39|1@1+ (1,0) [0|0] "" Vector__XXX
 SG_ UI_chargePowerSampleRequest : 38|1@1+ (1,0) [0|0] "" Vector__XXX
 SG_ UI_cpInletHeaterRequest : 36|2@1+ (1,0) [0|0] "" Vector__XXX
 SG_ UI_socSnapshotExpirationTime : 32|4@1+ (2,2) [0|0] "" Vector__XXX
 SG_ UI_chargePortLatchRequest : 30|2@1+ (1,0) [0|0] "" Vector__XXX
 SG_ UI_scheduledDepartureEnabled : 29|1@1+ (1,0) [0|0] "" Vector__XXX
 SG_ UI_chargeFeature3 : 28|1@1+ (1,0) [0|0] "" Vector__XXX
 SG_ UI_chargeFeature2 : 27|1@1+ (1,0) [0|0] "" Vector__XXX
 SG_ UI_chargeFeature1 : 26|1@1+ (1,0) [0|0] "" Vector__XXX
 SG_ UI_chargeTerminationPct : 16|10@1+ (0.1,0) [0|0] "" Vector__XXX
 SG_ UI_acChargeCurrentLimit : 8|7@1+ (1,0) [0|0] "" Vector__XXX
 SG_ UI_brickBalancingDisabled : 4|1@1+ (1,0) [0|0] "" Vector__XXX
 SG_ UI_brickVLoggingRequest : 3|1@1+ (1,0) [0|0] "" Vector__XXX
 SG_ UI_chargeEnableRequest : 2|1@1+ (1,0) [0|0] "" Vector__XXX
 SG_ UI_closeChargePortDoorRequest : 1|1@1+ (1,0) [0|0] "" Vector__XXX
 SG_ UI_openChargePortDoorRequest : 0|1@1+ (1,0) [0|0] "" Vector__XXX

BO_ 659 UI_chassisControl: 8 VEH
 SG_ UI_accOvertakeEnable: 18|2@1+ (1,0) [0|0] "" X
 SG_ UI_aebEnable: 20|2@1+ (1,0) [0|0] "" X
 SG_ UI_aesEnable: 22|2@1+ (1,0) [0|0] "" X
 SG_ UI_ahlbEnable: 24|2@1+ (1,0) [0|0] "" X
 SG_ UI_autoLaneChangeEnable: 32|2@1+ (1,0) [0|0] "" X
 SG_ UI_autoParkRequest: 28|4@1+ (1,0) [0|0] "" X
 SG_ UI_bsdEnable: 34|2@1+ (1,0) [0|0] "" X
 SG_ UI_chassisControlChecksum: 56|8@1+ (1,0) [0|0] "" X
 SG_ UI_chassisControlCounter: 52|4@1+ (1,0) [0|0] "" X
 SG_ UI_dasDebugEnable: 17|1@1+ (1,0) [0|0] "" X
 SG_ UI_distanceUnits: 16|1@1+ (1,0) [0|0] "" X
 SG_ UI_fcwEnable: 36|2@1+ (1,0) [0|0] "" X
 SG_ UI_fcwSensitivity: 38|2@1+ (1,0) [0|0] "" X
 SG_ UI_latControlEnable: 40|2@1+ (1,0) [0|0] "" X
 SG_ UI_ldwEnable: 42|2@1+ (1,0) [0|0] "" X
 SG_ UI_narrowGarages: 7|1@1+ (1,0) [0|0] "" X
 SG_ UI_parkBrakeRequest: 5|2@1+ (1,0) [0|0] "" X
 SG_ UI_pedalSafetyEnable: 44|2@1+ (1,0) [0|0] "" X
 SG_ UI_rebootAutopilot: 27|1@1+ (1,0) [0|0] "" X
 SG_ UI_redLightStopSignEnable: 46|2@1+ (1,0) [0|0] "" X
 SG_ UI_selfParkTune: 48|4@1+ (1,0) [0|0] "" X
 SG_ UI_steeringTuneRequest: 0|2@1+ (1,0) [0|0] "" X
 SG_ UI_suspensionLevelRequest: 13|3@1+ (1,0) [0|0] "" X
 SG_ UI_tractionControlMode: 2|3@1+ (1,0) [0|0] "" X
 SG_ UI_trailerMode: 12|1@1+ (1,0) [0|0] "" X
 SG_ UI_winchModeRequest: 8|2@1+ (1,0) [0|0] "" X
 SG_ UI_zeroSpeedConfirmed: 10|2@1+ (1,0) [0|0] "" X

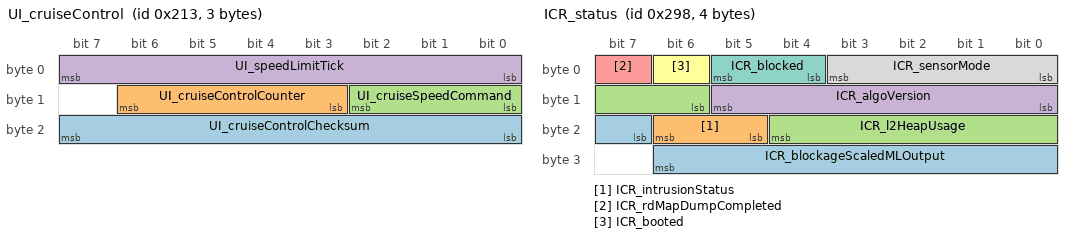
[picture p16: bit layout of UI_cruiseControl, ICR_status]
BO_ 531 UI_cruiseControl: 3 VEH
 SG_ UI_cruiseControlChecksum: 16|8@1+ (1,0) [0|0] "" X
 SG_ UI_cruiseControlCounter: 11|4@1+ (1,0) [0|0] "" X
 SG_ UI_cruiseSpeedCommand: 8|3@1+ (1,0) [0|0] "" X
 SG_ UI_speedLimitTick: 0|8@1+ (1,0) [0|0] "speed" X

BO_ 664 ICR_status: 4 Vector__XXX
 SG_ ICR_blockageScaledMLOutput : 23|8@1+ (0.004,0) [0|0] "" Vector__XXX
 SG_ ICR_intrusionStatus : 21|2@1+ (1,0) [0|0] "" Vector__XXX
 SG_ ICR_l2HeapUsage : 14|7@1+ (1,0) [0|0] "" Vector__XXX
 SG_ ICR_algoVersion : 8|6@1+ (1,0) [0|0] "" Vector__XXX
 SG_ ICR_rdMapDumpCompleted : 7|1@1+ (1,0) [0|0] "" Vector__XXX
 SG_ ICR_booted : 6|1@1+ (1,0) [0|0] "" Vector__XXX
 SG_ ICR_blocked : 4|2@1+ (1,0) [0|0] "" Vector__XXX
 SG_ ICR_sensorMode : 0|4@1+ (1,0) [0|0] "" Vector__XXX

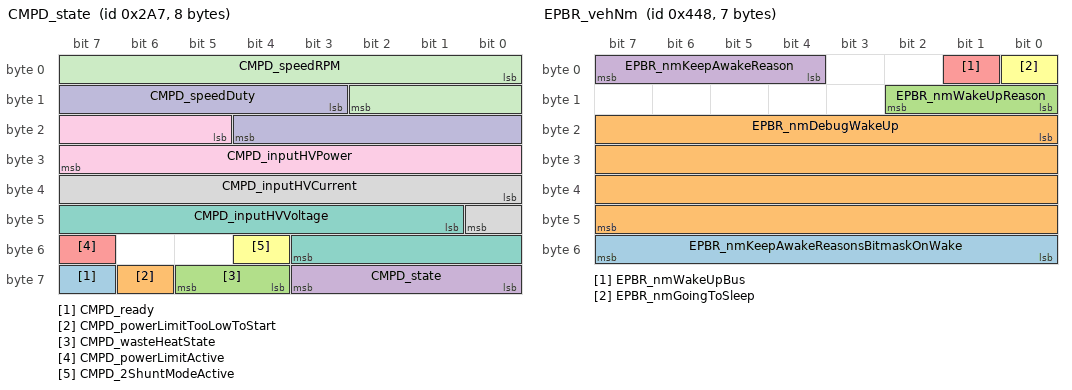
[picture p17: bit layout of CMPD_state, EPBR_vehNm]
BO_ 679 CMPD_state: 8 Vector__XXX
 SG_ CMPD_ready : 63|1@1+ (1,0) [0|0] "" Vector__XXX
 SG_ CMPD_powerLimitTooLowToStart : 62|1@1+ (1,0) [0|0] "" Vector__XXX
 SG_ CMPD_wasteHeatState : 60|2@1+ (1,0) [0|0] "" Vector__XXX
 SG_ CMPD_state : 56|4@1+ (1,0) [0|0] "" Vector__XXX
 SG_ CMPD_powerLimitActive : 55|1@1+ (1,0) [0|0] "" Vector__XXX
 SG_ CMPD_2ShuntModeActive : 52|1@1+ (1,0) [0|0] "" Vector__XXX
 SG_ CMPD_inputHVVoltage : 41|11@1+ (0.5,0) [0|0] "" Vector__XXX
 SG_ CMPD_inputHVCurrent : 32|9@1+ (0.1,0) [0|0] "" Vector__XXX
 SG_ CMPD_inputHVPower : 21|11@1+ (10,0) [0|0] "" Vector__XXX
 SG_ CMPD_speedDuty : 11|10@1+ (0.1,0) [0|0] "" Vector__XXX
 SG_ CMPD_speedRPM : 0|11@1+ (10,0) [0|0] "" Vector__XXX

BO_ 1280 UI_debugECU: 2 VEH
 SG_ UI_debugEcuTarget M: 0|3@1+ (1,0) [0|0] "" X
 SG_ UI_DI_debugEnable m1: 8|1@1+ (1,0) [0|0] "" X
 SG_ UI_DIS_debugEnable m2: 8|1@1+ (1,0) [0|0] "" X
 SG_ UI_PM_debugEnable m3: 8|1@1+ (1,0) [0|0] "" X
 SG_ UI_PM_debugAt100Hz m3: 9|1@1+ (1,0) [0|0] "" X
 SG_ UI_PMS_debugEnable m4: 8|1@1+ (1,0) [0|0] "" X
 SG_ UI_PMS_debugAt100Hz m4: 9|1@1+ (1,0) [0|0] "" X
 SG_ UI_BMS_debugAllEnable m5: 8|1@1+ (1,0) [0|0] "" X
 SG_ UI_BMS_debugDisable m5: 9|1@1+ (1,0) [0|0] "" X
 SG_ UI_VCRIGHT_debugEnable m6: 8|1@1+ (1,0) [0|0] "" X
 SG_ UI_VCFRONT_debugEnable m7: 3|1@1+ (1,0) [0|0] "" X

BO_ 1096 EPBR_vehNm: 7 Vector__XXX
 SG_ EPBR_nmKeepAwakeReasonsBitmaskOnWake : 48|8@1+ (1,0) [0|0] "" Vector__XXX
 SG_ EPBR_nmDebugWakeUp : 16|32@1+ (1,0) [0|0] "" Vector__XXX
 SG_ EPBR_nmWakeUpReason : 8|3@1+ (1,0) [0|0] "" Vector__XXX
 SG_ EPBR_nmKeepAwakeReason : 4|4@1+ (1,0) [0|0] "" Vector__XXX
 SG_ EPBR_nmWakeUpBus : 1|1@1+ (1,0) [0|0] "" Vector__XXX
 SG_ EPBR_nmGoingToSleep : 0|1@1+ (1,0) [0|0] "" Vector__XXX

BO_ 1016 UI_driverAssistControl: 8 CH
 SG_ UI_accFollowDistanceSetting: 45|3@1+ (1,0) [0|0] "" X
 SG_ UI_accFromZero: 55|1@1+ (1,0) [0|0] "" X
 SG_ UI_adaptiveSetSpeedEnable: 39|1@1+ (1,0) [0|0] "" X
 SG_ UI_alcOffHighwayEnable: 56|1@1+ (1,0) [0|0] "" X
 SG_ UI_autoSummonEnable: 10|1@1+ (1,0) [0|0] "" X
 SG_ UI_autopilotAlwaysOn: 54|1@1+ (1,0) [0|0] "" X
 SG_ UI_autopilotControlRequest: 0|1@1+ (1,0) [0|0] "" X
 SG_ UI_curvSpeedAdaptDisable: 4|1@1+ (1,0) [0|0] "" X
 SG_ UI_curvatureDatabaseOnly: 22|1@1+ (1,0) [0|0] "" X
 SG_ UI_dasDeveloper: 5|1@1+ (1,0) [0|0] "" X
 SG_ UI_driveOnMapsEnable: 13|1@1+ (1,0) [0|0] "" X
 SG_ UI_drivingSide: 40|2@1+ (1,0) [0|0] "" X
 SG_ UI_enableClipTelemetry: 42|1@1+ (1,0) [0|0] "" X
 SG_ UI_enableCutinExperiments: 59|1@1+ (1,0) [0|0] "" X
 SG_ UI_enableNavRouteCSA: 58|1@1+ (1,0) [0|0] "" X
 SG_ UI_enableNextGenACC: 19|1@1+ (1,0) [0|0] "" X
 SG_ UI_enableRoadSegmentTelemetry: 44|1@1+ (1,0) [0|0] "" X
 SG_ UI_enableTripTelemetry: 43|1@1+ (1,0) [0|0] "" X
 SG_ UI_enableVinAssociation: 6|1@1+ (1,0) [0|0] "" X
 SG_ UI_enableVisionOnlyStops: 60|1@1+ (1,0) [0|0] "" X
 SG_ UI_exceptionListEnable: 11|1@1+ (1,0) [0|0] "" X
 SG_ UI_followNavRouteEnable: 49|1@1+ (1,0) [0|0] "" X
 SG_ UI_forksEnable: 63|1@1+ (1,0) [0|0] "" X
 SG_ UI_fuseHPPDisable: 17|1@1+ (1,0) [0|0] "" X
 SG_ UI_fuseLanesDisable: 16|1@1+ (1,0) [0|0] "" X
 SG_ UI_fuseVehiclesDisable: 18|1@1+ (1,0) [0|0] "" X
 SG_ UI_handsOnRequirementDisable: 14|1@1+ (1,0) [0|0] "" X
 SG_ UI_lssElkEnabled: 23|1@1+ (1,0) [0|0] "" X
 SG_ UI_lssLdwEnabled: 8|1@1+ (1,0) [0|0] "" X
 SG_ UI_lssLkaEnabled: 7|1@1+ (1,0) [0|0] "" X
 SG_ UI_roadCheckDisable: 12|1@1+ (1,0) [0|0] "" X
 SG_ UI_selfParkRequest: 28|4@1+ (1,0) [0|0] "" X
 SG_ UI_source3D: 61|2@1+ (1,0) [0|0] "" X
 SG_ UI_summonEntryType: 26|2@1+ (1,0) [0|0] "" X
 SG_ UI_summonExitType: 24|2@1+ (1,0) [0|0] "" X
 SG_ UI_summonHeartbeat: 2|2@1+ (1,0) [0|0] "" X
 SG_ UI_summonReverseDist: 32|6@1+ (1,0) [0|0] "" X
 SG_ UI_ulcBlindSpotConfig: 52|2@1+ (1,0) [0|0] "" X
 SG_ UI_ulcOffHighway: 15|1@1+ (1,0) [0|0] "" X
 SG_ UI_ulcSpeedConfig: 50|2@1+ (1,0) [0|0] "" X
 SG_ UI_ulcStalkConfirm: 1|1@1+ (1,0) [0|0] "" X
 SG_ UI_undertakeAssistEnable: 38|1@1+ (1,0) [0|0] "" X
 SG_ UI_validationLoop: 57|1@1+ (1,0) [0|0] "" X
 SG_ UI_visionSpeedType: 20|2@1+ (1,0) [0|0] "" X

BO_ 568 UI_driverAssistMapData: 8 CH
 SG_ UI_acceptBottsDots: 48|1@1+ (1,0) [0|0] "" X
 SG_ UI_autosteerRestricted: 49|1@1+ (1,0) [0|0] "" X
 SG_ UI_controlledAccess: 37|1@1+ (1,0) [0|0] "" X
 SG_ UI_countryCode: 16|10@1+ (1,0) [0|0] "" X
 SG_ UI_gpsRoadMatch: 28|1@1+ (1,0) [0|0] "" X
 SG_ UI_inSuperchargerGeofence: 6|1@1+ (1,0) [0|0] "" X
 SG_ UI_mapDataChecksum: 56|8@1+ (1,0) [0|0] "" X
 SG_ UI_mapDataCounter: 52|4@1+ (1,0) [0|0] "" X
 SG_ UI_mapSpeedLimit: 8|5@1+ (1,0) [0|0] "" X
 SG_ UI_mapSpeedLimitDependency: 0|3@1+ (1,0) [0|0] "" X
 SG_ UI_mapSpeedLimitType: 13|3@1+ (1,0) [0|0] "" X
 SG_ UI_mapSpeedUnits: 7|1@1+ (1,0) [0|0] "" X
 SG_ UI_navRouteActive: 29|1@1+ (1,0) [0|0] "" X
 SG_ UI_nextBranchDist: 32|5@1+ (10,0) [0|0] "m" X
 SG_ UI_nextBranchLeftOffRamp: 38|1@1+ (1,0) [0|0] "" X
 SG_ UI_nextBranchRightOffRamp: 39|1@1+ (1,0) [0|0] "" X
 SG_ UI_parallelAutoparkEnabled: 30|1@1+ (1,0) [0|0] "" X
 SG_ UI_perpendicularAutoparkEnabled: 31|1@1+ (1,0) [0|0] "" X
 SG_ UI_pmmEnabled: 50|1@1+ (1,0) [0|0] "" X
 SG_ UI_rejectAutosteer: 46|1@1+ (1,0) [0|0] "" X
 SG_ UI_rejectHPP: 42|1@1+ (1,0) [0|0] "" X
 SG_ UI_rejectHandsOn: 47|1@1+ (1,0) [0|0] "" X
 SG_ UI_rejectLeftFreeSpace: 44|1@1+ (1,0) [0|0] "" X
 SG_ UI_rejectLeftLane: 40|1@1+ (1,0) [0|0] "" X
 SG_ UI_rejectNav: 43|1@1+ (1,0) [0|0] "" X
 SG_ UI_rejectRightFreeSpace: 45|1@1+ (1,0) [0|0] "" X
 SG_ UI_rejectRightLane: 41|1@1+ (1,0) [0|0] "" X
 SG_ UI_roadClass: 3|3@1+ (1,0) [0|0] "" X
 SG_ UI_scaEnabled: 51|1@1+ (1,0) [0|0] "" X
 SG_ UI_streetCount: 26|2@1+ (1,0) [0|0] "" X

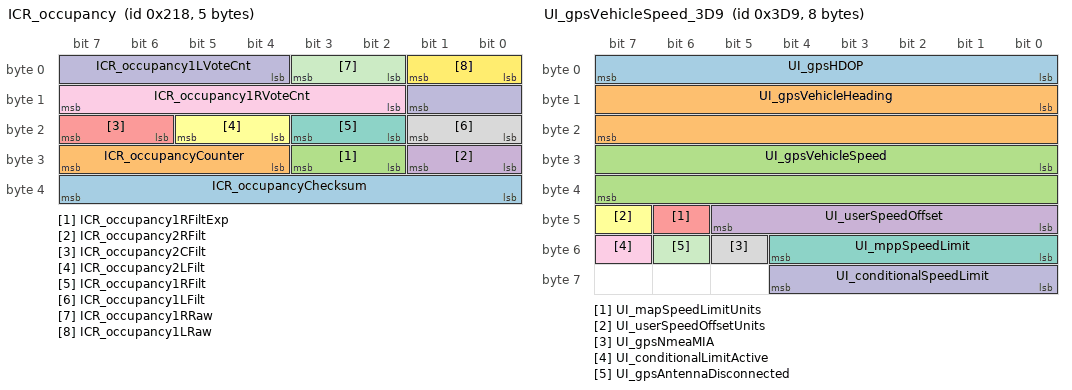
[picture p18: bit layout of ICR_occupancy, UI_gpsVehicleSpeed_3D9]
BO_ 536 ICR_occupancy: 5 Vector__XXX
 SG_ ICR_occupancyChecksum : 32|8@1+ (1,0) [0|0] "" Vector__XXX
 SG_ ICR_occupancyCounter : 28|4@1+ (1,0) [0|0] "" Vector__XXX
 SG_ ICR_occupancy1RFiltExp : 26|2@1+ (1,0) [0|0] "" Vector__XXX
 SG_ ICR_occupancy2RFilt : 24|2@1+ (1,0) [0|0] "" Vector__XXX
 SG_ ICR_occupancy2CFilt : 22|2@1+ (1,0) [0|0] "" Vector__XXX
 SG_ ICR_occupancy2LFilt : 20|2@1+ (1,0) [0|0] "" Vector__XXX
 SG_ ICR_occupancy1RFilt : 18|2@1+ (1,0) [0|0] "" Vector__XXX
 SG_ ICR_occupancy1LFilt : 16|2@1+ (1,0) [0|0] "" Vector__XXX
 SG_ ICR_occupancy1RVoteCnt : 10|6@1- (1,0) [0|0] "" Vector__XXX
 SG_ ICR_occupancy1LVoteCnt : 4|6@1- (1,0) [0|0] "" Vector__XXX
 SG_ ICR_occupancy1RRaw : 2|2@1+ (1,0) [0|0] "" Vector__XXX
 SG_ ICR_occupancy1LRaw : 0|2@1+ (1,0) [0|0] "" Vector__XXX

BO_ 645 UI_driverProfileRecall: 8 VEH
 SG_ UI_driverProfileRecallIndex M: 0|3@1+ (1,0) [0|0] "" X
 SG_ UI_driverProfileRecallStop: 3|1@1+ (1,0) [0|0] "" X
 SG_ UI_frontSeatRecallActive m1: 4|1@1+ (1,0) [0|0] "" X
 SG_ UI_frontSeatTrackPos m1: 5|10@1- (4,0) [0|0] "mm" X
 SG_ UI_frontSeatBackPos m1: 16|12@1- (0.1,0) [0|0] "deg" X
 SG_ UI_frontSeatLiftPos m1: 32|10@1- (4,0) [0|0] "mm" X
 SG_ UI_frontSeatTiltPos m1: 48|12@1- (0.1,0) [0|0] "deg" X
 SG_ UI_columnAndLumbarRecallActive m2: 4|1@1+ (1,0) [0|0] "" X
 SG_ UI_steeringColumnUpDownPos m2: 8|8@1- (12,1284) [0|0] "ticks" X
 SG_ UI_lumbarAPressureHpa m2: 16|16@1+ (1,0) [0|0] "" X
 SG_ UI_lumbarBPressureHpa m2: 32|16@1+ (1,0) [0|0] "" X
 SG_ UI_steeringColumnInOutPos m2: 48|8@1- (12,1284) [0|0] "ticks" X
 SG_ UI_mirrorRecallActive m3: 4|1@1+ (1,0) [0|0] "" X
 SG_ UI_leftMirrorTiltXPosition m3: 8|8@1+ (0.02,0) [0|0] "V" X
 SG_ UI_leftMirrorTiltYPosition m3: 16|8@1+ (0.02,0) [0|0] "V" X
 SG_ UI_rightMirrorTiltXPosition m3: 24|8@1+ (0.02,0) [0|0] "V" X
 SG_ UI_rightMirrorTiltYPosition m3: 32|8@1+ (0.02,0) [0|0] "V" X
 SG_ UI_leftMirrorDipXPosition m4: 8|8@1+ (0.02,0) [0|0] "V" X
 SG_ UI_leftMirrorDipYPosition m4: 16|8@1+ (0.02,0) [0|0] "V" X
 SG_ UI_rightMirrorDipXPosition m4: 24|8@1+ (0.02,0) [0|0] "V" X
 SG_ UI_rightMirrorDipYPosition m4: 32|8@1+ (0.02,0) [0|0] "V" X
 SG_ UI_leftBackrestSwitchUp m5: 4|2@1+ (1,0) [0|0] "" X
 SG_ UI_leftBackrestSwitchDown m5: 6|2@1+ (1,0) [0|0] "" X
 SG_ UI_leftLiftSwitchUp m5: 8|2@1+ (1,0) [0|0] "" X
 SG_ UI_leftLiftSwitchDown m5: 10|2@1+ (1,0) [0|0] "" X
 SG_ UI_rightBackrestSwitchUp m5: 12|2@1+ (1,0) [0|0] "" X
 SG_ UI_rightBackrestSwitchDown m5: 14|2@1+ (1,0) [0|0] "" X
 SG_ UI_rightLiftSwitchUp m5: 16|2@1+ (1,0) [0|0] "" X
 SG_ UI_rightLiftSwitchDown m5: 18|2@1+ (1,0) [0|0] "" X

BO_ 984 UI_elevationStatus: 4 Vector__XXX
 SG_ UI_navElevation : 16|14@1- (1,0) [0|0] "" Vector__XXX
 SG_ UI_elevation : 0|14@1- (1,0) [0|0] "" Vector__XXX

BO_ 1139 UI_ethNm: 8 Vector__XXX
 SG_ UI_wakeupTime : 32|32@1+ (1,0) [0|0] "" Vector__XXX
 SG_ UI_nmKeepAwakeReason : 16|6@1+ (1,0) [0|0] "" Vector__XXX
 SG_ UI_nmGoingToSleep : 0|1@1+ (1,0) [0|0] "" Vector__XXX

BO_ 985 UI_gpsVehicleSpeed_3D9: 8 CH
 SG_ UI_gpsHDOP: 0|8@1+ (0.1,0) [0|0] "1" X
 SG_ UI_gpsVehicleHeading: 8|16@1+ (0.0078125,0) [0|0] "deg" X
 SG_ UI_gpsVehicleSpeed: 24|16@1+ (0.00390625,0) [0|0] "km/hr" X
 SG_ UI_userSpeedOffset: 40|6@1+ (1,-30) [0|0] "kph/mph" X
 SG_ UI_mapSpeedLimitUnits: 46|1@1+ (1,0) [0|0] "" X
 SG_ UI_userSpeedOffsetUnits: 47|1@1+ (1,0) [0|0] "" X
 SG_ UI_mppSpeedLimit: 48|5@1+ (5,0) [0|0] "kph/mph" X
 SG_ UI_gpsNmeaMIA: 53|1@1+ (1,0) [0|0] "" X
 SG_ UI_conditionalLimitActive : 55|1@1+ (1,0) [0|1] "" X
 SG_ UI_conditionalSpeedLimit : 56|5@1+ (5,0) [0|155] "kph/mph" X
 SG_ UI_gpsAntennaDisconnected : 54|1@1+ (1,0) [0|1] "" X

BO_ 755 UI_hvacRequest: 8 Vector__XXX
 SG_ UI_enableHvacLimpMode : 63|1@1+ (1,0) [0|0] "" Vector__XXX
 SG_ UI_enableHvacAPFoggingMonitor : 62|1@1+ (1,0) [0|0] "" Vector__XXX
 SG_ UI_enableHvacControlsFeatures2 : 61|1@1+ (1,0) [0|0] "" Vector__XXX
 SG_ UI_hvacClimateNudgeStatus : 58|3@1+ (1,0) [0|0] "" Vector__XXX
 SG_ UI_hvacReqTempSetpointCOP : 56|2@1+ (1,0) [0|0] "" Vector__XXX
 SG_ UI_enableHvacWeatherDataBasedHum : 55|1@1+ (1,0) [0|0] "" Vector__XXX
 SG_ UI_evapDryingSelectiveEnable : 54|1@1+ (1,0) [0|0] "" Vector__XXX
 SG_ UI_enableCustomerTHSAlerts : 53|1@1+ (1,0) [0|0] "" Vector__XXX
 SG_ UI_enableHvacVOCPurgeRoutine : 47|1@1+ (1,0) [0|0] "" Vector__XXX
 SG_ UI_hvacPhoneCallAirFlowAdjustEna : 46|1@1+ (1,0) [0|0] "" Vector__XXX
 SG_ UI_enableHvacNotifications : 45|1@1+ (1,0) [0|0] "" Vector__XXX
 SG_ UI_enableHvacControlsFeatures1 : 44|1@1+ (1,0) [0|0] "" Vector__XXX
 SG_ UI_hvacLatchPassengerPresent : 39|1@1+ (1,0) [0|0] "" Vector__XXX
 SG_ UI_hvacReqBioWeaponDefMode : 35|1@1+ (1,0) [0|0] "" Vector__XXX
 SG_ UI_hvacReqKeepClimateOn : 33|2@1+ (1,0) [0|0] "" Vector__XXX
 SG_ UI_hvacUseModeledDuctTemp : 32|1@1+ (1,0) [0|0] "" Vector__XXX
 SG_ UI_hvacReqSecondRowState : 29|3@1+ (1,0) [0|0] "" Vector__XXX
 SG_ UI_hvacReqUserPowerState : 26|3@1+ (1,0) [0|0] "" Vector__XXX
 SG_ UI_hvacDefogState : 24|2@1+ (1,0) [0|0] "" Vector__XXX
 SG_ UI_hvacReqACDisable : 22|2@1+ (1,0) [0|0] "" Vector__XXX
 SG_ UI_hvacReqRecirc : 20|2@1+ (1,0) [0|0] "" Vector__XXX
 SG_ UI_hvacReqBlowerSegment : 16|4@1+ (1,0) [0|0] "" Vector__XXX
 SG_ UI_hvacReqAirDistributionMode : 13|3@1+ (1,0) [0|0] "" Vector__XXX
 SG_ UI_hvacReqTempSetpointRight : 8|5@1+ (0.5,15) [0|0] "" Vector__XXX
 SG_ UI_hvacReqAutoBlowerLevel : 5|3@1+ (1,0) [0|0] "" Vector__XXX
 SG_ UI_hvacReqTempSetpointLeft : 0|5@1+ (0.5,15) [0|0] "" Vector__XXX

BO_ 79 UI_locationStatus: 8 CH
 SG_ UI_gpsAccuracy: 57|7@1+ (0.2,0) [0|0] "m" X
 SG_ UI_latitude: 0|28@1- (1e-06,0) [0|0] "deg" X
 SG_ UI_longitude: 28|29@1- (1e-06,0) [0|0] "deg" X

BO_ 1011 UI_odo_3F3: 3 CH
 SG_ UI_odometer: 0|24@1+ (0.1,0) [0|0] "km" X

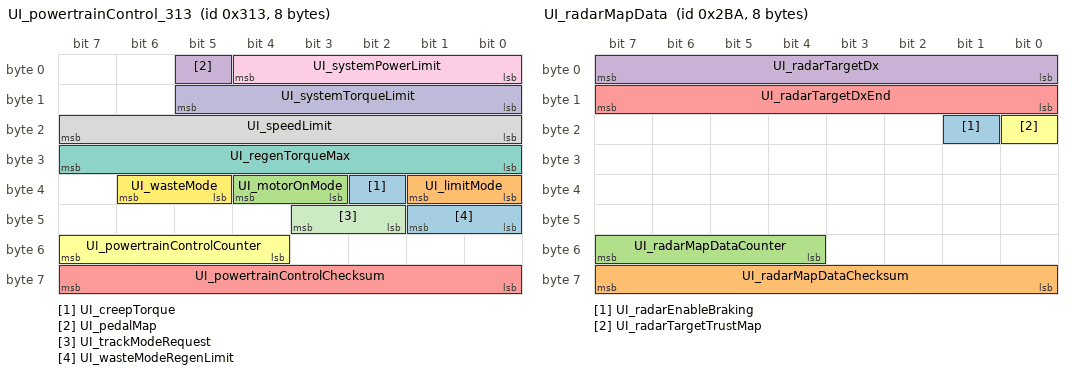
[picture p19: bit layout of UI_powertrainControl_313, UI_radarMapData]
BO_ 787 UI_powertrainControl_313: 8 VEH
 SG_ UI_creepTorque: 34|1@1+ (1,0) [0|0] "" X
 SG_ UI_limitMode: 32|2@1+ (1,0) [0|0] "" X
 SG_ UI_motorOnMode: 35|2@1+ (1,0) [0|0] "" X
 SG_ UI_pedalMap: 5|1@1+ (1,0) [0|0] "" X
 SG_ UI_powertrainControlChecksum: 56|8@1+ (1,0) [0|0] "" X
 SG_ UI_powertrainControlCounter: 52|4@1+ (1,0) [0|0] "" X
 SG_ UI_regenTorqueMax: 24|8@1+ (0.5,0) [0|0] "%" X
 SG_ UI_speedLimit: 16|8@1+ (1,50) [0|0] "kph" X
 SG_ UI_systemPowerLimit: 0|5@1+ (20,20) [0|0] "kW" X
 SG_ UI_systemTorqueLimit: 8|6@1+ (100,4000) [0|0] "Nm" X
 SG_ UI_trackModeRequest: 42|2@1+ (1,0) [0|0] "" X
 SG_ UI_wasteMode: 37|2@1+ (1,0) [0|0] "" X
 SG_ UI_wasteModeRegenLimit: 40|2@1+ (1,0) [0|0] "" X

BO_ 499 UI_presentPhoneKey1Info: 8 VEH
 SG_ UI_presentPhoneKey1SHA1: 10|54@1+ (1024,0) [0|0] "" X

BO_ 435 UI_presentPhoneKey2Info: 8 VEH
 SG_ UI_presentPhoneKey2SHA1: 10|54@1+ (1024,0) [0|0] "" X

BO_ 371 UI_presentPhoneKey3Info: 8 VEH
 SG_ UI_presentPhoneKey3SHA1: 10|54@1+ (1024,0) [0|0] "" X

BO_ 307 UI_presentPhoneKeysOSInfo: 1 VEH
 SG_ UI_presentPhoneKey1RunsiOS: 0|1@1+ (1,0) [0|0] "" X
 SG_ UI_presentPhoneKey2RunsiOS: 1|1@1+ (1,0) [0|0] "" X
 SG_ UI_presentPhoneKey3RunsiOS: 2|1@1+ (1,0) [0|0] "" X

BO_ 698 UI_radarMapData: 8 VEH
 SG_ UI_radarEnableBraking: 17|1@1+ (1,0) [0|0] "" X
 SG_ UI_radarMapDataChecksum: 56|8@1+ (1,0) [0|0] "" X
 SG_ UI_radarMapDataCounter: 52|4@1+ (1,0) [0|0] "" X
 SG_ UI_radarTargetDx: 0|8@1+ (1,-95) [0|0] "m" X
 SG_ UI_radarTargetDxEnd: 8|8@1+ (1,0) [0|0] "m" X
 SG_ UI_radarTargetTrustMap: 16|1@1+ (1,0) [0|0] "" X

BA_DEF_ BO_ "GenMsgSendType" ENUM "Cyclic";
BA_DEF_ BO_ "GenMsgCycleTime" INT 0 10000;

BA_ "GenMsgSendType" BO_ 273 0;
BA_ "GenMsgCycleTime" BO_ 273 1000;

BA_ "GenMsgSendType" BO_ 861 0;
BA_ "GenMsgCycleTime" BO_ 861 1000;

BA_ "GenMsgSendType" BO_ 813 0;
BA_ "GenMsgCycleTime" BO_ 813 10000;

BA_ "GenMsgSendType" BO_ 925 0;
BA_ "GenMsgCycleTime" BO_ 925 40;

BA_ "GenMsgSendType" BO_ 771 0;
BA_ "GenMsgCycleTime" BO_ 771 500;

BA_ "GenMsgSendType" BO_ 806 0;
BA_ "GenMsgCycleTime" BO_ 806 1000;

BA_ "GenMsgSendType" BO_ 846 0;
BA_ "GenMsgCycleTime" BO_ 846 100;

BA_ "GenMsgSendType" BO_ 862 0;
BA_ "GenMsgCycleTime" BO_ 862 100;

BA_ "GenMsgSendType" BO_ 926 0;
BA_ "GenMsgCycleTime" BO_ 926 100;

BA_ "GenMsgSendType" BO_ 606 0;
BA_ "GenMsgCycleTime" BO_ 606 100;

BA_ "GenMsgSendType" BO_ 542 0;
BA_ "GenMsgCycleTime" BO_ 542 40;

BA_ "GenMsgSendType" BO_ 590 0;
BA_ "GenMsgCycleTime" BO_ 590 100;

BA_ "GenMsgSendType" BO_ 526 0;
BA_ "GenMsgCycleTime" BO_ 526 40;

BA_ "GenMsgSendType" BO_ 558 0;
BA_ "GenMsgCycleTime" BO_ 558 40;

BA_ "GenMsgSendType" BO_ 814 0;
BA_ "GenMsgCycleTime" BO_ 814 100;

BA_ "GenMsgSendType" BO_ 830 0;
BA_ "GenMsgCycleTime" BO_ 830 100;

BA_ "GenMsgSendType" BO_ 799 0;
BA_ "GenMsgCycleTime" BO_ 799 500;

BA_ "GenMsgSendType" BO_ 782 0;
BA_ "GenMsgCycleTime" BO_ 782 250;

BA_ "GenMsgSendType" BO_ 894 0;
BA_ "GenMsgCycleTime" BO_ 894 1000;

BA_ "GenMsgSendType" BO_ 932 0;
BA_ "GenMsgCycleTime" BO_ 932 1000;

BA_ "GenMsgSendType" BO_ 612 0;
BA_ "GenMsgCycleTime" BO_ 612 100;

BA_ "GenMsgSendType" BO_ 516 0;
BA_ "GenMsgCycleTime" BO_ 516 100;

BA_ "GenMsgSendType" BO_ 548 0;
BA_ "GenMsgCycleTime" BO_ 548 100;

BA_ "GenMsgSendType" BO_ 964 0;
BA_ "GenMsgCycleTime" BO_ 964 1000;

BA_ "GenMsgSendType" BO_ 708 0;
BA_ "GenMsgCycleTime" BO_ 708 1000;

BA_ "GenMsgSendType" BO_ 676 0;
BA_ "GenMsgCycleTime" BO_ 676 1000;

BA_ "GenMsgSendType" BO_ 900 0;
BA_ "GenMsgCycleTime" BO_ 900 1000;

BA_ "GenMsgSendType" BO_ 1748 0;
BA_ "GenMsgCycleTime" BO_ 1748 1000;

BA_ "GenMsgSendType" BO_ 772 0;
BA_ "GenMsgCycleTime" BO_ 772 1000;

BA_ "GenMsgSendType" BO_ 790 0;
BA_ "GenMsgCycleTime" BO_ 790 1000;

BA_ "GenMsgSendType" BO_ 837 0;
BA_ "GenMsgCycleTime" BO_ 837 1000;

BA_ "GenMsgSendType" BO_ 647 0;
BA_ "GenMsgCycleTime" BO_ 647 100;

BA_ "GenMsgSendType" BO_ 1282 0;
BA_ "GenMsgCycleTime" BO_ 1282 1000;

BA_ "GenMsgSendType" BO_ 1329 0;
BA_ "GenMsgCycleTime" BO_ 1329 1000;

BA_ "GenMsgSendType" BO_ 881 0;
BA_ "GenMsgCycleTime" BO_ 881 1000;

BA_ "GenMsgSendType" BO_ 17 0;
BA_ "GenMsgCycleTime" BO_ 17 10;

BA_ "GenMsgSendType" BO_ 257 0;
BA_ "GenMsgCycleTime" BO_ 257 20;

BA_ "GenMsgSendType" BO_ 849 0;
BA_ "GenMsgCycleTime" BO_ 849 10000;

BA_ "GenMsgSendType" BO_ 289 0;
BA_ "GenMsgCycleTime" BO_ 289 10;

BA_ "GenMsgSendType" BO_ 529 0;
BA_ "GenMsgCycleTime" BO_ 529 100;

BA_ "GenMsgSendType" BO_ 1359 0;
BA_ "GenMsgCycleTime" BO_ 1359 100;

BA_ "GenMsgSendType" BO_ 816 0;
BA_ "GenMsgCycleTime" BO_ 816 1000;

BA_ "GenMsgSendType" BO_ 585 0;
BA_ "GenMsgCycleTime" BO_ 585 100;

BA_ "GenMsgSendType" BO_ 297 0;
BA_ "GenMsgCycleTime" BO_ 297 10;

BA_ "GenMsgSendType" BO_ 815 0;
BA_ "GenMsgCycleTime" BO_ 815 1000;

BA_ "GenMsgSendType" BO_ 1355 0;
BA_ "GenMsgCycleTime" BO_ 1355 1000;

BA_ "GenMsgSendType" BO_ 869 0;
BA_ "GenMsgCycleTime" BO_ 869 1000;

BA_ "GenMsgSendType" BO_ 880 0;
BA_ "GenMsgCycleTime" BO_ 880 1000;

BA_ "GenMsgSendType" BO_ 523 0;
BA_ "GenMsgCycleTime" BO_ 523 10;

BA_ "GenMsgSendType" BO_ 1357 0;
BA_ "GenMsgCycleTime" BO_ 1357 1000;

BA_ "GenMsgSendType" BO_ 525 0;
BA_ "GenMsgCycleTime" BO_ 525 10;

BA_ "GenMsgSendType" BO_ 845 0;
BA_ "GenMsgCycleTime" BO_ 845 1000;

BA_ "GenMsgSendType" BO_ 877 0;
BA_ "GenMsgCycleTime" BO_ 877 1000;

BA_ "GenMsgSendType" BO_ 909 0;
BA_ "GenMsgCycleTime" BO_ 909 1000;

BA_ "GenMsgSendType" BO_ 941 0;
BA_ "GenMsgCycleTime" BO_ 941 1000;

BA_ "GenMsgSendType" BO_ 973 0;
BA_ "GenMsgCycleTime" BO_ 973 1000;

BA_ "GenMsgSendType" BO_ 979 0;
BA_ "GenMsgCycleTime" BO_ 979 500;

BA_ "GenMsgSendType" BO_ 291 0;
BA_ "GenMsgCycleTime" BO_ 291 1000;

BA_ "GenMsgSendType" BO_ 819 0;
BA_ "GenMsgCycleTime" BO_ 819 500;

BA_ "GenMsgSendType" BO_ 659 0;
BA_ "GenMsgCycleTime" BO_ 659 500;

BA_ "GenMsgSendType" BO_ 531 0;
BA_ "GenMsgCycleTime" BO_ 531 500;

BA_ "GenMsgSendType" BO_ 664 0;
BA_ "GenMsgCycleTime" BO_ 664 500;

BA_ "GenMsgSendType" BO_ 679 0;
BA_ "GenMsgCycleTime" BO_ 679 500;

BA_ "GenMsgSendType" BO_ 1280 0;
BA_ "GenMsgCycleTime" BO_ 1280 5000;

BA_ "GenMsgSendType" BO_ 1096 0;
BA_ "GenMsgCycleTime" BO_ 1096 1000;

BA_ "GenMsgSendType" BO_ 1016 0;
BA_ "GenMsgCycleTime" BO_ 1016 1000;

BA_ "GenMsgSendType" BO_ 568 0;
BA_ "GenMsgCycleTime" BO_ 568 500;

BA_ "GenMsgSendType" BO_ 536 0;
BA_ "GenMsgCycleTime" BO_ 536 500;

BA_ "GenMsgSendType" BO_ 645 0;
BA_ "GenMsgCycleTime" BO_ 645 500;

BA_ "GenMsgSendType" BO_ 984 0;
BA_ "GenMsgCycleTime" BO_ 984 1000;

BA_ "GenMsgSendType" BO_ 1139 0;
BA_ "GenMsgCycleTime" BO_ 1139 500;

BA_ "GenMsgSendType" BO_ 985 0;
BA_ "GenMsgCycleTime" BO_ 985 1000;

BA_ "GenMsgSendType" BO_ 755 0;
BA_ "GenMsgCycleTime" BO_ 755 500;

BA_ "GenMsgSendType" BO_ 79 0;
BA_ "GenMsgCycleTime" BO_ 79 1000;

BA_ "GenMsgSendType" BO_ 1011 0;
BA_ "GenMsgCycleTime" BO_ 1011 1000;

BA_ "GenMsgSendType" BO_ 787 0;
BA_ "GenMsgCycleTime" BO_ 787 500;

BA_ "GenMsgSendType" BO_ 499 0;
BA_ "GenMsgCycleTime" BO_ 499 1000;

BA_ "GenMsgSendType" BO_ 435 0;
BA_ "GenMsgCycleTime" BO_ 435 1000;

BA_ "GenMsgSendType" BO_ 371 0;
BA_ "GenMsgCycleTime" BO_ 371 1000;

BA_ "GenMsgSendType" BO_ 307 0;
BA_ "GenMsgCycleTime" BO_ 307 1000;

BA_ "GenMsgSendType" BO_ 698 0;
BA_ "GenMsgCycleTime" BO_ 698 500;

VAL_ 861 IBST_matrixIndex 0 "AlertMatrix0" 1 "AlertMatrix1" 2 "AlertMatrix2";

VAL_ 813 IBST_infoIndex 0 "DEPRECATED_0" 1 "DEPRECATED_1" 2 "DEPRECATED_2" 3 "DEPRECATED_3" 4 "DEPRECATED_4" 5 "DEPRECATED_5" 6 "DEPRECATED_6" 7 "DEPRECATED_7" 8 "DEPRECATED_8" 9 "DEPRECATED_9" 10 "BUILD_HWID_COMPONENTID" 11 "PCBAID_ASSYID_USAGEID" 13 "APP_CRC" 14 "BOOTLOADER_SVN" 15 "BOOTLOADER_CRC" 16 "SUBCOMPONENT" 17 "APP_GITHASH" 18 "BOOTLOADER_GITHASH" 19 "VERSION_DEPRECATED" 20 "UDS_PROTOCOL_BOOTCRC" 22 "VARIANTCRC" 25 "PACKAGE_PN_1_7" 26 "PACKAGE_PN_8_14" 27 "PACKAGE_PN_15_20" 29 "PACKAGE_SN_1_7" 30 "PACKAGE_SN_8_14" 31 "SUBCOMPONENT_GITHASH" 255 "END";
VAL_ 813 IBST_infoBuildType 0 "UNKNOWN_BUILD" 1 "PLATFORM_BUILD" 2 "LOCAL_BUILD" 3 "TRACEABLE_CI_BUILD" 4 "MFG_BUILD";

VAL_ 806 PARK_infoIndex 0 "DEPRECATED_0" 1 "DEPRECATED_1" 2 "DEPRECATED_2" 3 "DEPRECATED_3" 4 "DEPRECATED_4" 5 "DEPRECATED_5" 6 "DEPRECATED_6" 7 "DEPRECATED_7" 8 "DEPRECATED_8" 9 "DEPRECATED_9" 10 "BUILD_HWID_COMPONENTID" 11 "PCBAID_ASSYID_USAGEID" 13 "APP_CRC" 14 "BOOTLOADER_SVN" 15 "BOOTLOADER_CRC" 16 "SUBCOMPONENT" 17 "APP_GITHASH" 18 "BOOTLOADER_GITHASH" 19 "VERSION_DEPRECATED" 20 "UDS_PROTOCOL_BOOTCRC" 22 "VARIANTCRC" 25 "PACKAGE_PN_1_7" 26 "PACKAGE_PN_8_14" 27 "PACKAGE_PN_15_20" 29 "PACKAGE_SN_1_7" 30 "PACKAGE_SN_8_14" 31 "SUBCOMPONENT_GITHASH" 255 "END";
VAL_ 806 PARK_infoBuildType 0 "UNKNOWN_BUILD" 1 "PLATFORM_BUILD" 2 "LOCAL_BUILD" 3 "TRACEABLE_CI_BUILD" 4 "MFG_BUILD";

VAL_ 846 PARK_frontLeftMiddleRawDistData 255 "SNA";
VAL_ 846 PARK_frontMiddleRawDistData 255 "SNA";
VAL_ 846 PARK_frontRightMiddleRawDistData 255 "SNA";

VAL_ 862 PARK_rearLeftMiddleRawDistData 255 "SNA";
VAL_ 862 PARK_rearMiddleRawDistData 255 "SNA";
VAL_ 862 PARK_rearRightMiddleRawDistData 255 "SNA";

VAL_ 926 PARK_leftSideFrontRawDistData 255 "SNA";
VAL_ 926 PARK_leftSideRearRawDistData 255 "SNA";
VAL_ 926 PARK_rightSideFrontRawDistData 255 "SNA";
VAL_ 926 PARK_rightSideRearRawDistData 255 "SNA";

VAL_ 606 PARK_pscEnvSlotType 0 "LEFT_PARALLEL" 1 "LEFT_CROSS" 2 "RIGHT_PARALLEL" 3 "RIGHT_CROSS";
VAL_ 606 PARK_pscLeftParallelObj1X 2046 "NO_SPACE" 2047 "SNA";
VAL_ 606 PARK_pscLeftParallelObj1Y 2046 "NO_SPACE" 2047 "SNA";
VAL_ 606 PARK_pscLeftParallelObj1Alpha 126 "NO_SPACE" 127 "SNA";
VAL_ 606 PARK_pscLeftParallelObj2Y 2046 "NO_SPACE" 2047 "SNA";
VAL_ 606 PARK_pscLeftParallelObj2X 2046 "NO_SPACE" 2047 "SNA";
VAL_ 606 PARK_pscLeftParallelObj2Alpha 126 "NO_SPACE" 127 "SNA";
VAL_ 606 PARK_pscLeftCrossObj1X 2046 "NO_SPACE" 2047 "SNA";
VAL_ 606 PARK_pscLeftCrossObj1Y 2046 "NO_SPACE" 2047 "SNA";
VAL_ 606 PARK_pscLeftCrossObj1Alpha 126 "NO_SPACE" 127 "SNA";
VAL_ 606 PARK_pscLeftCrossObj2Y 2046 "NO_SPACE" 2047 "SNA";
VAL_ 606 PARK_pscLeftCrossObj2X 2046 "NO_SPACE" 2047 "SNA";
VAL_ 606 PARK_pscLeftCrossObj2Alpha 126 "NO_SPACE" 127 "SNA";
VAL_ 606 PARK_pscRightParallelObj1X 2046 "NO_SPACE" 2047 "SNA";
VAL_ 606 PARK_pscRightParallelObj1Y 2046 "NO_SPACE" 2047 "SNA";
VAL_ 606 PARK_pscRightParallelObj1Alpha 126 "NO_SPACE" 127 "SNA";
VAL_ 606 PARK_pscRightParallelObj2Y 2046 "NO_SPACE" 2047 "SNA";
VAL_ 606 PARK_pscRightParallelObj2X 2046 "NO_SPACE" 2047 "SNA";
VAL_ 606 PARK_pscRightParallelObj2Alpha 126 "NO_SPACE" 127 "SNA";
VAL_ 606 PARK_pscRightCrossObj1X 2046 "NO_SPACE" 2047 "SNA";
VAL_ 606 PARK_pscRightCrossObj1Y 2046 "NO_SPACE" 2047 "SNA";
VAL_ 606 PARK_pscRightCrossObj1Alpha 126 "NO_SPACE" 127 "SNA";
VAL_ 606 PARK_pscRightCrossObj2Y 2046 "NO_SPACE" 2047 "SNA";
VAL_ 606 PARK_pscRightCrossObj2X 2046 "NO_SPACE" 2047 "SNA";
VAL_ 606 PARK_pscRightCrossObj2Alpha 126 "NO_SPACE" 127 "SNA";

VAL_ 542 PARK_pscAngleActive 0 "INACTIVE" 1 "REQUEST_CONTROL";
VAL_ 542 PARK_pscCrossLeftParkable 0 "NONE" 1 "PARKING_SLOT_OK" 2 "PARKING_SLOT_OK_POSITION_OK" 3 "SNA";
VAL_ 542 PARK_pscCrossRightParkable 0 "NONE" 1 "PARKING_SLOT_OK" 2 "PARKING_SLOT_OK_POSITION_OK" 3 "SNA";
VAL_ 542 PARK_pscCrossSpace 0 "NONE_AVAILABLE" 1 "RIGHT_AVAILABLE" 2 "LEFT_AVAILABLE" 3 "BOTH_AVAILABLE";
VAL_ 542 PARK_pscManeuverDistance 2047 "SNA";
VAL_ 542 PARK_pscMaxVelocity 63 "SNA";
VAL_ 542 PARK_pscParallelLeftParkable 0 "NONE" 1 "PARKING_SLOT_OK" 2 "PARKING_SLOT_OK_POSITION_OK" 3 "SNA";
VAL_ 542 PARK_pscParallelRightParkable 0 "NONE" 1 "PARKING_SLOT_OK" 2 "PARKING_SLOT_OK_POSITION_OK" 3 "SNA";
VAL_ 542 PARK_pscParallelSpace 0 "NONE_AVAILABLE" 1 "RIGHT_AVAILABLE" 2 "LEFT_AVAILABLE" 3 "BOTH_AVAILABLE";
VAL_ 542 PARK_pscParkAbortReason 0 "NONE" 1 "VELOCITY_TOO_HIGH" 2 "MAX_NUM_OF_MOVES" 3 "NO_VALID_PATH" 4 "UNCONTROLLED_TRAVEL_DIST_REACHED" 5 "OFF_TRACK" 6 "MAX_SWA_DEV_EXCEEDED" 7 "MAX_YAW_ANGLE_REACHED" 8 "OBSTACLE_ON_PATH" 9 "PARK_SPACE_TOO_SMALL" 10 "FULL_WARNING_ON_BOTH_SIDES" 11 "HANDS_ON_DETECTED" 12 "VEHICLE_DYNAMICS_INTERVENTION" 13 "EPAS_FAULT" 14 "DAS_ABORT" 15 "ECU_INTERNAL_FAULT" 16 "SYSTEM_FAULT" 17 "SYSTEM_SERVICE" 18 "ERROR" 31 "SNA";
VAL_ 542 PARK_pscParkInstruction 0 "NO_MESSAGE" 1 "STOP" 2 "DRIVE_FORWARD" 3 "DRIVE_BACKWARD" 4 "ABORTED" 5 "EXPLORATION" 7 "SNA";
VAL_ 542 PARK_pscParkStatus 0 "NOT_AVAILABLE" 1 "SEARCHING" 2 "GUIDANCE_LEFT" 3 "GUIDANCE_RIGHT" 4 "PRE_GUIDANCE" 5 "GUIDANCE_FINISHED" 6 "FAULT" 7 "SNA";

VAL_ 590 PARK_pscVehSlotType 0 "LEFT_PARALLEL" 1 "LEFT_CROSS" 2 "RIGHT_PARALLEL" 3 "RIGHT_CROSS";
VAL_ 590 PARK_pscLeftParallelVehX 2046 "NO_SPACE" 2047 "SNA";
VAL_ 590 PARK_pscLeftParallelVehY 2046 "NO_SPACE" 2047 "SNA";
VAL_ 590 PARK_pscLeftParallelPsi 8190 "NO_SPACE" 8191 "SNA";
VAL_ 590 PARK_pscLeftParallelSizeX 254 "NO_SPACE" 255 "SNA";
VAL_ 590 PARK_pscLeftParallelSizeY 254 "NO_SPACE" 255 "SNA";
VAL_ 590 PARK_pscLeftCrossVehX 2046 "NO_SPACE" 2047 "SNA";
VAL_ 590 PARK_pscLeftCrossVehY 2046 "NO_SPACE" 2047 "SNA";
VAL_ 590 PARK_pscLeftCrossPsi 8190 "NO_SPACE" 8191 "SNA";
VAL_ 590 PARK_pscLeftCrossSizeX 254 "NO_SPACE" 255 "SNA";
VAL_ 590 PARK_pscLeftCrossSizeY 254 "NO_SPACE" 255 "SNA";
VAL_ 590 PARK_pscRightParallelVehX 2046 "NO_SPACE" 2047 "SNA";
VAL_ 590 PARK_pscRightParallelVehY 2046 "NO_SPACE" 2047 "SNA";
VAL_ 590 PARK_pscRightParallelPsi 8190 "NO_SPACE" 8191 "SNA";
VAL_ 590 PARK_pscRightParallelSizeX 254 "NO_SPACE" 255 "SNA";
VAL_ 590 PARK_pscRightParallelSizeY 254 "NO_SPACE" 255 "SNA";
VAL_ 590 PARK_pscRightCrossVehX 2046 "NO_SPACE" 2047 "SNA";
VAL_ 590 PARK_pscRightCrossVehY 2046 "NO_SPACE" 2047 "SNA";
VAL_ 590 PARK_pscRightCrossPsi 8190 "NO_SPACE" 8191 "SNA";
VAL_ 590 PARK_pscRightCrossSizeX 254 "NO_SPACE" 255 "SNA";
VAL_ 590 PARK_pscRightCrossSizeY 254 "NO_SPACE" 255 "SNA";

VAL_ 558 PARK_sdiSensor10RawDistData 0 "BLOCKED" 1 "NEAR_DETECTION" 500 "NO_OBJECT_DETECTED" 511 "SNA";
VAL_ 558 PARK_sdiSensor11RawDistData 0 "BLOCKED" 1 "NEAR_DETECTION" 500 "NO_OBJECT_DETECTED" 511 "SNA";
VAL_ 558 PARK_sdiSensor12RawDistData 0 "BLOCKED" 1 "NEAR_DETECTION" 500 "NO_OBJECT_DETECTED" 511 "SNA";
VAL_ 558 PARK_sdiSensor7RawDistData 0 "BLOCKED" 1 "NEAR_DETECTION" 500 "NO_OBJECT_DETECTED" 511 "SNA";
VAL_ 558 PARK_sdiSensor8RawDistData 0 "BLOCKED" 1 "NEAR_DETECTION" 500 "NO_OBJECT_DETECTED" 511 "SNA";
VAL_ 558 PARK_sdiSensor9RawDistData 0 "BLOCKED" 1 "NEAR_DETECTION" 500 "NO_OBJECT_DETECTED" 511 "SNA";

VAL_ 814 PARK_frontDtcPresent 0 "FALSE" 1 "TRUE" 2 "UNUSED" 3 "SNA";
VAL_ 814 PARK_frontLeftMiddleSensorState 0 "NO_FAILURE" 1 "PERMANENT_FAILURE" 2 "TEMPORARY_FAILURE" 3 "SNA";
VAL_ 814 PARK_frontLeftRawDistData 255 "SNA";
VAL_ 814 PARK_frontLeftSensorState 0 "NO_FAILURE" 1 "PERMANENT_FAILURE" 2 "TEMPORARY_FAILURE" 3 "SNA";
VAL_ 814 PARK_frontRightMiddleSensorState 0 "NO_FAILURE" 1 "PERMANENT_FAILURE" 2 "TEMPORARY_FAILURE" 3 "SNA";
VAL_ 814 PARK_frontRightRawDistData 255 "SNA";
VAL_ 814 PARK_frontRightSensorState 0 "NO_FAILURE" 1 "PERMANENT_FAILURE" 2 "TEMPORARY_FAILURE" 3 "SNA";
VAL_ 814 PARK_systemStatusFront 0 "DISABLED" 1 "ENABLED" 2 "UNUSED" 3 "SNA";

VAL_ 830 PARK_rearDtcPresent 0 "FALSE" 1 "TRUE" 2 "UNUSED" 3 "SNA";
VAL_ 830 PARK_rearLeftMiddleSensorState 0 "NO_FAILURE" 1 "PERMANENT_FAILURE" 2 "TEMPORARY_FAILURE" 3 "SNA";
VAL_ 830 PARK_rearLeftRawDistData 255 "SNA";
VAL_ 830 PARK_rearLeftSensorState 0 "NO_FAILURE" 1 "PERMANENT_FAILURE" 2 "TEMPORARY_FAILURE" 3 "SNA";
VAL_ 830 PARK_rearRightMiddleSensorState 0 "NO_FAILURE" 1 "PERMANENT_FAILURE" 2 "TEMPORARY_FAILURE" 3 "SNA";
VAL_ 830 PARK_rearRightRawDistData 255 "SNA";
VAL_ 830 PARK_rearRightSensorState 0 "NO_FAILURE" 1 "PERMANENT_FAILURE" 2 "TEMPORARY_FAILURE" 3 "SNA";
VAL_ 830 PARK_systemStatusRear 0 "DISABLED" 1 "ENABLED" 2 "UNUSED" 3 "SNA";

VAL_ 782 PARK_autoCalComplete 0 "INCOMPLETE" 1 "COMPLETE";
VAL_ 782 PARK_geometryType 0 "MODELS" 1 "MODELS_2" 2 "MODELX" 3 "MODEL3";
VAL_ 782 PARK_pscLeftCurbType 0 "VIRTUAL_CURB" 1 "LOW_CURB" 2 "HIGH_CURB";
VAL_ 782 PARK_pscRightCurbType 0 "VIRTUAL_CURB" 1 "LOW_CURB" 2 "HIGH_CURB";
VAL_ 782 PARK_rackDetected 0 "UNKNOWN" 1 "NO_RACK" 2 "RACK_DETECTED" 3 "SNA";
VAL_ 782 PARK_sdiActive 0 "DISABLED" 1 "ENABLED";
VAL_ 782 PARK_sdiBlindSpotLeft 0 "NO_WARNING" 1 "WARNING" 2 "UNUSED" 3 "SNA";
VAL_ 782 PARK_sdiBlindSpotRight 0 "NO_WARNING" 1 "WARNING" 2 "UNUSED" 3 "SNA";
VAL_ 782 PARK_sdiNoise 0 "NOMINAL" 1 "HIGH" 2 "RAIN" 3 "SNA";
VAL_ 782 PARK_tireFitment 0 "SQUARE" 1 "STAGGERED" 2 "NOT_USED" 3 "SNA";

VAL_ 894 PARK_matrixIndex 0 "AlertMatrix0" 1 "AlertMatrix1";

VAL_ 932 PCS_matrixIndex 0 "AlertMatrix0" 1 "AlertMatrix1";

VAL_ 516 PCS_chargeStatus 0 "IDLE" 1 "ENABLED" 2 "FAULTED";
VAL_ 516 PCS_chgMainState 0 "INIT" 1 "IDLE" 2 "STARTUP" 3 "WAIT_FOR_LINE_VOLTAGE" 4 "QUALIFY_LINE_CONFIG" 5 "SYSTEM_CONFIG" 6 "ENABLE" 7 "SHUTDOWN" 8 "FAULTED" 9 "CLEAR_FAULTS";
VAL_ 516 PCS_gridConfig 0 "SNA" 1 "SINGLE_PHASE" 2 "THREE_PHASE" 3 "THREE_PHASE_DELTA";

VAL_ 548 PCS_dcdc12VSupportStatus 0 "IDLE" 1 "ACTIVE" 2 "FAULTED";
VAL_ 548 PCS_dcdcHvBusDischargeStatus 0 "IDLE" 1 "ACTIVE" 2 "FAULTED";
VAL_ 548 PCS_dcdcInitialPrechargeSubState 0 "PWR_UP_INIT" 1 "STANDBY" 2 "12V_SUPPORT_ACTIVE" 3 "DIS_HVBUS" 4 "PCHG_FAST_DIS_HVBUS" 5 "PCHG_SLOW_DIS_HVBUS" 6 "PCHG_DWELL_CHARGE" 7 "PCHG_DWELL_WAIT" 8 "PCHG_DI_RECOVERY_WAIT" 9 "PCHG_ACTIVE" 10 "PCHG_FLT_FAST_DIS_HVBUS" 11 "SHUTDOWN" 12 "12V_SUPPORT_FAULTED" 13 "DIS_HVBUS_FAULTED" 14 "PCHG_FAULTED" 15 "CLEAR_FAULTS" 16 "FAULTED" 17 "NUM";
VAL_ 548 PCS_dcdcMainState 0 "STANDBY" 1 "12V_SUPPORT_ACTIVE" 2 "PRECHARGE_STARTUP" 3 "PRECHARGE_ACTIVE" 4 "DIS_HVBUS_ACTIVE" 5 "SHUTDOWN" 6 "FAULTED";
VAL_ 548 PCS_dcdcPrechargeStatus 0 "IDLE" 1 "ACTIVE" 2 "FAULTED";
VAL_ 548 PCS_dcdcSubState 0 "PWR_UP_INIT" 1 "STANDBY" 2 "12V_SUPPORT_ACTIVE" 3 "DIS_HVBUS" 4 "PCHG_FAST_DIS_HVBUS" 5 "PCHG_SLOW_DIS_HVBUS" 6 "PCHG_DWELL_CHARGE" 7 "PCHG_DWELL_WAIT" 8 "PCHG_DI_RECOVERY_WAIT" 9 "PCHG_ACTIVE" 10 "PCHG_FLT_FAST_DIS_HVBUS" 11 "SHUTDOWN" 12 "12V_SUPPORT_FAULTED" 13 "DIS_HVBUS_FAULTED" 14 "PCHG_FAULTED" 15 "CLEAR_FAULTS" 16 "FAULTED" 17 "NUM";
VAL_ 548 PCS_ecuLogUploadRequest 0 "NONE" 1 "1" 2 "2" 3 "3";

VAL_ 964 PCS_infoIndex 0 "DEPRECATED_0" 1 "DEPRECATED_1" 2 "DEPRECATED_2" 3 "DEPRECATED_3" 4 "DEPRECATED_4" 5 "DEPRECATED_5" 6 "DEPRECATED_6" 7 "DEPRECATED_7" 8 "DEPRECATED_8" 9 "DEPRECATED_9" 10 "BUILD_HWID_COMPONENTID" 11 "PCBAID_ASSYID_USAGEID" 13 "APP_CRC" 14 "BOOTLOADER_SVN" 15 "BOOTLOADER_CRC" 16 "SUBCOMPONENT" 17 "APP_GITHASH" 18 "BOOTLOADER_GITHASH" 19 "VERSION_DEPRECATED" 20 "UDS_PROTOCOL_BOOTCRC" 22 "VARIANTCRC" 25 "PACKAGE_PN_1_7" 26 "PACKAGE_PN_8_14" 27 "PACKAGE_PN_15_20" 29 "PACKAGE_SN_1_7" 30 "PACKAGE_SN_8_14" 31 "SUBCOMPONENT_GITHASH" 255 "END";
VAL_ 964 PCS_buildType 0 "UNKNOWN_BUILD" 1 "PLATFORM_BUILD" 2 "LOCAL_BUILD" 3 "TRACEABLE_CI_BUILD" 4 "MFG_BUILD";

VAL_ 708 PCS_logMessageSelect 0 "PHA_1" 1 "PHB_1" 2 "PHC_1" 3 "CHG_1" 4 "CHG_2" 5 "CHG_3" 6 "DCDC_1" 7 "DCDC_2" 8 "DCDC_3" 9 "SYSTEM_1" 10 "PHA_2" 11 "PHB_2" 12 "PHC_2" 13 "CHG_4" 14 "DLOG_1" 15 "DLOG_2" 16 "DLOG_3" 17 "DLOG_4" 18 "DCDC_4" 19 "DCDC_5" 20 "CHG_NO_FLOW" 21 "CHG_LINE_OFFSET" 22 "DCDC_STATISTICS" 23 "CHG_STATISTICS" 24 "NUM_MSGS";
VAL_ 708 PCS_chgInputFrequencyL1N 0 "FREQUENCY_UNKNOWN";
VAL_ 708 PCS_chgInputFrequencyL2N 0 "FREQUENCY_UNKNOWN";
VAL_ 708 PCS_chgInputFrequencyL3N 0 "FREQUENCY_UNKNOWN";
VAL_ 708 PCS_chgInternalPhaseConfig 0 "SNA" 1 "SINGLE_PHASE" 2 "THREE_PHASE" 3 "THREE_PHASE_DELTA" 4 "SINGLE_PHASE_IEC_GB" 5 "MFG_TEST_CONFIG_1" 6 "MFG_TEST_CONFIG_2" 7 "TOTAL_NUM";
VAL_ 708 PCS_chgPhAState 0 "INIT" 1 "IDLE" 2 "PRECHARGE" 3 "ENABLE" 4 "FAULT" 5 "CLEAR_FAULTS" 6 "SHUTTING_DOWN";
VAL_ 708 PCS_chgPhBState 0 "INIT" 1 "IDLE" 2 "PRECHARGE" 3 "ENABLE" 4 "FAULT" 5 "CLEAR_FAULTS" 6 "SHUTTING_DOWN";
VAL_ 708 PCS_chgPhCState 0 "INIT" 1 "IDLE" 2 "PRECHARGE" 3 "ENABLE" 4 "FAULT" 5 "CLEAR_FAULTS" 6 "SHUTTING_DOWN";
VAL_ 708 PCS_chgPhALastShutdownReason 0 "REASON_NONE" 1 "SW_ENABLE" 2 "HW_ENABLE" 3 "SW_FAULT" 4 "HW_FAULT" 5 "PLL_NOT_LOCKED" 6 "INPUT_UV" 7 "INPUT_OV" 8 "OUTPUT_UV" 9 "OUTPUT_OV" 10 "PRECHARGE_TIMEOUT" 11 "INT_BUS_UV" 12 "CONTROL_REGULATION_FAULT" 13 "OVER_TEMPERATURE" 14 "TEMP_IRRATIONAL" 15 "SENSOR_IRRATIONAL" 16 "FREQ_OUT_OF_RANGE" 17 "LINE_TRANSIENT_FAULT";
VAL_ 708 PCS_chgPhBLastShutdownReason 0 "REASON_NONE" 1 "SW_ENABLE" 2 "HW_ENABLE" 3 "SW_FAULT" 4 "HW_FAULT" 5 "PLL_NOT_LOCKED" 6 "INPUT_UV" 7 "INPUT_OV" 8 "OUTPUT_UV" 9 "OUTPUT_OV" 10 "PRECHARGE_TIMEOUT" 11 "INT_BUS_UV" 12 "CONTROL_REGULATION_FAULT" 13 "OVER_TEMPERATURE" 14 "TEMP_IRRATIONAL" 15 "SENSOR_IRRATIONAL" 16 "FREQ_OUT_OF_RANGE" 17 "LINE_TRANSIENT_FAULT";
VAL_ 708 PCS_chgPhCLastShutdownReason 0 "REASON_NONE" 1 "SW_ENABLE" 2 "HW_ENABLE" 3 "SW_FAULT" 4 "HW_FAULT" 5 "PLL_NOT_LOCKED" 6 "INPUT_UV" 7 "INPUT_OV" 8 "OUTPUT_UV" 9 "OUTPUT_OV" 10 "PRECHARGE_TIMEOUT" 11 "INT_BUS_UV" 12 "CONTROL_REGULATION_FAULT" 13 "OVER_TEMPERATURE" 14 "TEMP_IRRATIONAL" 15 "SENSOR_IRRATIONAL" 16 "FREQ_OUT_OF_RANGE" 17 "LINE_TRANSIENT_FAULT";
VAL_ 708 PCS_dcdcTankVoltage -1024 "TANK_VOLTAGE_SNA";
VAL_ 708 PCS_cpu2BootState 0 "BOOTROM" 1 "BOOTLOADER" 2 "APPLICATION" 3 "ERROR";
VAL_ 708 PCS_acChargeSelfTestState 0 "IDLE" 1 "STARTED";
VAL_ 708 PCS_chgInputFreqWobblePHAPeak 0 "FREQUENCY_UNKNOWN";
VAL_ 708 PCS_chgInputFreqWobblePHBPeak 0 "FREQUENCY_UNKNOWN";
VAL_ 708 PCS_chgInputFreqWobblePHCPeak 0 "FREQUENCY_UNKNOWN";
VAL_ 708 PCS_dLogPhAChannel1Content 0 "INPUT_VOLTAGE" 1 "INPUT_CURRENT" 2 "OUTPUT_CURRENT" 3 "INT_BUS_VOLTAGE";
VAL_ 708 PCS_dLogPhBChannel1Content 0 "INPUT_VOLTAGE" 1 "INPUT_CURRENT" 2 "OUTPUT_CURRENT" 3 "INT_BUS_VOLTAGE";
VAL_ 708 PCS_dLogPhCChannel1Content 0 "INPUT_VOLTAGE" 1 "INPUT_CURRENT" 2 "OUTPUT_CURRENT" 3 "INT_BUS_VOLTAGE";
VAL_ 708 PCS_dLogPhAChannel2Content 0 "INPUT_VOLTAGE" 1 "INPUT_CURRENT" 2 "OUTPUT_CURRENT" 3 "INT_BUS_VOLTAGE";
VAL_ 708 PCS_dLogPhBChannel2Content 0 "INPUT_VOLTAGE" 1 "INPUT_CURRENT" 2 "OUTPUT_CURRENT" 3 "INT_BUS_VOLTAGE";
VAL_ 708 PCS_dLogPhCChannel2Content 0 "INPUT_VOLTAGE" 1 "INPUT_CURRENT" 2 "OUTPUT_CURRENT" 3 "INT_BUS_VOLTAGE";
VAL_ 708 PCS_dLogPhAChannel3Content 0 "INPUT_VOLTAGE" 1 "INPUT_CURRENT" 2 "OUTPUT_CURRENT" 3 "INT_BUS_VOLTAGE";
VAL_ 708 PCS_dLogPhBChannel3Content 0 "INPUT_VOLTAGE" 1 "INPUT_CURRENT" 2 "OUTPUT_CURRENT" 3 "INT_BUS_VOLTAGE";
VAL_ 708 PCS_dLogPhCChannel3Content 0 "INPUT_VOLTAGE" 1 "INPUT_CURRENT" 2 "OUTPUT_CURRENT" 3 "INT_BUS_VOLTAGE";
VAL_ 708 PCS_dLogPhAChannel4Content 0 "INPUT_VOLTAGE" 1 "INPUT_CURRENT" 2 "OUTPUT_CURRENT" 3 "INT_BUS_VOLTAGE";
VAL_ 708 PCS_dLogPhBChannel4Content 0 "INPUT_VOLTAGE" 1 "INPUT_CURRENT" 2 "OUTPUT_CURRENT" 3 "INT_BUS_VOLTAGE";
VAL_ 708 PCS_dLogPhCChannel4Content 0 "INPUT_VOLTAGE" 1 "INPUT_CURRENT" 2 "OUTPUT_CURRENT" 3 "INT_BUS_VOLTAGE";

VAL_ 790 PM_infoIndex 0 "DEPRECATED_0" 1 "DEPRECATED_1" 2 "DEPRECATED_2" 3 "DEPRECATED_3" 4 "DEPRECATED_4" 5 "DEPRECATED_5" 6 "DEPRECATED_6" 7 "DEPRECATED_7" 8 "DEPRECATED_8" 9 "DEPRECATED_9" 10 "BUILD_HWID_COMPONENTID" 11 "PCBAID_ASSYID_USAGEID" 13 "APP_CRC" 14 "BOOTLOADER_SVN" 15 "BOOTLOADER_CRC" 16 "SUBCOMPONENT" 17 "APP_GITHASH" 18 "BOOTLOADER_GITHASH" 19 "VERSION_DEPRECATED" 20 "UDS_PROTOCOL_BOOTCRC" 22 "VARIANTCRC" 25 "PACKAGE_PN_1_7" 26 "PACKAGE_PN_8_14" 27 "PACKAGE_PN_15_20" 29 "PACKAGE_SN_1_7" 30 "PACKAGE_SN_8_14" 31 "SUBCOMPONENT_GITHASH" 255 "END";
VAL_ 790 PM_buildType 0 "UNKNOWN_BUILD" 1 "PLATFORM_BUILD" 2 "LOCAL_BUILD" 3 "TRACEABLE_CI_BUILD" 4 "MFG_BUILD";
VAL_ 790 PM_hardwareId 252 "CONFIGURABLE_HWID_PLACEHOLDER";

VAL_ 837 PTC_infoIndex 0 "DEPRECATED_0" 1 "DEPRECATED_1" 2 "DEPRECATED_2" 3 "DEPRECATED_3" 4 "DEPRECATED_4" 5 "DEPRECATED_5" 6 "DEPRECATED_6" 7 "DEPRECATED_7" 8 "DEPRECATED_8" 9 "DEPRECATED_9" 10 "BUILD_HWID_COMPONENTID" 11 "PCBAID_ASSYID_USAGEID" 13 "APP_CRC" 14 "BOOTLOADER_SVN" 15 "BOOTLOADER_CRC" 16 "SUBCOMPONENT" 17 "APP_GITHASH" 18 "BOOTLOADER_GITHASH" 19 "VERSION_DEPRECATED" 20 "UDS_PROTOCOL_BOOTCRC" 22 "VARIANTCRC" 25 "PACKAGE_PN_1_7" 26 "PACKAGE_PN_8_14" 27 "PACKAGE_PN_15_20" 29 "PACKAGE_SN_1_7" 30 "PACKAGE_SN_8_14" 31 "SUBCOMPONENT_GITHASH" 255 "END";
VAL_ 837 PTC_infoBuildType 0 "UNKNOWN_BUILD" 1 "PLATFORM_BUILD" 2 "LOCAL_BUILD" 3 "TRACEABLE_CI_BUILD" 4 "MFG_BUILD";
VAL_ 837 PTC_infoAssemblyId 1 "ASSEMBLY1" 255 "ASSEMBLY_SNA";

VAL_ 1329 RADC_infoIndex 10 "Mux10" 11 "Mux11" 13 "Mux13" 19 "Mux19" 20 "Mux20";
VAL_ 1329 RADC_infoBuildType 0 "UNKNOWN_BUILD" 1 "PLATFORM_BUILD" 2 "LOCAL_BUILD" 3 "TRACEABLE_CI_BUILD" 4 "MFG_BUILD";

VAL_ 881 RCM_matrixIndex 0 "AlertMatrix0" 1 "AlertMatrix1";

VAL_ 17 RCM_collisionFront 0 "INACTIVE" 1 "ACTIVE" 3 "SNA";
VAL_ 17 RCM_collisionLeft 0 "INACTIVE" 1 "ACTIVE" 3 "SNA";
VAL_ 17 RCM_collisionRear 0 "INACTIVE" 1 "ACTIVE" 3 "SNA";
VAL_ 17 RCM_collisionRight 0 "INACTIVE" 1 "ACTIVE" 3 "SNA";
VAL_ 17 RCM_collisionRollover 0 "INACTIVE" 1 "ACTIVE" 3 "SNA";
VAL_ 17 RCM_collisionSeverity 0 "PRETENSIONER" 1 "FIRST_STAGE" 2 "SECOND_STAGE" 3 "PEDPRO_EVENT";

VAL_ 257 RCM_pitchRate -16384 "SNA";
VAL_ 257 RCM_pitchRateQF 0 "INIT" 1 "VALID" 2 "TEMP_INVALID" 3 "FAULTED";
VAL_ 257 RCM_rollRate -16384 "SNA";
VAL_ 257 RCM_rollRateQF 0 "INIT" 1 "VALID" 2 "TEMP_INVALID" 3 "FAULTED";
VAL_ 257 RCM_yawRate -32768 "SNA";
VAL_ 257 RCM_yawRateQF 0 "FAULTED" 1 "NOT_FAULTED";
VAL_ 273 RCM_lateralAccel -32768 "SNA" ;
VAL_ 273 RCM_lateralAccelQF 0 "FAULTED" 1 "NOT_FAULTED" ;
VAL_ 273 RCM_longitudinalAccel -32768 "SNA" ;
VAL_ 273 RCM_longitudinalAccelQF 0 "FAULTED" 1 "NOT_FAULTED" ;
VAL_ 273 RCM_verticalAccel -32768 "SNA" ;
VAL_ 273 RCM_verticalAccelQF 0 "FAULTED" 1 "NOT_FAULTED" ;

VAL_ 849 RCM_infoIndex 0 "DEPRECATED_0" 1 "DEPRECATED_1" 2 "DEPRECATED_2" 3 "DEPRECATED_3" 4 "DEPRECATED_4" 5 "DEPRECATED_5" 6 "DEPRECATED_6" 7 "DEPRECATED_7" 8 "DEPRECATED_8" 9 "DEPRECATED_9" 10 "BUILD_HWID_COMPONENTID" 11 "PCBAID_ASSYID_USAGEID" 13 "APP_CRC" 14 "BOOTLOADER_SVN" 15 "BOOTLOADER_CRC" 16 "SUBCOMPONENT" 17 "APP_GITHASH" 18 "BOOTLOADER_GITHASH" 19 "VERSION_DEPRECATED" 20 "UDS_PROTOCOL_BOOTCRC" 22 "VARIANTCRC" 25 "PACKAGE_PN_1_7" 26 "PACKAGE_PN_8_14" 27 "PACKAGE_PN_15_20" 29 "PACKAGE_SN_1_7" 30 "PACKAGE_SN_8_14" 31 "SUBCOMPONENT_GITHASH" 255 "END";
VAL_ 849 RCM_infoBuildType 0 "UNKNOWN_BUILD" 1 "PLATFORM_BUILD" 2 "LOCAL_BUILD" 3 "TRACEABLE_CI_BUILD" 4 "MFG_BUILD";

VAL_ 289 RCM_crashAlgoWakeup 0 "INACTIVE" 1 "ACTIVE" 3 "SNA";
VAL_ 289 RCM_nearDeployFront 0 "INACTIVE" 1 "ACTIVE" 3 "SNA";
VAL_ 289 RCM_nearDeployLeft 0 "INACTIVE" 1 "ACTIVE" 3 "SNA";
VAL_ 289 RCM_nearDeployRear 0 "INACTIVE" 1 "ACTIVE" 3 "SNA";
VAL_ 289 RCM_nearDeployRight 0 "INACTIVE" 1 "ACTIVE" 3 "SNA";
VAL_ 289 RCM_nearDeployRollover 0 "INACTIVE" 1 "ACTIVE" 3 "SNA";

VAL_ 529 RCM_airbagCutoffStatus 0 "RCM_PASSENGER_AIRBAG_ENABLED" 1 "RCM_PASSENGER_AIRBAG_DISABLED" 3 "SNA";
VAL_ 529 RCM_alrSwitchStatus 0 "RCM_ALR_NOT_ENGAGED" 1 "RCM_ALR_ENGAGED" 2 "RCM_ALR_FAULTED" 3 "SNA";
VAL_ 529 RCM_armStatus 0 "RCM_UNARMED" 1 "RCM_ARMED" 2 "ARMED_WITH_NOFIRE_CAL" 3 "SNA";
VAL_ 529 RCM_driverOrientationInitStatus 0 "RCM_DRIVER_ORIENTATION_INIT_NOT_COMPLETE" 1 "RCM_DRIVER_ORIENTATION_MATCHED_LHD" 2 "RCM_DRIVER_ORIENTATION_MATCHED_RHD" 3 "RCM_DRIVER_ORIENTATION_MISMATCH_DEFAULT_LHD" 4 "RCM_DRIVER_ORIENTATION_MISMATCH_DEFAULT_RHD" 7 "SNA";
VAL_ 529 RCM_edr1State 0 "EMPTY" 1 "STORED" 2 "LOCKED" 3 "UNAVAILABLE";
VAL_ 529 RCM_edr2State 0 "EMPTY" 1 "STORED" 2 "LOCKED" 3 "UNAVAILABLE";
VAL_ 529 RCM_imuOffsetLearnState 0 "OFFSET_LEARNING_OFF" 1 "SLOW_LEARNING_DISTANCE" 2 "FAST_LEARNING_TIME" 3 "OFFSETS_UNABLE_TO_LEARN";
VAL_ 529 RCM_keepPowerReason 0 "NO_KEEP_POWER_REQUEST" 1 "IN_IDLE_MODE" 2 "CRASH_ALGO_ACTIVE" 3 "EDR_STORING_TO_EEPROM" 4 "EDR_UPLOADING" 5 "CANNOT_POWER_DOWN" 6 "INITIALIZATION_PHASE" 7 "INVALID_POWER_OFF_REQUEST";
VAL_ 529 RCM_passAirbagIndicatorRequest 0 "RCM_PASSENGER_AIRBAG_INDICATOR_ON" 1 "RCM_PASSENGER_AIRBAG_INDICATOR_OFF" 3 "SNA";
VAL_ 529 RCM_seatTrackPositionDrvr 0 "RCM_SEAT_POSITION_NEAR" 1 "RCM_SEAT_POSITION_FAR" 2 "RCM_SEAT_POSITION_FAULTED" 3 "SNA";
VAL_ 529 RCM_seatTrackPositionPass 0 "RCM_SEAT_POSITION_NEAR" 1 "RCM_SEAT_POSITION_FAR" 2 "RCM_SEAT_POSITION_FAULTED" 3 "SNA";
VAL_ 529 RCM_vinLearnFlag 0 "RCM_VIN_NOT_STORED" 1 "RCM_VIN_STORED" 2 "RCM_VIN_STORED_MISMATCH" 3 "SNA";
VAL_ 529 RCM_warningIndicatorState 0 "RCM_WARNING_INDICATOR_OFF" 1 "RCM_WARNING_INDICATOR_ON" 3 "SNA";

VAL_ 1359 SCCM_matrixIndex 0 "SCCM_AlertMatrix0";

VAL_ 1357 TAS_infoIndex 0 "DEPRECATED_0" 1 "DEPRECATED_1" 2 "DEPRECATED_2" 3 "DEPRECATED_3" 4 "DEPRECATED_4" 5 "DEPRECATED_5" 6 "DEPRECATED_6" 7 "DEPRECATED_7" 8 "DEPRECATED_8" 9 "DEPRECATED_9" 10 "BUILD_HWID_COMPONENTID" 11 "PCBAID_ASSYID_USAGEID" 13 "APP_CRC" 14 "BOOTLOADER_SVN" 15 "BOOTLOADER_CRC" 16 "SUBCOMPONENT1" 17 "APP_GITHASH" 18 "BOOTLOADER_GITHASH" 19 "VERSION_DEPRECATED" 20 "UDS_PROTOCOL_BOOTCRC" 23 "SUBCOMPONENT2" 24 "SUBCOMPONENT3" 31 "SUBCOMPONENT4" 255 "END";
VAL_ 1357 TAS_infoBuildType 0 "UNKNOWN_BUILD" 1 "PLATFORM_BUILD" 2 "LOCAL_BUILD" 3 "TRACEABLE_CI_BUILD" 4 "MFG_BUILD";
VAL_ 1357 TAS_infoAssemblyId 1 "ASSEMBLY1" 255 "ASSEMBLY_SNA";
VAL_ 1357 TAS_infoMajorVersion 254 "LOCAL_BUILD" 255 "SNA";
VAL_ 1357 TAS_infoBranchOrigin 254 "LOCAL_BUILD" 255 "SNA";
VAL_ 1357 TAS_infoMaturity 254 "LOCAL_BUILD" 255 "SNA";
VAL_ 1357 TAS_infoHardwareRevision 254 "LOCAL_BUILD" 255 "SNA";

VAL_ 525 TAS_currentLevel 0 "VERY_HIGH" 1 "HIGH" 2 "STANDARD" 3 "LOW" 4 "VERY_LOW";
VAL_ 525 TAS_filterMode 0 "NONE" 1 "INIT" 2 "CALIBRATE" 3 "TEST" 4 "READY" 5 "LOADING" 6 "DRIVE" 7 "STOPPING";
VAL_ 525 TAS_levelingState 0 "IDLE" 1 "READ_P_RESERVOIR" 2 "MANUAL_SPRING_CONTROL" 3 "EXHAUST_GALLERY" 4 "COMPRESSOR_RAMPUP" 5 "COMPRESSOR_PREFILL_GALLERY" 6 "FILL_RESERVOIR_FROM_COMPRESSOR" 7 "FILL_SPRING_FROM_COMPRESSOR" 8 "FILL_SPRING_FROM_BOOST" 9 "FILL_SPRING_FROM_RESERVOIR" 10 "FILL_SPRING_RESERVOIR_FROM_COMPRESSOR" 11 "LOWER_SPRING" 12 "EMPTY_RESERVOIR";
VAL_ 525 TAS_limpHomeMode 0 "0" 1 "10" 2 "20" 3 "30" 4 "40";
VAL_ 525 TAS_runMode 0 "INIT" 1 "SYSTEM_CHECK" 2 "SERVICE" 3 "ASSEMBLY" 4 "DAN" 5 "NORMAL" 6 "LOW_POWER";
VAL_ 525 TAS_targetLevel 0 "VERY_HIGH" 1 "HIGH" 2 "STANDARD" 3 "LOW" 4 "VERY_LOW";

VAL_ 879 TPMS_learningStatus 0 "FAILED" 1 "ONGOING" 2 "STOPPED" 3 "PASSED";
VAL_ 879 TPMS_localisationStatus 0 "FAILED" 1 "ONGOING" 2 "STOPPED" 3 "PASSED";

VAL_ 799 TPMS_pressureFL 255 "SNA";
VAL_ 799 TPMS_pressureFR 255 "SNA";
VAL_ 799 TPMS_pressureRL 255 "SNA";
VAL_ 799 TPMS_pressureRR 255 "SNA";
VAL_ 799 TPMS_temperatureFL 255 "SNA";
VAL_ 799 TPMS_temperatureFR 255 "SNA";
VAL_ 799 TPMS_temperatureRL 255 "SNA";
VAL_ 799 TPMS_temperatureRR 255 "SNA";

VAL_ 1519 TPMS_infoIndex 0 "DEPRECATED_0" 1 "DEPRECATED_1" 2 "DEPRECATED_2" 3 "DEPRECATED_3" 4 "DEPRECATED_4" 5 "DEPRECATED_5" 6 "DEPRECATED_6" 7 "DEPRECATED_7" 8 "DEPRECATED_8" 9 "DEPRECATED_9" 10 "BUILD_HWID_COMPONENTID" 11 "PCBAID_ASSYID_USAGEID" 13 "APP_CRC" 14 "BOOTLOADER_SVN" 15 "BOOTLOADER_CRC" 16 "SUBCOMPONENT" 17 "APP_GITHASH" 18 "BOOTLOADER_GITHASH" 19 "VERSION_DEPRECATED" 20 "UDS_PROTOCOL_BOOTCRC" 22 "VARIANTCRC" 25 "PACKAGE_PN_1_7" 26 "PACKAGE_PN_8_14" 27 "PACKAGE_PN_15_20" 29 "PACKAGE_SN_1_7" 30 "PACKAGE_SN_8_14" 31 "SUBCOMPONENT_GITHASH" 255 "END";

VAL_ 1021 UI_autopilotControlIndex 0 "0" 1 "1" 2 "2" 3 "3" 4 "4" 5 "5" 6 "6" 7 "7";
VAL_ 1021 UI_hovEnabled 0 "OFF" 1 "ON";
VAL_ 1021 UI_donDisableAutoWiperDuration 0 "DEFAULT" 1 "5_S" 2 "15_S" 3 "30_S" 4 "60_S" 5 "120_S" 6 "OFF";
VAL_ 1021 UI_donDisableOnAutoWiperSpeed 0 "OFF" 1 "1" 2 "2" 3 "3" 4 "4" 5 "5" 6 "6" 7 "7" 8 "8" 9 "9" 10 "10" 11 "11" 12 "12" 13 "13" 14 "14" 15 "INVALID";
VAL_ 1021 UI_blindspotMinSpeed 0 "DEFAULT" 1 "5_KPH" 2 "10_KPH" 3 "15_KPH" 4 "20_KPH" 5 "25_KPH" 6 "30_KPH" 7 "35_KPH" 8 "40_KPH" 9 "45_KPH" 10 "OFF";
VAL_ 1021 UI_blindspotDistance 0 "DEFAULT" 1 "0P5_M" 2 "1_M" 3 "2_M" 4 "4_M" 5 "OFF";
VAL_ 1021 UI_blindspotTTC 0 "DEFAULT" 1 "0P5_S" 2 "1_S" 3 "2_S" 4 "4_S" 5 "3_S" 6 "5_S" 7 "OFF";
VAL_ 1021 UI_donStopEndOfRampBuffer 0 "DEFAULT" 1 "15_M" 2 "30_M" 3 "45_M" 4 "OFF";
VAL_ 1021 UI_donDisableCutin 0 "OFF" 1 "ON";
VAL_ 1021 UI_donMinGoreWidthForAbortMap 0 "DEFAULT" 1 "0_M" 2 "0P5_M" 3 "1_M" 4 "1P5_M" 5 "2_M" 6 "2P5_M" 7 "3_M" 8 "3P5_M" 9 "4_M" 10 "4P5_M" 11 "5_M";
VAL_ 1021 UI_donAlcProgGoreAbortThres 0 "DEFAULT" 1 "0P00" 2 "0P05" 3 "0P10" 4 "0P15" 5 "0P20" 6 "0P25" 7 "0P30" 8 "0P35" 9 "0P40";
VAL_ 1021 UI_donMinGoreWidthForAbortNotMap 0 "DEFAULT" 1 "0_M" 2 "0P5_M" 3 "1_M" 4 "1P5_M" 5 "2_M" 6 "2P5_M" 7 "3_M" 8 "3P5_M" 9 "4_M" 10 "4P5_M" 11 "5_M";

VAL_ 659 UI_accOvertakeEnable 0 "ACC_OVERTAKE_OFF" 1 "ACC_OVERTAKE_ON" 3 "SNA";
VAL_ 659 UI_aebEnable 0 "AEB_OFF" 1 "AEB_ON" 3 "SNA";
VAL_ 659 UI_aesEnable 0 "AES_OFF" 1 "AES_ON" 3 "SNA";
VAL_ 659 UI_ahlbEnable 0 "AHLB_OFF" 1 "AHLB_ON" 3 "SNA";
VAL_ 659 UI_autoLaneChangeEnable 0 "OFF" 1 "ON" 3 "SNA";
VAL_ 659 UI_autoParkRequest 0 "NONE" 1 "PARK_LEFT_PARALLEL" 2 "PARK_LEFT_CROSS" 3 "PARK_RIGHT_PARALLEL" 4 "PARK_RIGHT_CROSS" 5 "PARALLEL_PULL_OUT_TO_LEFT" 6 "PARALLEL_PULL_OUT_TO_RIGHT" 7 "ABORT" 8 "COMPLETE" 9 "SEARCH" 10 "PAUSE" 11 "RESUME" 15 "SNA";
VAL_ 659 UI_bsdEnable 0 "BSD_OFF" 1 "BSD_ON" 3 "SNA";
VAL_ 659 UI_distanceUnits 0 "KM" 1 "MILES";
VAL_ 659 UI_fcwEnable 0 "FCW_OFF" 1 "FCW_ON" 3 "SNA";
VAL_ 659 UI_fcwSensitivity 0 "AEB_SENSITIVITY_EARLY" 1 "AEB_SENSITIVITY_AVERAGE" 2 "AEB_SENSITIVITY_LATE" 3 "SNA";
VAL_ 659 UI_latControlEnable 0 "OFF" 1 "ON" 2 "UNAVAILABLE" 3 "SNA";
VAL_ 659 UI_ldwEnable 0 "NO_HAPTIC" 1 "LDW_TRIGGERS_HAPTIC" 3 "SNA";
VAL_ 659 UI_parkBrakeRequest 0 "IDLE" 1 "PRESSED" 3 "SNA";
VAL_ 659 UI_pedalSafetyEnable 0 "PEDAL_SAFETY_OFF" 1 "PEDAL_SAFETY_ON" 3 "SNA";
VAL_ 659 UI_redLightStopSignEnable 0 "RLSSW_OFF" 1 "RLSSW_ON" 3 "SNA";
VAL_ 659 UI_selfParkTune 15 "SNA";
VAL_ 659 UI_steeringTuneRequest 0 "COMFORT" 1 "STANDARD" 2 "SPORT";
VAL_ 659 UI_suspensionLevelRequest 0 "NO_CHANGE_SNA" 1 "REQUEST_LOW_LEVEL" 2 "REQUEST_NORMAL_LEVEL" 3 "REQUEST_HIGH_LEVEL" 4 "REQUEST_VERY_HIGH_LEVEL" 5 "TOGGLE_JACK_MODE" 6 "SWITCH_DEFECT" 7 "REQUEST_VERY_LOW_LEVEL";
VAL_ 659 UI_tractionControlMode 0 "NORMAL_SELECTED" 1 "SLIP_START_SELECTED" 2 "DEV_MODE_1_SELECTED" 3 "DEV_MODE_2_SELECTED" 4 "ROLLS_MODE_SELECTED" 5 "DYNO_MODE_SELECTED";
VAL_ 659 UI_trailerMode 0 "OFF" 1 "ON";
VAL_ 659 UI_winchModeRequest 0 "IDLE" 1 "ENTER" 2 "EXIT";
VAL_ 659 UI_zeroSpeedConfirmed 0 "CANCELED" 1 "CONFIRMED" 2 "UNUSED" 3 "SNA";

VAL_ 531 UI_cruiseSpeedCommand 0 "IDLE" 1 "INC_SHORT" 2 "INC_LONG" 3 "DEC_SHORT" 4 "DEC_LONG" 5 "SNAP";
VAL_ 531 UI_speedLimitTick 255 "SNA";

VAL_ 1280 UI_debugEcuTarget 1 "DI" 2 "DIS" 3 "PM" 4 "PMS" 5 "BMS" 6 "VCRIGHT" 7 "VCFRONT";

VAL_ 1016 UI_accFollowDistanceSetting 0 "1" 1 "2" 2 "3" 3 "4" 4 "5" 5 "6" 6 "7" 7 "SNA";
VAL_ 1016 UI_autopilotControlRequest 0 "LEGACY_LAT_CTRL" 1 "NEXT_GEN_CTRL";
VAL_ 1016 UI_curvSpeedAdaptDisable 0 "ON" 1 "OFF";
VAL_ 1016 UI_curvatureDatabaseOnly 0 "OFF" 1 "ON";
VAL_ 1016 UI_driveOnMapsEnable 0 "OFF" 1 "ON";
VAL_ 1016 UI_drivingSide 0 "LEFT" 1 "RIGHT" 2 "UNKNOWN";
VAL_ 1016 UI_exceptionListEnable 0 "OFF" 1 "ON";
VAL_ 1016 UI_followNavRouteEnable 0 "OFF" 1 "ON";
VAL_ 1016 UI_forksEnable 0 "OFF" 1 "ON";
VAL_ 1016 UI_fuseHPPDisable 0 "ON" 1 "OFF";
VAL_ 1016 UI_fuseLanesDisable 0 "ON" 1 "OFF";
VAL_ 1016 UI_fuseVehiclesDisable 0 "ON" 1 "OFF";
VAL_ 1016 UI_handsOnRequirementDisable 0 "ON" 1 "OFF";
VAL_ 1016 UI_lssElkEnabled 0 "OFF" 1 "ON";
VAL_ 1016 UI_lssLdwEnabled 0 "OFF" 1 "ON";
VAL_ 1016 UI_lssLkaEnabled 0 "OFF" 1 "ON";
VAL_ 1016 UI_roadCheckDisable 0 "ON" 1 "OFF";
VAL_ 1016 UI_selfParkRequest 0 "NONE" 1 "SELF_PARK_FORWARD" 2 "SELF_PARK_REVERSE" 3 "ABORT" 4 "PRIME" 5 "PAUSE" 6 "RESUME" 7 "AUTO_SUMMON_FORWARD" 8 "AUTO_SUMMON_REVERSE" 9 "AUTO_SUMMON_CANCEL" 10 "AUTO_SUMMON_PRIMED" 15 "SNA";
VAL_ 1016 UI_source3D 0 "Z_FROM_MAP" 1 "Z_FROM_PATH_PREDICTION" 2 "XYZ_PREDICTION";
VAL_ 1016 UI_summonEntryType 0 "STRAIGHT" 1 "TURN_RIGHT" 2 "TURN_LEFT" 3 "SNA";
VAL_ 1016 UI_summonExitType 0 "STRAIGHT" 1 "TURN_RIGHT" 2 "TURN_LEFT" 3 "SNA";
VAL_ 1016 UI_summonReverseDist 63 "SNA";
VAL_ 1016 UI_ulcBlindSpotConfig 0 "STANDARD" 1 "AGGRESSIVE" 2 "MAD_MAX";
VAL_ 1016 UI_ulcSpeedConfig 0 "7MPH" 1 "10MPH" 2 "15MPH";
VAL_ 1016 UI_visionSpeedType 0 "DISABLED" 1 "ONE_SECOND" 2 "TWO_SECOND" 3 "OPTIMIZED";

VAL_ 568 UI_countryCode 0 "UNKNOWN" 1023 "SNA";
VAL_ 568 UI_mapSpeedLimit 0 "UNKNOWN" 1 "LESS_OR_EQ_5" 2 "LESS_OR_EQ_7" 3 "LESS_OR_EQ_10" 4 "LESS_OR_EQ_15" 5 "LESS_OR_EQ_20" 6 "LESS_OR_EQ_25" 7 "LESS_OR_EQ_30" 8 "LESS_OR_EQ_35" 9 "LESS_OR_EQ_40" 10 "LESS_OR_EQ_45" 11 "LESS_OR_EQ_50" 12 "LESS_OR_EQ_55" 13 "LESS_OR_EQ_60" 14 "LESS_OR_EQ_65" 15 "LESS_OR_EQ_70" 16 "LESS_OR_EQ_75" 17 "LESS_OR_EQ_80" 18 "LESS_OR_EQ_85" 19 "LESS_OR_EQ_90" 20 "LESS_OR_EQ_95" 21 "LESS_OR_EQ_100" 22 "LESS_OR_EQ_105" 23 "LESS_OR_EQ_110" 24 "LESS_OR_EQ_115" 25 "LESS_OR_EQ_120" 26 "LESS_OR_EQ_130" 27 "LESS_OR_EQ_140" 28 "LESS_OR_EQ_150" 29 "LESS_OR_EQ_160" 30 "UNLIMITED" 31 "SNA";
VAL_ 568 UI_mapSpeedLimitDependency 0 "NONE" 1 "SCHOOL" 2 "RAIN" 3 "SNOW" 4 "TIME" 5 "SEASON" 6 "LANE" 7 "SNA";
VAL_ 568 UI_mapSpeedLimitType 1 "REGULAR" 2 "ADVISORY" 3 "DEPENDENT" 4 "BUMPS" 7 "UNKNOWN_SNA";
VAL_ 568 UI_mapSpeedUnits 0 "MPH" 1 "KPH";
VAL_ 568 UI_nextBranchDist 31 "SNA";
VAL_ 568 UI_roadClass 0 "UNKNOWN_INVALID_SNA" 1 "CLASS_1_MAJOR" 2 "CLASS_2" 3 "CLASS_3" 4 "CLASS_4" 5 "CLASS_5" 6 "CLASS_6_MINOR";

VAL_ 645 UI_driverProfileRecallIndex 0 "SNA" 1 "1" 2 "2" 3 "3" 4 "4" 5 "5";
VAL_ 645 UI_leftBackrestSwitchUp 0 "SNA" 1 "OFF" 2 "ON" 3 "FAULT";
VAL_ 645 UI_leftBackrestSwitchDown 0 "SNA" 1 "OFF" 2 "ON" 3 "FAULT";
VAL_ 645 UI_leftLiftSwitchUp 0 "SNA" 1 "OFF" 2 "ON" 3 "FAULT";
VAL_ 645 UI_leftLiftSwitchDown 0 "SNA" 1 "OFF" 2 "ON" 3 "FAULT";
VAL_ 645 UI_rightBackrestSwitchUp 0 "SNA" 1 "OFF" 2 "ON" 3 "FAULT";
VAL_ 645 UI_rightBackrestSwitchDown 0 "SNA" 1 "OFF" 2 "ON" 3 "FAULT";
VAL_ 645 UI_rightLiftSwitchUp 0 "SNA" 1 "OFF" 2 "ON" 3 "FAULT";
VAL_ 645 UI_rightLiftSwitchDown 0 "SNA" 1 "OFF" 2 "ON" 3 "FAULT";

VAL_ 985 UI_mapSpeedLimitUnits 0 "MPH" 1 "KPH";
VAL_ 985 UI_userSpeedOffsetUnits 0 "MPH" 1 "KPH";

VAL_ 79 UI_gpsAccuracy 127 "SNA";

VAL_ 1011 UI_odometer 16777215 "SNA";

VAL_ 787 UI_creepTorque 0 "OFF" 1 "ON";
VAL_ 787 UI_limitMode 0 "NORMAL" 1 "VALET" 2 "FACTORY";
VAL_ 787 UI_motorOnMode 0 "NORMAL" 1 "FRONT_ONLY" 2 "REAR_ONLY";
VAL_ 787 UI_pedalMap 0 "CHILL" 1 "SPORT";
VAL_ 787 UI_speedLimit 255 "SNA";
VAL_ 787 UI_systemPowerLimit 31 "SNA";
VAL_ 787 UI_systemTorqueLimit 63 "SNA";
VAL_ 787 UI_trackModeRequest 0 "IDLE" 1 "ON" 2 "OFF";
VAL_ 787 UI_wasteMode 0 "NONE" 1 "PARTIAL" 2 "FULL";
VAL_ 787 UI_wasteModeRegenLimit 0 "MAX" 1 "30A" 2 "10A" 3 "0A";

VAL_ 698 UI_radarTargetDx 255 "NO_OBJECT";
VAL_ 698 UI_radarTargetDxEnd 255 "NO_OBJECT";
CM_ BO_ 291 "ESP32-DualCAN Model3_VEH. Seen on this car: 8-byte frames; fit good (bits covered 100%, mux 100%, ranges 100%).";
VAL_ 291 VCRIGHT_rearDoorState 0 "UNKNOWN" 1 "CLOSED" 2 "WAIT_FOR_SHORT_DROP" 3 "RELEASING_LATCH" 4 "OPEN" 5 "AJAR" 6 "INIT" ;
VAL_ 291 VCRIGHT_frontDoorState 0 "UNKNOWN" 1 "CLOSED" 2 "WAIT_FOR_SHORT_DROP" 3 "RELEASING_LATCH" 4 "OPEN" 5 "AJAR" 6 "INIT" ;
CM_ BO_ 297 "ESP32-DualCAN Model3_VEH. Seen on this car: 8-byte frames; fit good (bits covered 100%, mux 100%, ranges 100%). read by the app or firmware.";
VAL_ 297 SCCM_steeringAngleValidity 0 "INVALID" 1 "VALID" 2 "INIT" 3 "SNA" ;
VAL_ 297 SCCM_steeringAngle 16383 "SNA" ;
VAL_ 297 SCCM_steeringAngleSensorStatus 0 "OK" 1 "INIT" 2 "ERROR" 3 "ERROR_INIT" ;
CM_ BO_ 526 "ESP32-DualCAN Model3_VEH. Seen on this car: 3-byte frames; fit ok (bits covered 100%, mux 100%, ranges 100%, checksum 100%).";
CM_ BO_ 536 "ESP32-DualCAN Model3_VEH. Seen on this car: 5-byte frames; fit ok (bits covered 100%, mux 100%, ranges 100%, checksum 100%).";
CM_ BO_ 553 "ESP32-DualCAN Model3_VEH. Seen on this car: 3-byte frames; fit ok (bits covered 100%, mux 100%, ranges 100%).";
VAL_ 553 SCCM_parkButtonStatus 0 "NOT_PRESSED" 1 "PRESSED" 2 "INIT" 3 "SNA" ;
VAL_ 553 SCCM_rightStalkStatus 0 "IDLE" 1 "UP_1" 2 "UP_2" 3 "DOWN_1" 4 "DOWN_2" 5 "INIT" 6 "SNA" ;
CM_ BO_ 585 "ESP32-DualCAN Model3_VEH. Seen on this car: 4-byte frames; fit ok (bits covered 100%, mux 100%, ranges 100%). read by the app or firmware.";
VAL_ 585 SCCM_turnIndicatorStalkStatus 0 "IDLE" 1 "UP_0_5" 2 "UP_1" 3 "UP_1_5" 4 "UP_2" 5 "DOWN_0_5" 6 "DOWN_1" 7 "DOWN_1_5" 8 "DOWN_2" 9 "SNA" ;
VAL_ 585 SCCM_washWipeButtonStatus 0 "NOT_PRESSED" 1 "1ST_DETENT" 2 "2ND_DETENT" 3 "SNA" ;
VAL_ 585 SCCM_highBeamStalkStatus 0 "IDLE" 1 "PULL" 2 "PUSH" 3 "SNA" ;
CM_ BO_ 602 "ESP32-DualCAN Model3_VEH. Seen on this car: 6-byte frames; fit ok (bits covered 100%, mux 100%, ranges 100%).";
VAL_ 602 VCSEC_TPMSDisplayHardWarningIndicationRR 0 "NOT_INDICATED" 1 "INDICATED" ;
VAL_ 602 VCSEC_TPMSDisplayHardWarningIndicationRL 0 "NOT_INDICATED" 1 "INDICATED" ;
VAL_ 602 VCSEC_TPMSDisplayHardWarningIndicationFR 0 "NOT_INDICATED" 1 "INDICATED" ;
VAL_ 602 VCSEC_TPMSDisplayHardWarningIndicationFL 0 "NOT_INDICATED" 1 "INDICATED" ;
VAL_ 602 VCSEC_TPMSDisplaySoftWarningIndicationRR 0 "NOT_INDICATED" 1 "INDICATED" ;
VAL_ 602 VCSEC_TPMSDisplaySoftWarningIndicationRL 0 "NOT_INDICATED" 1 "INDICATED" ;
VAL_ 602 VCSEC_TPMSDisplaySoftWarningIndicationFR 0 "NOT_INDICATED" 1 "INDICATED" ;
VAL_ 602 VCSEC_TPMSDisplaySoftWarningIndicationFL 0 "NOT_INDICATED" 1 "INDICATED" ;
VAL_ 602 VCSEC_TPMSTellTale 0 "OFF" 1 "SOLID" 2 "FLASHING" ;
VAL_ 602 VCSEC_TPMSDisplayPressureRR 255 "SNA" ;
VAL_ 602 VCSEC_TPMSDisplayPressureRL 255 "SNA" ;
VAL_ 602 VCSEC_TPMSDisplayPressureFR 255 "SNA" ;
VAL_ 602 VCSEC_TPMSDisplayPressureFL 255 "SNA" ;
CM_ BO_ 664 "ESP32-DualCAN Model3_VEH. Seen on this car: 4-byte frames; fit ok (bits covered 100%, mux 100%, ranges 100%).";
CM_ BO_ 676 "ESP32-DualCAN Model3_VEH. Seen on this car: 8-byte frames; fit good (bits covered 100%, mux 100%, ranges 100%).";
VAL_ 676 PCS_dcdcBusbarTemp 511 "SNA" ;
VAL_ 676 PCS_ambientTemp 4294966273 "SNA" ;
VAL_ 676 PCS_dcdcTemp 4294966273 "SNA" ;
VAL_ 676 PCS_chgPhCTemp 4294966273 "SNA" ;
VAL_ 676 PCS_chgPhBTemp 4294966273 "SNA" ;
VAL_ 676 PCS_chgPhATemp 4294966273 "SNA" ;
CM_ BO_ 679 "ESP32-DualCAN Model3_VEH. Seen on this car: 8-byte frames; fit good (bits covered 100%, mux 100%, ranges 100%).";
VAL_ 679 CMPD_wasteHeatState 0 "OFF" 1 "ACTIVE" 2 "NOT_AVAILABLE" 3 "UNUSED" ;
VAL_ 679 CMPD_state 0 "INIT" 1 "RUNNING" 2 "STANDBY" 3 "FAULT" 4 "IDLE" 15 "SNA" ;
CM_ BO_ 692 "ESP32-DualCAN Model3_VEH. Seen on this car: 6-byte frames; fit ok (bits covered 100%, mux 100%, ranges 100%).";
CM_ BO_ 755 "ESP32-DualCAN Model3_VEH. Seen on this car: 8-byte frames; fit good (bits covered 100%, mux 100%, ranges 100%). read by the app or firmware.";
VAL_ 755 UI_hvacReqKeepClimateOn 0 "OFF" 1 "ON" 2 "DOG" 3 "PARTY" ;
VAL_ 755 UI_hvacReqSecondRowState 0 "AUTO" 1 "OFF" 2 "LOW" 3 "MED" 4 "HIGH" ;
VAL_ 755 UI_hvacReqUserPowerState 0 "OFF" 1 "ON" 2 "PRECONDITION" 3 "OVERHEAT_PROTECT_FANONLY" 4 "OVERHEAT_PROTECT" ;
VAL_ 755 UI_hvacReqACDisable 0 "AUTO" 1 "OFF" 2 "ON" ;
VAL_ 755 UI_hvacReqRecirc 0 "AUTO" 1 "RECIRC" 2 "FRESH" ;
VAL_ 755 UI_hvacReqBlowerSegment 0 "OFF" 1 "1" 2 "2" 3 "3" 4 "4" 5 "5" 6 "6" 7 "7" 8 "8" 9 "9" 10 "10" 11 "AUTO" ;
VAL_ 755 UI_hvacReqAirDistributionMode 0 "AUTO" 1 "MANUAL_FLOOR" 2 "MANUAL_PANEL" 3 "MANUAL_PANEL_FLOOR" 4 "MANUAL_DEFROST" 5 "MANUAL_DEFROST_FLOOR" 6 "MANUAL_DEFROST_PANEL" 7 "MANUAL_DEFROST_PANEL_FLOOR" ;
VAL_ 755 UI_hvacReqTempSetpointRight 0 "LO" 26 "HI" ;
VAL_ 755 UI_hvacReqTempSetpointLeft 0 "LO" 26 "HI" ;
CM_ BO_ 771 "ESP32-DualCAN Model3_VEH. Seen on this car: 8-byte frames; fit good (bits covered 100%, mux 100%, ranges 100%).";
VAL_ 771 VCRIGHT_infoAssemblyId 1 "ASSEMBLY1" 255 "ASSEMBLY_SNA" ;
VAL_ 771 VCRIGHT_infoBuildType 0 "UNKNOWN_BUILD" 1 "PLATFORM_BUILD" 2 "LOCAL_BUILD" 3 "TRACEABLE_CI_BUILD" 4 "MFG_BUILD" ;
VAL_ 771 VCRIGHT_infoIndex 0 "DEPRECATED_0" 1 "DEPRECATED_1" 2 "DEPRECATED_2" 3 "DEPRECATED_3" 4 "DEPRECATED_4" 5 "DEPRECATED_5" 6 "DEPRECATED_6" 7 "DEPRECATED_7" 8 "DEPRECATED_8" 9 "DEPRECATED_9" 10 "BUILD_HWID_COMPONENTID" 11 "PCBAID_ASSYID_USAGEID" 13 "APP_CRC" 14 "BOOTLOADER_SVN" 15 "BOOTLOADER_CRC" 16 "SUBCOMPONENT1" 17 "APP_GITHASH" 18 "BOOTLOADER_GITHASH" 19 "VERSION_DEPRECATED" 20 "UDS_PROTOCOL_BOOTCRC" 23 "SUBCOMPONENT2" 24 "SUBCOMPONENT3" 31 "SUBCOMPONENT4" 32 "SUBCOMPONENT5" 33 "SUBCOMPONENT6" 34 "SUBCOMPONENT7" 35 "SUBCOMPONENT8" 36 "SUBCOMPONENT9" 37 "SUBCOMPONENT10" 38 "SUBCOMPONENT11" 39 "SUBCOMPONENT12" 40 "SUBCOMPONENT13" 41 "SUBCOMPONENT14" 255 "END" ;
CM_ BO_ 816 "ESP32-DualCAN Model3_VEH. Seen on this car: 8-byte frames; fit ok (bits covered 100%, mux 100%, ranges 100%).";
VAL_ 816 SCCM_infoAssemblyId 1 "ASSEMBLY1" 255 "ASSEMBLY_SNA" ;
VAL_ 816 SCCM_infoBuildType 0 "UNKNOWN_BUILD" 1 "PLATFORM_BUILD" 2 "LOCAL_BUILD" 3 "TRACEABLE_CI_BUILD" 4 "MFG_BUILD" ;
VAL_ 816 SCCM_infoIndex 10 "BUILD_HWID_COMPONENTID" 11 "PCBAID_ASSYID_USAGEID" 13 "APP_CRC" 14 "BOOTLOADER_SVN" 16 "SUBCOMPONENT1" 17 "APP_SVNHASH" 18 "BOOTLOADER_SVNHASH" 20 "UDS_PROTOCOL_BOOTCRC" 255 "END" ;
CM_ BO_ 819 "ESP32-DualCAN Model3_VEH. Seen on this car: 5-byte frames; fit poor (bits covered 0%, mux 100%, ranges 100%). read by the app or firmware.";
VAL_ 819 UI_acChargeCurrentLimit 127 "SNA" ;
VAL_ 819 UI_brickBalancingDisabled 0 "FALSE" 1 "TRUE" ;
VAL_ 819 UI_brickVLoggingRequest 0 "FALSE" 1 "TRUE" ;
CM_ BO_ 909 "ESP32-DualCAN Model3_VEH. Seen on this car: 8-byte frames; fit good (bits covered 100%, mux 100%, ranges 100%).";
CM_ BO_ 925 "ESP32-DualCAN Model3_VEH. Seen on this car: 5-byte frames; fit ok (bits covered 100%, mux 100%, ranges 100%, checksum 100%).";
VAL_ 925 IBST_internalState 0 "NO_MODE_ACTIVE" 1 "PRE_DRIVE_CHECK" 2 "LOCAL_BRAKE_REQUEST" 3 "EXTERNAL_BRAKE_REQUEST" 4 "DIAGNOSTIC" 5 "TRANSITION_TO_IDLE" 6 "POST_DRIVE_CHECK" ;
VAL_ 925 IBST_driverBrakeApply 0 "NOT_INIT_OR_OFF" 1 "BRAKES_NOT_APPLIED" 2 "DRIVER_APPLYING_BRAKES" 3 "FAULT" ;
VAL_ 925 IBST_iBoosterStatus 0 "OFF" 1 "INIT" 2 "FAILURE" 3 "DIAGNOSTIC" 4 "ACTIVE_GOOD_CHECK" 5 "READY" 6 "ACTUATION" ;
CM_ BO_ 941 "ESP32-DualCAN Model3_VEH. Seen on this car: 8-byte frames; fit good (bits covered 100%, mux 100%, ranges 100%).";
VAL_ 941 ICR_infoAssemblyId 1 "ASSEMBLY1" 255 "ASSEMBLY_SNA" ;
VAL_ 941 ICR_infoBuildType 0 "UNKNOWN_BUILD" 1 "PLATFORM_BUILD" 2 "LOCAL_BUILD" 3 "TRACEABLE_CI_BUILD" 4 "MFG_BUILD" ;
VAL_ 941 ICR_infoIndex 0 "DEPRECATED_0" 1 "DEPRECATED_1" 2 "DEPRECATED_2" 3 "DEPRECATED_3" 4 "DEPRECATED_4" 5 "DEPRECATED_5" 6 "DEPRECATED_6" 7 "DEPRECATED_7" 8 "DEPRECATED_8" 9 "DEPRECATED_9" 10 "BUILD_HWID_COMPONENTID" 11 "PCBAID_ASSYID_USAGEID" 13 "APP_CRC" 14 "BOOTLOADER_SVN" 15 "BOOTLOADER_CRC" 16 "SUBCOMPONENT" 17 "APP_GITHASH" 18 "BOOTLOADER_GITHASH" 19 "VERSION_DEPRECATED" 20 "UDS_PROTOCOL_BOOTCRC" 22 "VARIANTCRC" 25 "PACKAGE_PN_1_7" 26 "PACKAGE_PN_8_14" 27 "PACKAGE_PN_15_20" 29 "PACKAGE_SN_1_7" 30 "PACKAGE_SN_8_14" 31 "SUBCOMPONENT_GITHASH" 255 "END" ;
CM_ BO_ 979 "ESP32-DualCAN Model3_VEH. Seen on this car: 3-byte frames; fit poor (bits covered 0%, mux 100%, ranges 100%).";
VAL_ 979 VCRIGHT_crashState 0 "IDLE" 1 "MINOR_1" 2 "MINOR_2" 3 "SEVERE" ;
VAL_ 979 VCRIGHT_crashDetectedType 0 "NONE" 1 "MINOR_1" 2 "MINOR_2" 3 "SEVERE" ;
CM_ BO_ 984 "ESP32-DualCAN Model3_VEH. Seen on this car: 4-byte frames; fit ok (bits covered 100%, mux 100%, ranges 100%).";
VAL_ 984 UI_elevation 8191 "SNA" ;
CM_ BO_ 1096 "ESP32-DualCAN Model3_VEH. Seen on this car: 7-byte frames; fit ok (bits covered 100%, mux 100%, ranges 100%).";
VAL_ 1096 EPBR_nmDebugWakeUp 2147483648 "31" 1073741824 "30" 536870912 "29" 268435456 "28" 134217728 "27" 67108864 "26" 33554432 "25" 16777216 "24" 0 "NONE" 256 "8" 512 "9" 1024 "10" 2048 "11" 4096 "12" 8192 "13" 16384 "14" 32768 "15" 1 "0" 65536 "16" 2 "1" 131072 "17" 4 "2" 262144 "18" 8 "3" 524288 "19" 16 "4" 1048576 "20" 32 "5" 2097152 "21" 64 "6" 4194304 "22" 128 "7" 8388608 "23" ;
VAL_ 1096 EPBR_nmWakeUpReason 0 "NONE" 1 "CAN_VEH" 2 "CAN_HVS" 3 "WANTTOCHARGE" 4 "CRITICALALERT" 5 "WANTTOWARM" ;
VAL_ 1096 EPBR_nmKeepAwakeReason 0 "NONE_SNA" 1 "CTRS_CLOSED" 2 "CRITICAL_ALERT" 3 "FC_CTR_CLEANING" 4 "HVP_ACTIVE" 5 "BMS_ACTIVE" 6 "CP_ACTIVE" ;
CM_ BO_ 1139 "ESP32-DualCAN Model3_VEH. Seen on this car: 8-byte frames; fit good (bits covered 100%, mux 100%, ranges 100%).";
VAL_ 1139 UI_nmKeepAwakeReason 0 "NONE_SNA" 1 "KEEPALIVEACTIVE" 2 "GUI_NEVER_SLEEP_SET" 3 "PM_CHECKING" 4 "UNKNOWN_REMOTE_REQUEST" 5 "MODEM_RESET" 6 "UPDATER" 7 "HERMES" 8 "AUTOFUSER" 9 "UPDATE_COUNTDOWN" 10 "ECALL_ACTIVE" 11 "SELFTEST" 12 "SENTRY_MODE" 13 "MEDIA_DOWNLOAD" 14 "ODIN" 15 "MULTIPLE" ;
CM_ BO_ 1523 "ESP32-DualCAN Model3_VEH. Seen on this car: 3-byte frames; fit ok (bits covered 100%, mux 100%, ranges 100%).";
VAL_ 1523 UI_odometer 16777215 "SNA" ;
CM_ BO_ 1748 "ESP32-DualCAN Model3_VEH. Seen on this car: 8-byte frames; fit good (bits covered 100%, mux 100%, ranges 100%).";
VAL_ 1748 PMR_hardwareId 252 "CONFIGURABLE_HWID_PLACEHOLDER" ;
VAL_ 1748 PMR_buildType 0 "UNKNOWN_BUILD" 1 "PLATFORM_BUILD" 2 "LOCAL_BUILD" 3 "TRACEABLE_CI_BUILD" 4 "MFG_BUILD" ;
VAL_ 1748 PMR_infoIndex 0 "DEPRECATED_0" 1 "DEPRECATED_1" 2 "DEPRECATED_2" 3 "DEPRECATED_3" 4 "DEPRECATED_4" 5 "DEPRECATED_5" 6 "DEPRECATED_6" 7 "DEPRECATED_7" 8 "DEPRECATED_8" 9 "DEPRECATED_9" 10 "BUILD_HWID_COMPONENTID" 11 "PCBAID_ASSYID_USAGEID" 13 "APP_CRC" 14 "BOOTLOADER_SVN" 15 "BOOTLOADER_CRC" 16 "SUBCOMPONENT" 17 "APP_GITHASH" 18 "BOOTLOADER_GITHASH" 19 "VERSION_DEPRECATED" 20 "UDS_PROTOCOL_BOOTCRC" 21 "DI_BUILD_DATA" 255 "END" ;
